VERSION ""

NS_ :

BS_:

BU_: SVB1 Tester Gateway CDS1 CDS2 ADV IRC AVP AVM PDC ADB1 ADB2 HDMAP DSM Fradar LCDA1 LCDA2

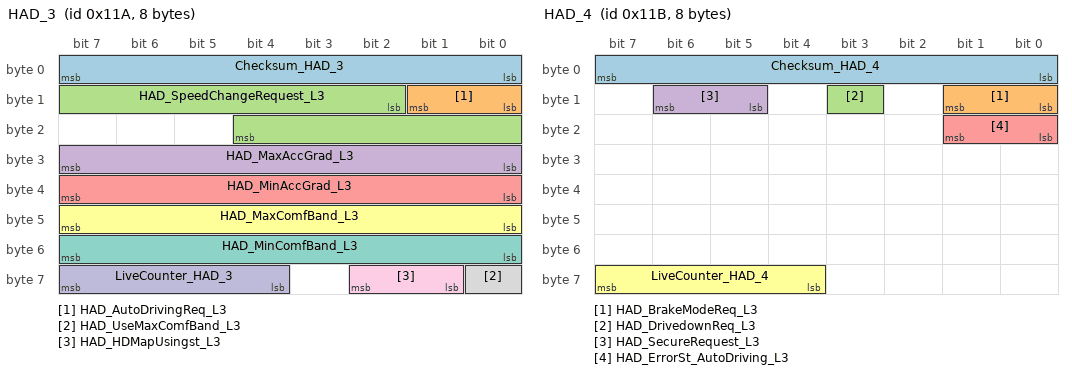
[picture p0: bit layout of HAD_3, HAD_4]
BO_ 282 HAD_3: 8 CDS1
 SG_ Checksum_HAD_3 : 0|8@1+ (1,0) [0|255] ""  Gateway,CDS2,HDMAP
 SG_ HAD_AutoDrivingReq_L3 : 8|2@1+ (1,0) [0|3] ""  Gateway,CDS2,HDMAP
 SG_ HAD_SpeedChangeRequest_L3 : 10|11@1+ (0.01,-10.21) [-10.21|10.26] "m/s2"  Gateway,CDS2,HDMAP
 SG_ HAD_MaxAccGrad_L3 : 24|8@1+ (0.1,0) [0|25.5] "m/s2"  Gateway,CDS2
 SG_ HAD_MinAccGrad_L3 : 32|8@1+ (0.1,0) [0|25.5] "m/s2"  Gateway,CDS2
 SG_ HAD_MaxComfBand_L3 : 40|8@1+ (0.05,0) [0|12.75] "/s2"  Gateway,CDS2
 SG_ HAD_MinComfBand_L3 : 48|8@1+ (0.05,0) [0|12.75] "/s2"  Gateway,CDS2
 SG_ HAD_UseMaxComfBand_L3 : 56|1@1+ (1,0) [0|1] ""  Gateway,CDS2
 SG_ HAD_HDMapUsingst_L3 : 57|2@1+ (1,0) [0|3] ""  HDMAP
 SG_ LiveCounter_HAD_3 : 60|4@1+ (1,0) [0|15] ""  Gateway,CDS2,HDMAP

BO_ 283 HAD_4: 8 CDS1
 SG_ Checksum_HAD_4 : 0|8@1+ (1,0) [0|255] ""  Gateway,CDS2,HDMAP
 SG_ HAD_BrakeModeReq_L3 : 8|2@1+ (1,0) [0|3] ""  Gateway,CDS2
 SG_ HAD_DrivedownReq_L3 : 11|1@1+ (1,0) [0|1] ""  Gateway,CDS2
 SG_ HAD_SecureRequest_L3 : 13|2@1+ (1,0) [0|3] ""  Gateway,CDS2
 SG_ HAD_ErrorSt_AutoDriving_L3 : 16|2@1+ (1,0) [0|3] ""  Gateway,CDS2
 SG_ LiveCounter_HAD_4 : 60|4@1+ (1,0) [0|15] ""  Gateway,CDS2,HDMAP

BO_ 278 HAD_6: 8 CDS1
 SG_ Checksum_HAD_6 : 0|8@1+ (1,0) [0|255] ""  Gateway,CDS2
 SG_ HAD_TorqueRequest : 8|10@1+ (0.01,0) [0|10.23] "Nm"  Gateway,CDS2
 SG_ HAD_TorqueRequestSign : 18|1@1+ (1,0) [0|1] ""  Gateway,CDS2
 SG_ HAD_TorqueReqSt : 19|1@1+ (1,0) [0|1] ""  Gateway,CDS2
 SG_ HAD_Intervention_LKA : 20|2@1+ (1,0) [0|3] ""  Gateway,CDS2
 SG_ HAD_WorkingSt_LKA : 22|2@1+ (1,0) [0|3] ""  Gateway,CDS2
 SG_ HAD_ErrorSt_LKA : 24|1@1+ (1,0) [0|1] ""  Gateway,CDS2
 SG_ HAD_TakeOverTip_LCA : 25|1@1+ (1,0) [0|1] ""  Gateway,CDS2
 SG_ HAD_HandsOffTip_LCA : 26|2@1+ (1,0) [0|3] ""  Gateway,CDS2
 SG_ HAD_WorkingSt_LCA : 28|3@1+ (1,0) [0|7] ""  Gateway,CDS2
 SG_ HAD_ErrorSt_LCA : 31|1@1+ (1,0) [0|1] ""  Gateway,CDS2
 SG_ HAD_AutoDrivingModeReq : 32|3@1+ (1,0) [0|7] ""  Gateway,CDS2
 SG_ HAD_ErrorSt_SACC : 40|2@1+ (1,0) [0|3] ""  Gateway,CDS2
 SG_ HAD_ErrorSt_HWP : 42|2@1+ (1,0) [0|3] ""  Gateway,CDS2
 SG_ HAD_ErrorSt_TJP : 44|2@1+ (1,0) [0|3] ""  Gateway,CDS2
 SG_ HAD_LDWSteeringVibrationReq : 47|1@1+ (1,0) [0|1] ""  Gateway,CDS2
 SG_ HAD_WorkingSt_DCLC : 50|3@1+ (1,0) [0|7] ""  Gateway,CDS2
 SG_ HAD_WorkingSt_HWP : 53|3@1+ (1,0) [0|7] ""  Gateway,CDS2
 SG_ HAD_WorkingSt_TJP : 56|3@1+ (1,0) [0|7] ""  Gateway,CDS2
 SG_ HAD_ErrorSt_HAD : 59|1@1+ (1,0) [0|1] ""  Gateway,CDS2
 SG_ LiveCounter_HAD_6 : 60|4@1+ (1,0) [0|15] ""  Gateway,CDS2

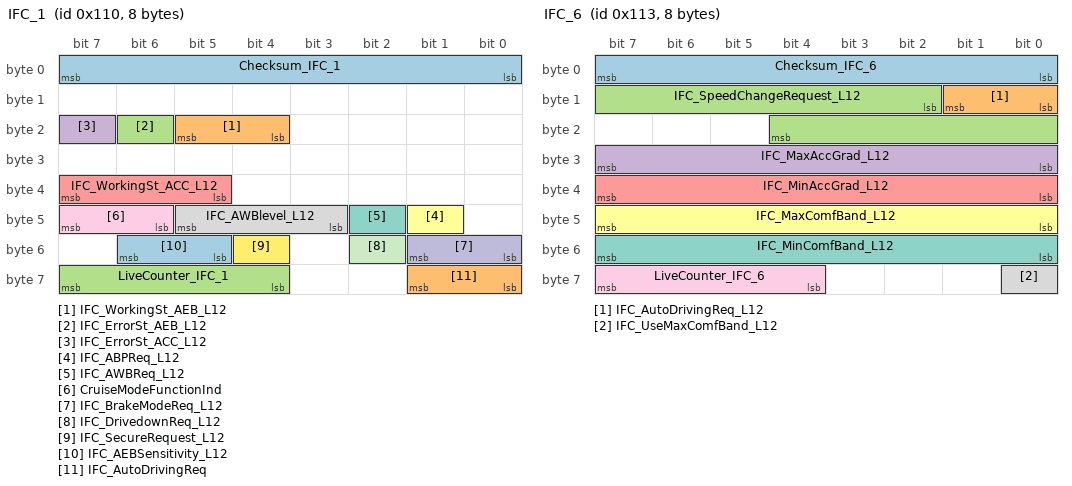
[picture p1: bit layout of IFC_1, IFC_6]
BO_ 272 IFC_1: 8 CDS2
 SG_ Checksum_IFC_1 : 0|8@1+ (1,0) [0|255] ""  Gateway,ADV
 SG_ IFC_WorkingSt_AEB_L12 : 20|2@1+ (1,0) [0|3] ""  Gateway
 SG_ IFC_ErrorSt_AEB_L12 : 22|1@1+ (1,0) [0|1] ""  Gateway,ADV
 SG_ IFC_ErrorSt_ACC_L12 : 23|1@1+ (1,0) [0|1] ""  Gateway
 SG_ IFC_WorkingSt_ACC_L12 : 37|3@1+ (1,0) [0|7] ""  Gateway,ADV
 SG_ IFC_ABPReq_L12 : 41|1@1+ (1,0) [0|1] ""  Gateway
 SG_ IFC_AWBReq_L12 : 42|1@1+ (1,0) [0|1] ""  Gateway
 SG_ IFC_AWBlevel_L12 : 43|3@1+ (1,0) [0|7] ""  Gateway
 SG_ CruiseModeFunctionInd : 46|2@1+ (1,0) [0|3] ""  Gateway
 SG_ IFC_BrakeModeReq_L12 : 48|2@1+ (1,0) [0|3] ""  Gateway
 SG_ IFC_DrivedownReq_L12 : 50|1@1+ (1,0) [0|1] ""  Gateway
 SG_ IFC_SecureRequest_L12 : 52|1@1+ (1,0) [0|1] ""  Gateway
 SG_ IFC_AEBSensitivity_L12 : 53|2@1+ (1,0) [0|3] ""  Gateway
 SG_ IFC_AutoDrivingReq : 56|2@1+ (1,0) [0|3] ""  Gateway
 SG_ LiveCounter_IFC_1 : 60|4@1+ (1,0) [0|15] ""  Gateway,ADV

BO_ 275 IFC_6: 8 CDS2
 SG_ Checksum_IFC_6 : 0|8@1+ (1,0) [0|255] ""  Gateway
 SG_ IFC_AutoDrivingReq_L12 : 8|2@1+ (1,0) [0|3] ""  Gateway
 SG_ IFC_SpeedChangeRequest_L12 : 10|11@1+ (0.01,-10.21) [-10.21|10.26] "m/s2"  Gateway
 SG_ IFC_MaxAccGrad_L12 : 24|8@1+ (0.1,0) [0|25.5] "m/s2"  Gateway
 SG_ IFC_MinAccGrad_L12 : 32|8@1+ (0.1,0) [0|25.5] "m/s2"  Gateway
 SG_ IFC_MaxComfBand_L12 : 40|8@1+ (0.05,0) [0|12.75] "/s2"  Gateway
 SG_ IFC_MinComfBand_L12 : 48|8@1+ (0.05,0) [0|12.75] "/s2"  Gateway
 SG_ IFC_UseMaxComfBand_L12 : 56|1@1+ (1,0) [0|1] ""  Gateway
 SG_ LiveCounter_IFC_6 : 60|4@1+ (1,0) [0|15] ""  Gateway

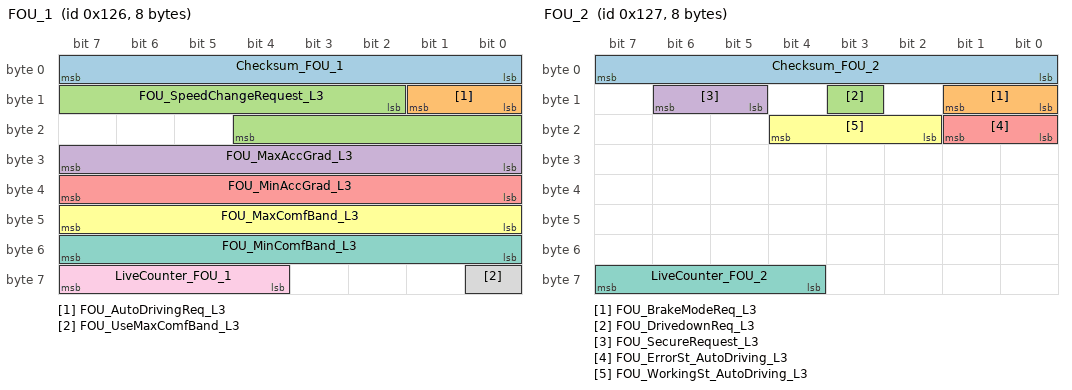
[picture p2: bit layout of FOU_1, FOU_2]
BO_ 294 FOU_1: 8 CDS2
 SG_ Checksum_FOU_1 : 0|8@1+ (1,0) [0|255] ""  Gateway,CDS1
 SG_ FOU_AutoDrivingReq_L3 : 8|2@1+ (1,0) [0|3] ""  Gateway,CDS1
 SG_ FOU_SpeedChangeRequest_L3 : 10|11@1+ (0.01,-10.21) [-10.21|10.26] "m/s2"  Gateway,CDS1
 SG_ FOU_MaxAccGrad_L3 : 24|8@1+ (0.1,0) [0|25.5] "m/s2"  Gateway,CDS1
 SG_ FOU_MinAccGrad_L3 : 32|8@1+ (0.1,0) [0|25.5] "m/s2"  Gateway,CDS1
 SG_ FOU_MaxComfBand_L3 : 40|8@1+ (0.05,0) [0|12.75] "/s2"  Gateway,CDS1
 SG_ FOU_MinComfBand_L3 : 48|8@1+ (0.05,0) [0|12.75] "/s2"  Gateway,CDS1
 SG_ FOU_UseMaxComfBand_L3 : 56|1@1+ (1,0) [0|1] ""  Gateway,CDS1
 SG_ LiveCounter_FOU_1 : 60|4@1+ (1,0) [0|15] ""  Gateway,CDS1

BO_ 295 FOU_2: 8 CDS2
 SG_ Checksum_FOU_2 : 0|8@1+ (1,0) [0|255] ""  Gateway,CDS1
 SG_ FOU_BrakeModeReq_L3 : 8|2@1+ (1,0) [0|3] ""  Gateway,CDS1
 SG_ FOU_DrivedownReq_L3 : 11|1@1+ (1,0) [0|1] ""  Gateway,CDS1
 SG_ FOU_SecureRequest_L3 : 13|2@1+ (1,0) [0|3] ""  Gateway,CDS1
 SG_ FOU_ErrorSt_AutoDriving_L3 : 16|2@1+ (1,0) [0|3] ""  Gateway,CDS1
 SG_ FOU_WorkingSt_AutoDriving_L3 : 18|3@1+ (1,0) [0|7] ""  Gateway,CDS1
 SG_ LiveCounter_FOU_2 : 60|4@1+ (1,0) [0|15] ""  Gateway,CDS1

BO_ 274 IFC_4: 8 CDS2
 SG_ Checksum_IFC_4 : 0|8@1+ (1,0) [0|255] ""  Gateway,CDS1,ADV
 SG_ IFC_TorqueRequest : 8|10@1+ (0.01,0) [0|10.23] "Nm"  Gateway,CDS1
 SG_ IFC_TorqueRequestSign : 18|1@1+ (1,0) [0|1] ""  Gateway,CDS1
 SG_ IFC_TorqueReqSt : 19|1@1+ (1,0) [0|1] ""  Gateway,CDS1
 SG_ IFC_Intervention_LKA : 20|2@1+ (1,0) [0|3] ""  Gateway,CDS1
 SG_ IFC_WorkingSt_LKA : 22|2@1+ (1,0) [0|3] ""  Gateway,CDS1,ADV
 SG_ IFC_ErrorSt_LKA : 24|1@1+ (1,0) [0|1] ""  Gateway,CDS1
 SG_ IFC_TakeOverTip_LCA : 25|1@1+ (1,0) [0|1] ""  Gateway,CDS1
 SG_ IFC_HandsOffTip_LCA : 26|2@1+ (1,0) [0|3] ""  Gateway,CDS1
 SG_ IFC_WorkingSt_LCA : 28|3@1+ (1,0) [0|7] ""  Gateway,CDS1,ADV
 SG_ IFC_ErrorSt_LCA : 31|1@1+ (1,0) [0|1] ""  Gateway,CDS1
 SG_ IFC_AutoDrivingModeReq : 32|3@1+ (1,0) [0|7] ""  Gateway,CDS1
 SG_ IFC_ErrorSt_SACC : 40|2@1+ (1,0) [0|3] ""  Gateway,CDS1
 SG_ FOU_ErrorSt_HWP : 42|2@1+ (1,0) [0|3] ""  Gateway,CDS1
 SG_ FOU_ErrorSt_TJP : 44|2@1+ (1,0) [0|3] ""  Gateway,CDS1
 SG_ LDWSteeringVibrationReq : 47|1@1+ (1,0) [0|1] ""  Gateway,CDS1
 SG_ IFC_WorkingSt_SACC : 50|3@1+ (1,0) [0|7] ""  Gateway,CDS1,ADV
 SG_ FOU_WorkingSt_HWP : 53|3@1+ (1,0) [0|7] ""  Gateway,CDS1
 SG_ FOU_WorkingSt_TJP : 56|3@1+ (1,0) [0|7] ""  Gateway,CDS1
 SG_ IFC_ErrorSt_FOU : 59|1@1+ (1,0) [0|1] ""  Gateway
 SG_ LiveCounter_IFC_4 : 60|4@1+ (1,0) [0|15] ""  Gateway,CDS1,ADV

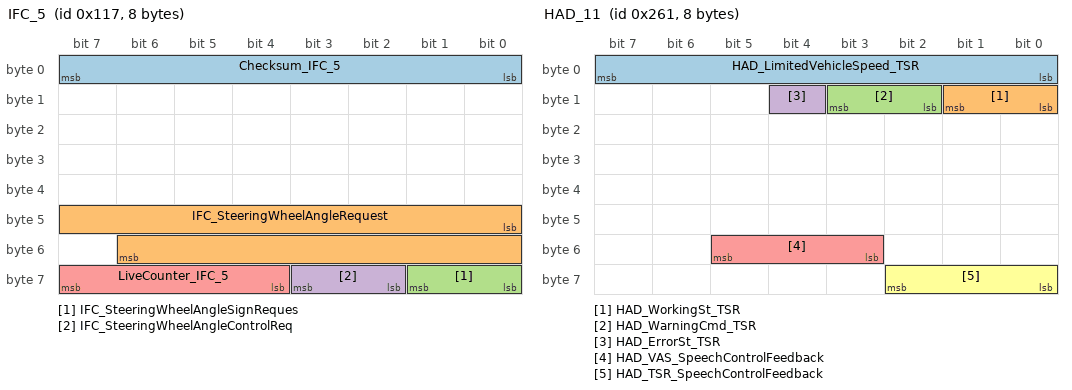
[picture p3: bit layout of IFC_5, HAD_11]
BO_ 279 IFC_5: 8 CDS2
 SG_ Checksum_IFC_5 : 0|8@1+ (1,0) [0|255] ""  Gateway,CDS1
 SG_ IFC_SteeringWheelAngleRequest : 40|15@1+ (0.04375,0) [0|1433.55625] "°„"  Gateway,CDS1
 SG_ IFC_SteeringWheelAngleSignReques : 56|2@1+ (1,0) [0|3] ""  Gateway,CDS1
 SG_ IFC_SteeringWheelAngleControlReq : 58|2@1+ (1,0) [0|3] ""  Gateway,CDS1
 SG_ LiveCounter_IFC_5 : 60|4@1+ (1,0) [0|15] "Pulse"  Gateway,CDS1

BO_ 607 HAD_10: 8 CDS1
 SG_ HAD_CruiseSpeedSetting_ACC : 0|8@1+ (1,0) [0|255] "km/h"  Gateway,CDS2
 SG_ HAD_TimeGapSetting : 8|3@1+ (1,0) [0|7] ""  Gateway,CDS2
 SG_ HAD_ObjectDetection : 11|1@1+ (1,0) [0|1] ""  Gateway,CDS2
 SG_ HAD_SysTextinfo : 12|4@1+ (1,0) [0|15] ""  Gateway,CDS2
 SG_ HAD_LDWModeInd : 16|2@1+ (1,0) [0|3] ""  Gateway,CDS2
 SG_ HAD_TakeOverReq : 19|1@1+ (1,0) [0|1] ""  Gateway,CDS2
 SG_ HAD_AutoLightModeReq : 20|1@1+ (1,0) [0|1] ""  Gateway,CDS2
 SG_ HAD_HazardWarningLampRequest : 21|1@1+ (1,0) [0|1] ""  Gateway,CDS2
 SG_ HAD_WorkingSt_LDW : 24|2@1+ (1,0) [0|3] ""  Gateway,CDS2
 SG_ HAD_WarningCmd_LDW : 26|2@1+ (1,0) [0|3] ""  Gateway,CDS2
 SG_ HAD_LDWLaneDetectSt : 28|2@1+ (1,0) [0|3] ""  Gateway,CDS2
 SG_ HAD_SensitivityInd_LDW : 30|2@1+ (1,0) [0|3] ""  Gateway,CDS2
 SG_ HAD_ErrorSt_LDW : 32|1@1+ (1,0) [0|1] ""  Gateway,CDS2,ADV
 SG_ HAD_WorkingSt_FCW : 33|2@1+ (1,0) [0|3] ""  Gateway,CDS2
 SG_ HAD_WarningCmd_FCW : 35|2@1+ (1,0) [0|3] ""  Gateway,CDS2
 SG_ HAD_ErrorSt_FCW : 37|1@1+ (1,0) [0|1] ""  Gateway,CDS2,ADV
 SG_ HAD_SensitivityInd_FCW : 38|2@1+ (1,0) [0|3] ""  Gateway,CDS2
 SG_ HAD_FCWModeInd : 40|2@1+ (1,0) [0|3] ""  Gateway,CDS2
 SG_ HAD_WiperAutoLeverReq : 42|1@1+ (1,0) [0|1] ""  Gateway,CDS2
 SG_ HAD_SACCNotSatisfiedCondition : 43|3@1+ (1,0) [0|7] ""  Gateway,CDS2
 SG_ HAD_LDW_SpeechControlFeedback : 48|3@1+ (1,0) [0|7] ""  Gateway,CDS2
 SG_ HAD_VASFunctionInd : 51|1@1+ (1,0) [0|1] ""  Gateway,CDS2
 SG_ HAD_IFCSystemError : 52|2@1+ (1,0) [0|3] ""  Gateway,CDS2
 SG_ HAD_IFCCalibrationStatus : 54|2@1+ (1,0) [0|3] ""  Gateway,CDS2
 SG_ HAD_WarningCmd_VAS : 56|1@1+ (1,0) [0|1] ""  Gateway,CDS2
 SG_ HAD_LeftTurningLampRequest : 57|2@1+ (1,0) [0|3] ""  Gateway,CDS2
 SG_ HAD_RightTurningLampRequest : 59|2@1+ (1,0) [0|3] ""  Gateway,CDS2
 SG_ HAD_ValetModeStatus : 61|1@1+ (1,0) [0|1] ""  Gateway

BO_ 608 IFC_2: 8 CDS2
 SG_ CruiseSpeedSetting_ACC : 0|8@1+ (1,0) [0|255] "km/h"  Gateway
 SG_ TimeGapSetting : 8|3@1+ (1,0) [0|7] ""  Gateway
 SG_ ObjectDetection : 11|1@1+ (1,0) [0|1] ""  Gateway
 SG_ SysTextinfo : 12|4@1+ (1,0) [0|15] ""  Gateway
 SG_ LDWModeInd : 16|2@1+ (1,0) [0|3] ""  Gateway
 SG_ TakeOverReq : 19|1@1+ (1,0) [0|1] ""  Gateway
 SG_ AutoLightModeReq : 20|1@1+ (1,0) [0|1] ""  Gateway
 SG_ HazardWarningLampRequest : 21|1@1+ (1,0) [0|1] ""  Gateway
 SG_ WorkingSt_LDW : 24|2@1+ (1,0) [0|3] ""  Gateway
 SG_ WarningCmd_LDW : 26|2@1+ (1,0) [0|3] ""  Gateway
 SG_ LDWLaneDetectSt : 28|2@1+ (1,0) [0|3] ""  Gateway
 SG_ SensitivityInd_LDW : 30|2@1+ (1,0) [0|3] ""  Gateway
 SG_ ErrorSt_LDW : 32|1@1+ (1,0) [0|1] ""  Gateway,ADV
 SG_ WorkingSt_FCW : 33|2@1+ (1,0) [0|3] ""  Gateway
 SG_ WarningCmd_FCW : 35|2@1+ (1,0) [0|3] ""  Gateway
 SG_ ErrorSt_FCW : 37|1@1+ (1,0) [0|1] ""  Gateway,ADV
 SG_ SensitivityInd_FCW : 38|2@1+ (1,0) [0|3] ""  Gateway
 SG_ FCWModeInd : 40|2@1+ (1,0) [0|3] ""  Gateway
 SG_ WiperAutoLeverReq : 42|1@1+ (1,0) [0|1] ""  Gateway
 SG_ SACCNotSatisfiedCondition : 43|3@1+ (1,0) [0|7] ""  Gateway
 SG_ LDW_SpeechControlFeedback : 48|3@1+ (1,0) [0|7] ""  Gateway
 SG_ VASFunctionInd : 51|1@1+ (1,0) [0|1] ""  Gateway
 SG_ IFCSystemError : 52|2@1+ (1,0) [0|3] ""  Gateway
 SG_ IFCCalibrationStatus : 54|2@1+ (1,0) [0|3] ""  Gateway
 SG_ WarningCmd_VAS : 56|1@1+ (1,0) [0|1] ""  Gateway
 SG_ IFC_LeftTurningLampRequest : 57|2@1+ (1,0) [0|3] ""  Gateway
 SG_ IFC_RightTurningLampRequest : 59|2@1+ (1,0) [0|3] ""  Gateway

BO_ 609 HAD_11: 8 CDS1
 SG_ HAD_LimitedVehicleSpeed_TSR : 0|8@1+ (1,0) [0|255] ""  Gateway
 SG_ HAD_WorkingSt_TSR : 8|2@1+ (1,0) [0|3] ""  Gateway
 SG_ HAD_WarningCmd_TSR : 10|2@1+ (1,0) [0|3] ""  Gateway
 SG_ HAD_ErrorSt_TSR : 12|1@1+ (1,0) [0|1] ""  Gateway
 SG_ HAD_VAS_SpeechControlFeedback : 51|3@1+ (1,0) [0|7] ""  Gateway
 SG_ HAD_TSR_SpeechControlFeedback : 56|3@1+ (1,0) [0|7] ""  Gateway

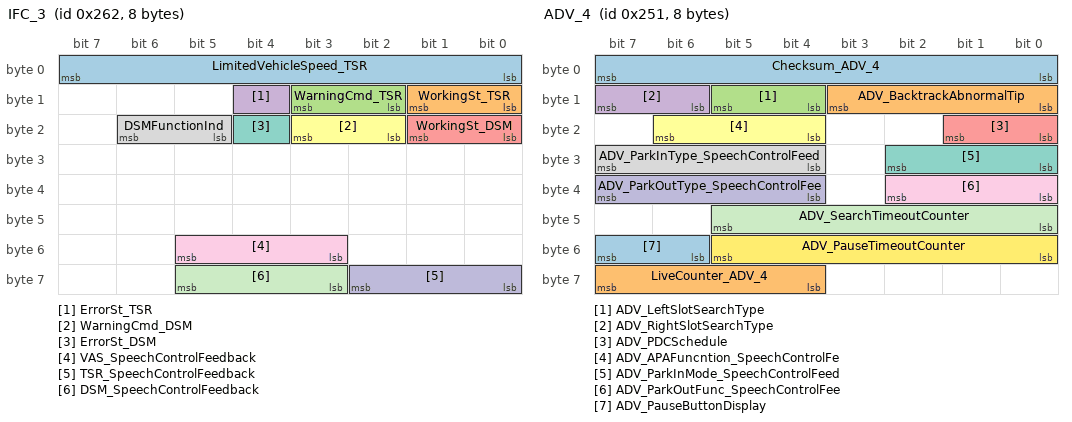
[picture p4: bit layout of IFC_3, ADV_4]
BO_ 610 IFC_3: 8 CDS2
 SG_ LimitedVehicleSpeed_TSR : 0|8@1+ (1,0) [0|255] ""  Gateway
 SG_ WorkingSt_TSR : 8|2@1+ (1,0) [0|3] ""  Gateway
 SG_ WarningCmd_TSR : 10|2@1+ (1,0) [0|3] ""  Gateway
 SG_ ErrorSt_TSR : 12|1@1+ (1,0) [0|1] ""  Gateway
 SG_ WorkingSt_DSM : 16|2@1+ (1,0) [0|3] ""  Gateway
 SG_ WarningCmd_DSM : 18|2@1+ (1,0) [0|3] ""  Gateway
 SG_ ErrorSt_DSM : 20|1@1+ (1,0) [0|1] ""  Gateway
 SG_ DSMFunctionInd : 21|2@1+ (1,0) [0|3] ""  Gateway
 SG_ VAS_SpeechControlFeedback : 51|3@1+ (1,0) [0|7] ""  Gateway
 SG_ TSR_SpeechControlFeedback : 56|3@1+ (1,0) [0|7] ""  Gateway
 SG_ DSM_SpeechControlFeedback : 59|3@1+ (1,0) [0|7] ""  Gateway

BO_ 611 IFC_11: 8 CDS2
 SG_ Checksum_IFC_11 : 0|8@1+ (1,0) [0|255] "" Vector__XXX
 SG_ HAD_AutoDrivingSt : 8|4@1+ (1,0) [0|15] "" Vector__XXX

BO_ 592 ADV_1: 8 CDS1
 SG_ Checksum_ADV_1 : 0|8@1+ (1,0) [0|255] ""  Gateway,CDS2,AVP,AVM,PDC
 SG_ ADV_ParkType : 8|3@1+ (1,0) [0|7] ""  Gateway,AVP,AVM
 SG_ ADV_ParkInSlotSearchMode : 11|1@1+ (1,0) [0|1] ""  Gateway,AVP,AVM
 SG_ ADV_ParkStatus : 12|4@1+ (1,0) [0|15] ""  Gateway,CDS2,AVP,AVM,PDC
 SG_ ADV_SystemError : 16|1@1+ (1,0) [0|1] ""  Gateway
 SG_ ADV_ParkInAvaialble : 17|1@1+ (1,0) [0|1] ""  Gateway
 SG_ ADV_ParkOutAvaialble : 18|1@1+ (1,0) [0|1] ""  Gateway
 SG_ ADV_ParkInReady : 19|1@1+ (1,0) [0|1] ""  Gateway
 SG_ ADV_ParkOutReady : 20|1@1+ (1,0) [0|1] ""  Gateway
 SG_ ADV_ParkOutDirection : 21|3@1+ (1,0) [0|7] ""  Gateway,AVP,AVM
 SG_ ADV_VehicleModeRequest : 24|2@1+ (1,0) [0|3] ""  Gateway
 SG_ ADV_BrakeLightCtrlCmd : 27|1@1+ (1,0) [0|1] ""  Gateway
 SG_ ADV_HazardWarningLampRequest : 28|2@1+ (1,0) [0|3] ""  Gateway
 SG_ ADV_DoorRequest : 30|2@1+ (1,0) [0|3] ""  Gateway
 SG_ ADV_LeftTurningLampRequest : 32|2@1+ (1,0) [0|3] ""  Gateway
 SG_ ADV_RightTurningLampRequest : 34|2@1+ (1,0) [0|3] ""  Gateway
 SG_ ADV_EngineAndEVStopRequest : 36|2@1+ (1,0) [0|3] ""  Gateway
 SG_ ADV_FunctionAbnormalTip : 40|6@1+ (1,0) [0|63] ""  Gateway,AVP,AVM
 SG_ ADV_ParkInEnabled : 46|1@1+ (1,0) [0|1] ""  Gateway
 SG_ ADV_ParkOutEnabled : 47|1@1+ (1,0) [0|1] ""  Gateway
 SG_ ADV_TimeoutCounter : 48|6@1+ (1,0) [0|63] "seconds"  Gateway
 SG_ ADV_ParkingStep : 54|2@1+ (1,0) [0|3] ""  Gateway
 SG_ ADV_RearViewMirrorFoldRequest : 56|2@1+ (1,0) [0|3] ""  Gateway
 SG_ ADV_ParkingAEBFunctionInd : 58|1@1+ (1,0) [0|1] ""  Gateway,PDC
 SG_ ADV_BacktrackFunctionInd : 59|1@1+ (1,0) [0|1] ""  Gateway,AVP
 SG_ LiveCounter_ADV_1 : 60|4@1+ (1,0) [0|15] "Pulse"  Gateway,CDS2,AVP,AVM,PDC

BO_ 593 ADV_4: 8 CDS1
 SG_ Checksum_ADV_4 : 0|8@1+ (1,0) [0|255] ""  Gateway,AVP,AVM
 SG_ ADV_BacktrackAbnormalTip : 8|4@1+ (1,0) [0|7] ""  Gateway
 SG_ ADV_LeftSlotSearchType : 12|2@1+ (1,0) [0|3] ""  PDC
 SG_ ADV_RightSlotSearchType : 14|2@1+ (1,0) [0|3] ""  PDC
 SG_ ADV_PDCSchedule : 16|2@1+ (1,0) [0|3] ""  PDC
 SG_ ADV_APAFuncntion_SpeechControlFe : 20|3@1+ (1,0) [0|7] ""  Gateway
 SG_ ADV_ParkInMode_SpeechControlFeed : 24|3@1+ (1,0) [0|7] ""  Gateway
 SG_ ADV_ParkInType_SpeechControlFeed : 28|4@1+ (1,0) [0|7] ""  Gateway
 SG_ ADV_ParkOutFunc_SpeechControlFee : 32|3@1+ (1,0) [0|7] ""  Gateway
 SG_ ADV_ParkOutType_SpeechControlFee : 36|4@1+ (1,0) [0|15] ""  Gateway
 SG_ ADV_SearchTimeoutCounter : 40|6@1+ (1,0) [0|63] "seconds"  Gateway,AVP,AVM
 SG_ ADV_PauseTimeoutCounter : 48|6@1+ (1,0) [0|63] "seconds"  Gateway
 SG_ ADV_PauseButtonDisplay : 54|2@1+ (1,0) [0|3] ""  Gateway
 SG_ LiveCounter_ADV_4 : 60|4@1+ (1,0) [0|15] "Pulse"  Gateway,AVP,AVM

BO_ 613 HAD_5: 8 CDS1
 SG_ Checksum_HAD_5 : 0|8@1+ (1,0) [0|255] ""  Gateway,AVP,DSM
 SG_ HAD_SystemError_AVP : 8|1@1+ (1,0) [0|1] ""  Gateway,DSM
 SG_ HAD_ParkingLotAvalableTip_AVP : 9|3@1+ (1,0) [0|7] ""  Gateway
 SG_ HAD_AIUnavailableTip : 12|1@1+ (1,0) [0|1] ""  Gateway
 SG_ HAD_ValetModeTip_AVP : 13|1@1+ (1,0) [0|1] ""  Gateway
 SG_ HAD_ChangeLaneManualsuccess_Tip : 14|1@1+ (1,0) [0|1] ""  Gateway
 SG_ HAD_SetdestinationFuncSt : 15|1@1+ (1,0) [0|1] ""  Gateway
 SG_ HAD_SetdestinationTip : 16|2@1+ (1,0) [0|3] ""  Gateway
 SG_ HAD_WorkingSt_HWP_Display : 18|4@1+ (1,0) [0|15] ""  Gateway,AVP,DSM
 SG_ HAD_TakeoverReq_L3 : 22|1@1+ (1,0) [0|1] ""  Gateway,DSM
 SG_ HAD_ChangeLaneManualFuncSt : 23|1@1+ (1,0) [0|1] ""  Gateway
 SG_ HAD_WorkingSt_TJP_Display : 24|4@1+ (1,0) [0|15] ""  Gateway,AVP,DSM
 SG_ HAD_LateralTakeOverReq_L3 : 28|1@1+ (1,0) [0|1] ""  Gateway,DSM
 SG_ HAD_AutoDrivingStyle : 29|2@1+ (1,0) [0|3] ""  Gateway
 SG_ HAD_ChangeLaneAutoFuncSt : 31|1@1+ (1,0) [0|1] ""  Gateway
 SG_ HAD_TOR_Tips : 32|4@1+ (1,0) [0|15] ""  Gateway
 SG_ HAD_AutoDrivingNotSatisfiedCondi : 36|4@1+ (1,0) [0|15] ""  Gateway
 SG_ HAD_DistractionWarning : 40|1@1+ (1,0) [0|1] ""  Gateway
 SG_ HAD_AttentionSt : 41|1@1+ (1,0) [0|1] ""  Gateway
 SG_ HAD_TakeOverWarning_L3 : 42|3@1+ (1,0) [0|7] ""  Gateway
 SG_ HAD_TakeOverSuccessTip_L3 : 45|3@1+ (1,0) [0|7] ""  Gateway
 SG_ HAD_ChangeLaneManual_Feedback : 48|3@1+ (1,0) [0|7] ""  Gateway
 SG_ HAD_ErrorSt_HWPTJP : 51|1@1+ (1,0) [0|1] ""  Gateway,DSM
 SG_ HAD_Countdown_Takeover : 52|3@1+ (1,0) [0|7] ""  Gateway
 SG_ HAD_Destinationtip_St : 55|1@1+ (1,0) [0|1] ""  Gateway
 SG_ HAD_Countdown_SafeStop : 56|3@1+ (1,0) [0|7] ""  Gateway
 SG_ HAD_SACCActiveForbidden : 59|1@1+ (1,0) [0|1] ""  Gateway
 SG_ LiveCounter_HAD_5 : 60|4@1+ (1,0) [0|15] "Pulse"  Gateway,AVP,DSM

BO_ 595 ADV_5: 8 CDS1
 SG_ Checksum_ADV_5 : 0|8@1+ (1,0) [0|255] ""  Gateway
 SG_ ADV_CIDLocationReq : 8|1@1+ (1,0) [0|1] ""  Gateway
 SG_ ADV_PositionLightReq : 9|2@1+ (1,0) [0|3] ""  Gateway
 SG_ ADV_FogLightReq_Front : 11|2@1+ (1,0) [0|3] ""  Gateway
 SG_ ADV_FogLightReq_Rear : 13|2@1+ (1,0) [0|3] ""  Gateway
 SG_ ADV_AVPHazardWarningFunctionInd : 16|1@1+ (1,0) [0|1] ""  Gateway
 SG_ ADV_HPAHazardWarningFunctionInd : 17|1@1+ (1,0) [0|1] ""  Gateway
 SG_ ADV_AVPTypeIndication : 18|2@1+ (1,0) [0|3] ""  Gateway
 SG_ ADV_AVPSearchingTypeInd : 20|1@1+ (1,0) [0|1] ""  Gateway
 SG_ ADV_HPATypeIndication : 21|2@1+ (1,0) [0|3] ""  Gateway
 SG_ ADV_HPASearchingTypeInd : 23|1@1+ (1,0) [0|1] ""  Gateway
 SG_ ADV_AVPParkingLotPushFunctionInd : 24|1@1+ (1,0) [0|1] ""  Gateway
 SG_ ADV_HPAParkingLotPushFunctionInd : 25|1@1+ (1,0) [0|1] ""  Gateway
 SG_ ADV_AVPNaviAvaialble : 26|1@1+ (1,0) [0|1] ""  Gateway
 SG_ ADV_AVPParkInAvaialble : 27|1@1+ (1,0) [0|1] ""  Gateway,PDC
 SG_ ADV_AVPParkOutAvaialble : 28|1@1+ (1,0) [0|1] ""  Gateway,PDC
 SG_ ADV_AVPParkInReady : 29|1@1+ (1,0) [0|1] ""  Gateway
 SG_ ADV_AVPParkOutReady : 30|1@1+ (1,0) [0|1] ""  Gateway
 SG_ ADV_HPANaviAvaialble : 31|1@1+ (1,0) [0|1] ""  Gateway
 SG_ ADV_HPAParkInAvaialble : 32|1@1+ (1,0) [0|1] ""  Gateway,PDC
 SG_ ADV_HPAParkOutAvaialble : 33|1@1+ (1,0) [0|1] ""  Gateway,PDC
 SG_ ADV_HPAParkInReady : 34|1@1+ (1,0) [0|1] ""  Gateway
 SG_ ADV_HPAParkOutReady : 35|1@1+ (1,0) [0|1] ""  Gateway
 SG_ ADV_AVPSuspendStatus : 36|1@1+ (1,0) [0|1] ""  Gateway
 SG_ ADV_HPAFucntion_SpeechControlFee : 37|3@1+ (1,0) [0|7] ""  Gateway
 SG_ ADV_SunRoofRequest : 40|2@1+ (1,0) [0|3] ""  Gateway
 SG_ ADV_AllWindowsCloseReq : 42|2@1+ (1,0) [0|3] ""  Gateway
 SG_ ADV_OvertakingLightReq : 44|2@1+ (1,0) [0|3] ""  Gateway
 SG_ ADV_LowBeamReq : 46|2@1+ (1,0) [0|3] ""  Gateway
 SG_ ADV_HighBeamReq : 48|2@1+ (1,0) [0|3] ""  Gateway
 SG_ ADV_AntitheftAlarmReq : 50|2@1+ (1,0) [0|3] ""  Gateway
 SG_ ADV_CeremonyModeReq : 52|3@1+ (1,0) [0|7] ""  Gateway
 SG_ ADV_HornReq : 55|1@1+ (1,0) [0|1] ""  Gateway
 SG_ ADV_AVPFucntion_SpeechControlFee : 56|3@1+ (1,0) [0|7] ""  Gateway
 SG_ ADV_HPASuspendStatus : 59|1@1+ (1,0) [0|1] ""  Gateway
 SG_ LiveCounter_ADV_5 : 60|4@1+ (1,0) [0|15] "Pulse"  Gateway

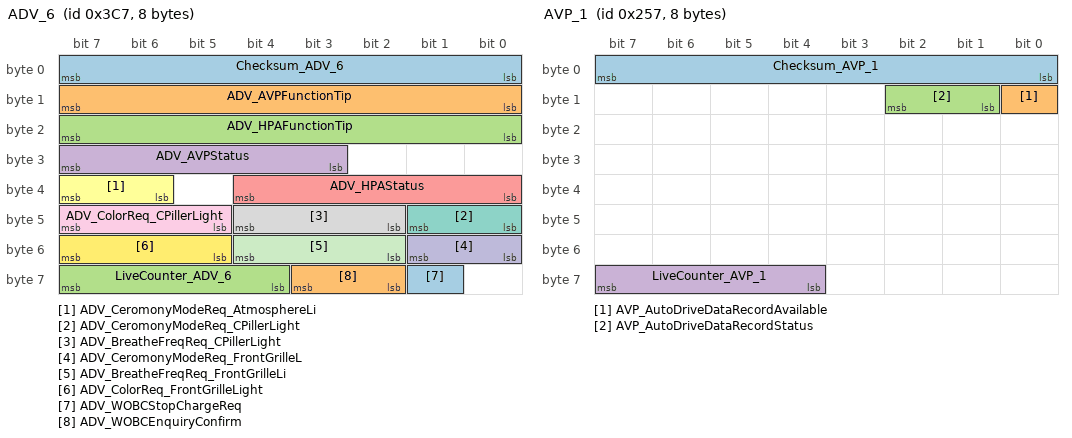
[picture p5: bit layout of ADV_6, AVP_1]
BO_ 967 ADV_6: 8 CDS1
 SG_ Checksum_ADV_6 : 0|8@1+ (1,0) [0|255] ""  Gateway
 SG_ ADV_AVPFunctionTip : 8|8@1+ (1,0) [0|255] ""  Gateway
 SG_ ADV_HPAFunctionTip : 16|8@1+ (1,0) [0|255] ""  Gateway
 SG_ ADV_AVPStatus : 27|5@1+ (1,0) [0|31] ""  Gateway,AVP,PDC
 SG_ ADV_HPAStatus : 32|5@1+ (1,0) [0|31] ""  Gateway,AVP,PDC
 SG_ ADV_CeromonyModeReq_AtmosphereLi : 38|2@1+ (1,0) [0|3] ""  Gateway
 SG_ ADV_CeromonyModeReq_CPillerLight : 40|2@1+ (1,0) [0|3] ""  Gateway
 SG_ ADV_BreatheFreqReq_CPillerLight : 42|3@1+ (1,0) [0|7] ""  Gateway
 SG_ ADV_ColorReq_CPillerLight : 45|3@1+ (1,0) [0|7] ""  Gateway
 SG_ ADV_CeromonyModeReq_FrontGrilleL : 48|2@1+ (1,0) [0|3] ""  Gateway
 SG_ ADV_BreatheFreqReq_FrontGrilleLi : 50|3@1+ (1,0) [0|7] ""  Gateway
 SG_ ADV_ColorReq_FrontGrilleLight : 53|3@1+ (1,0) [0|7] ""  Gateway
 SG_ ADV_WOBCStopChargeReq : 57|1@1+ (1,0) [0|1] ""  Gateway
 SG_ ADV_WOBCEnquiryConfirm : 58|2@1+ (1,0) [0|3] ""  Gateway
 SG_ LiveCounter_ADV_6 : 60|4@1+ (1,0) [0|15] "Pulse"  Gateway

BO_ 600 AVS_1: 8 AVP
 SG_ AVSSt : 0|1@1+ (1,0) [0|1] ""  Gateway,ADV,PDC
 SG_ AVSErrorSt : 1|1@1+ (1,0) [0|1] ""  Gateway,ADV
 SG_ AVSViewMode : 2|4@1+ (1,0) [0|15] ""  Gateway
 SG_ AVSViewtype : 6|2@1+ (1,0) [0|3] ""  Gateway
 SG_ AVSCameraErrorSt_Front : 8|1@1+ (1,0) [0|1] ""  Gateway,ADV
 SG_ AVSCameraErrorSt_Rear : 9|1@1+ (1,0) [0|1] ""  Gateway,ADV
 SG_ AVSCameraErrorSt_Left : 10|1@1+ (1,0) [0|1] ""  Gateway,ADV
 SG_ AVSCameraErrorSt_Right : 11|1@1+ (1,0) [0|1] ""  Gateway,ADV
 SG_ LanguageTypeSt_AVS : 12|4@1+ (1,0) [0|15] ""  Gateway
 SG_ DynamicPGSSt_AVS : 16|1@1+ (1,0) [0|1] ""  Gateway
 SG_ MODSt_AVS : 17|1@1+ (1,0) [0|1] ""  Gateway
 SG_ MODWarning_Front : 18|1@1+ (1,0) [0|1] ""  Gateway,ADV
 SG_ MODWarning_Rear : 19|1@1+ (1,0) [0|1] ""  Gateway,ADV
 SG_ SwitchScreenRequest_AVS : 24|2@1+ (1,0) [0|3] ""  Gateway
 SG_ BlindSpotFilledFunctionInd : 26|1@1+ (1,0) [0|1] ""  Gateway
 SG_ FoundSlotBuzzerTip : 27|1@1+ (1,0) [0|1] ""  Gateway
 SG_ AVS_SpeechControlFeedback : 32|5@1+ (1,0) [0|31] ""  Gateway
 SG_ AVSCameraBlockageSt_Front : 37|1@1+ (1,0) [0|1] ""  Gateway,ADV
 SG_ AVSCameraBlockageSt_Rear : 38|1@1+ (1,0) [0|1] ""  Gateway,ADV
 SG_ AVSCameraBlockageSt_Left : 39|1@1+ (1,0) [0|1] ""  Gateway,ADV
 SG_ AVSCameraBlockageSt_Right : 40|1@1+ (1,0) [0|1] ""  Gateway,ADV
 SG_ AVS_AbnormalTip : 41|3@1+ (1,0) [0|7] ""  Gateway
 SG_ AVS_CalibrationSt : 44|2@1+ (1,0) [0|3] ""  ADV
 SG_ AVS_PDWarning_Front : 46|1@1+ (1,0) [0|1] ""  Gateway,ADV
 SG_ AVS_PDWarning_Rear : 47|1@1+ (1,0) [0|1] ""  Gateway,ADV
 SG_ AVS_RemoteMonitorigFeedback : 48|3@1+ (1,0) [0|7] ""  Gateway
 SG_ AVS_RemoteSharpnessFeedback : 51|3@1+ (1,0) [0|7] ""  Gateway
 SG_ RemoteMonitoringSharpnessSt_AVS : 54|1@1+ (1,0) [0|1] ""  Gateway
 SG_ RemoteMonitoringSt_AVS : 55|1@1+ (1,0) [0|1] ""  Gateway
 SG_ RemoteMonitoringModeSt_AVS : 56|1@1+ (1,0) [0|1] ""  Gateway
 SG_ AVS_RemoteViewModeFeedback : 59|5@1+ (1,0) [0|31] ""  Gateway

BO_ 599 AVP_1: 8 AVP
 SG_ Checksum_AVP_1 : 0|8@1+ (1,0) [0|255] ""  Gateway
 SG_ AVP_AutoDriveDataRecordAvailable : 8|1@1+ (1,0) [0|1] ""  Gateway
 SG_ AVP_AutoDriveDataRecordStatus : 9|2@1+ (1,0) [0|3] ""  Gateway
 SG_ LiveCounter_AVP_1 : 60|4@1+ (1,0) [0|15] "Pulse"  Gateway

BO_ 604 PDC_1: 8 PDC
 SG_ SysSt_PDC : 0|1@1+ (1,0) [0|1] ""  Gateway,ADV,AVP,AVM
 SG_ ErrorSt_PDC : 1|1@1+ (1,0) [0|1] ""  Gateway,ADV,AVP,AVM
 SG_ RadarSysSt_Front : 2|1@1+ (1,0) [0|1] ""  Gateway,ADV,AVP,AVM
 SG_ RadarSysSt_Rear : 3|1@1+ (1,0) [0|1] ""  Gateway,ADV,AVP,AVM
 SG_ BuzeerCmd_PDC : 5|3@1+ (1,0) [0|7] ""  Gateway,ADV
 SG_ BuzzerAlarmPosition : 8|3@1+ (1,0) [0|7] ""  Gateway
 SG_ RadarSysSt_FrontSide : 11|1@1+ (1,0) [0|1] ""  Gateway,ADV,AVP,AVM
 SG_ RadarSysSt_RearSide : 12|1@1+ (1,0) [0|1] ""  Gateway,ADV,AVP,AVM
 SG_ BuzzerSwitchSt : 13|1@1+ (1,0) [0|1] ""  Gateway
 SG_ ObjectRange_RR : 16|3@1+ (1,0) [0|7] ""  Gateway,ADV,AVP,AVM
 SG_ SensorErrorSt_RR : 19|1@1+ (1,0) [0|1] ""  Gateway,ADV,AVP,AVM
 SG_ ObjectRange_RMR : 20|3@1+ (1,0) [0|7] ""  Gateway,ADV,AVP,AVM
 SG_ SensorErrorSt_RMR : 23|1@1+ (1,0) [0|1] ""  Gateway,ADV,AVP,AVM
 SG_ ObjectRange_RML : 24|3@1+ (1,0) [0|7] ""  Gateway,ADV,AVP,AVM
 SG_ SensorErrorSt_RML : 27|1@1+ (1,0) [0|1] ""  Gateway,ADV,AVP,AVM
 SG_ ObjectRange_RL : 28|3@1+ (1,0) [0|7] ""  Gateway,ADV,AVP,AVM
 SG_ SensorErrorSt_RL : 31|1@1+ (1,0) [0|1] ""  Gateway,ADV,AVP,AVM
 SG_ ObjectRange_FR : 32|3@1+ (1,0) [0|7] ""  Gateway,ADV,AVP,AVM
 SG_ SensorErrorSt_FR : 35|1@1+ (1,0) [0|1] ""  Gateway,ADV,AVP,AVM
 SG_ ObjectRange_FMR : 36|3@1+ (1,0) [0|7] ""  Gateway,ADV,AVP,AVM
 SG_ SensorErrorSt_FMR : 39|1@1+ (1,0) [0|1] ""  Gateway,ADV,AVP,AVM
 SG_ ObjectRange_FML : 40|3@1+ (1,0) [0|7] ""  Gateway,ADV,AVP,AVM
 SG_ SensorErrorSt_FML : 43|1@1+ (1,0) [0|1] ""  Gateway,ADV,AVP,AVM
 SG_ ObjectRange_FL : 44|3@1+ (1,0) [0|7] ""  Gateway,ADV,AVP,AVM
 SG_ SensorErrorSt_FL : 47|1@1+ (1,0) [0|1] ""  Gateway,ADV,AVP,AVM
 SG_ PDCAutoOnFunctionInd : 53|1@1+ (1,0) [0|1] ""  Gateway
 SG_ SwitchScreenRequest_PDC : 54|2@1+ (1,0) [0|3] ""  Gateway
 SG_ PDC_SpeechControlFeedback : 56|3@1+ (1,0) [0|7] ""  Gateway,ADV
 SG_ PDC_SearchingSlotPosition : 59|2@1+ (1,0) [0|3] ""  AVP,AVM
 SG_ PDC_FunctionTip : 61|3@1+ (1,0) [0|7] ""  ADV,AVP,AVM

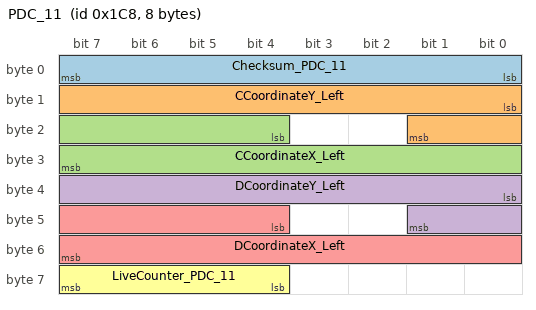
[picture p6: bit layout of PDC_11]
BO_ 456 PDC_11: 8 PDC
 SG_ Checksum_PDC_11 : 0|8@1+ (1,0) [0|255] ""  ADV,AVP,AVM
 SG_ CCoordinateY_Left : 8|10@1+ (1,0) [0|1023] "cm"  ADV,AVP,AVM
 SG_ CCoordinateX_Left : 20|12@1+ (1,0) [0|4095] "cm"  ADV,AVP,AVM
 SG_ DCoordinateY_Left : 32|10@1+ (1,0) [0|1023] "cm"  ADV,AVP,AVM
 SG_ DCoordinateX_Left : 44|12@1+ (1,0) [0|4095] "cm"  ADV,AVP,AVM
 SG_ LiveCounter_PDC_11 : 60|4@1+ (1,0) [0|15] "Pulse"  ADV,AVP,AVM

BO_TX_BU_ 592 : ADV,CDS1;
BO_TX_BU_ 593 : ADV,CDS1;
BO_TX_BU_ 595 : ADV,CDS1;
BO_TX_BU_ 967 : ADV,CDS1;
BO_TX_BU_ 600 : AVM,AVP;
CM_ SG_ 282 Checksum_HAD_3 "The checksum is used to check whether the data from the CPU buffer are shifted without transmission errors to the CAN communication controller buffer and vice versa.";
CM_ SG_ 282 HAD_AutoDrivingReq_L3 "This signal indicates the acceleration or deceleration command is from L1L2 function or L3 function.";
CM_ SG_ 282 HAD_SpeedChangeRequest_L3 "4";
CM_ SG_ 282 HAD_MaxAccGrad_L3 "The maximum acceleration gradient allowed by HAD";
CM_ SG_ 282 HAD_MinAccGrad_L3 "The minimum acceleration gradient allowed by HAD";
CM_ SG_ 282 HAD_MaxComfBand_L3 "Upper limit for acceleration comfort zone ";
CM_ SG_ 282 HAD_MinComfBand_L3 "Low limit for acceleartion comfort zone";
CM_ SG_ 282 HAD_UseMaxComfBand_L3 "HAD request to use the upper limit value of acceleration comfort zone.
";
CM_ SG_ 282 HAD_HDMapUsingst_L3 "This signal indicates whether HD map is used by HAD for  L3 function.";
CM_ SG_ 282 LiveCounter_HAD_3 "The Livecounter is used to check the signal consistency of the messages . If the signals are consecutive, the LiveCounter should also be sequential in the way 0, 1, 2 °≠15, 0, 1 °≠";
CM_ SG_ 283 Checksum_HAD_4 "The checksum is used to check whether the data from the CPU buffer are shifted without transmission errors to the CAN communication controller buffer and vice versa.";
CM_ SG_ 283 HAD_BrakeModeReq_L3 "This signal indicate HAD request to brake cosily or urgently.
This signal is only used for L3 function";
CM_ SG_ 283 HAD_DrivedownReq_L3 "HAD request to quit autodriving funciton.
This signal is only used for L3 function.";
CM_ SG_ 283 HAD_SecureRequest_L3 "HAD request to stop the car safely.
This signal is only used for L3 function";
CM_ SG_ 283 HAD_ErrorSt_AutoDriving_L3 "This signal indicates the L3 autodriving function error status.
This signal is only used for L3 function";
CM_ SG_ 283 LiveCounter_HAD_4 "The Livecounter is used to check the signal consistency of the messages . If the signals are consecutive, the LiveCounter should also be sequential in the way 0, 1, 2 °≠15, 0, 1 °≠";
CM_ SG_ 278 Checksum_HAD_6 "The checksum is used to check whether the data from the CPU buffer are shifted without transmission errors to the CAN communication controller buffer and vice versa.";
CM_ SG_ 278 HAD_TorqueRequest "This signal is the request steering wheel torque by LKA or LCA.in case of No Request: TorqueRequest_LKALCA = 0x3FE";
CM_ SG_ 278 HAD_TorqueRequestSign "This signal Indicates sign of LKA or LCA steering torque";
CM_ SG_ 278 HAD_TorqueReqSt "This signal indicates the status of the torque request from LKA or LCA 
";
CM_ SG_ 278 HAD_Intervention_LKA "This signal Indicates the LKA is Intervention or not";
CM_ SG_ 278 HAD_WorkingSt_LKA "This signal indicates the LKA working status.,Signal Initial=last value";
CM_ SG_ 278 HAD_ErrorSt_LKA "This signal indicates the LKA error status.";
CM_ SG_ 278 HAD_TakeOverTip_LCA "This Driver should take over the vehicle.";
CM_ SG_ 278 HAD_HandsOffTip_LCA "Hands off, put hands on the steering wheel to active LCA function";
CM_ SG_ 278 HAD_WorkingSt_LCA "This signal indicates the LCA working status.,Signal Initial=last value";
CM_ SG_ 278 HAD_ErrorSt_LCA "This signal indicates the LCA error status.";
CM_ SG_ 278 HAD_AutoDrivingModeReq "This signal is the Source of Torque request to EPS";
CM_ SG_ 278 HAD_ErrorSt_SACC "HAD system capbility for SACC/LCA/HWA/TJA";
CM_ SG_ 278 HAD_ErrorSt_HWP "HAD system capbility for HWP";
CM_ SG_ 278 HAD_ErrorSt_TJP "HAD system capbility forTJP";
CM_ SG_ 278 HAD_LDWSteeringVibrationReq "This signal indicates the request the steering vibration function. ";
CM_ SG_ 278 HAD_WorkingSt_DCLC "This signal indicates the DCLC working status.,Signal Initial=last value";
CM_ SG_ 278 HAD_WorkingSt_HWP "This signal indicates the HWP working status.,Signal Initial=last value";
CM_ SG_ 278 HAD_WorkingSt_TJP "This signal indicates the TJP working status.,Signal Initial=last value";
CM_ SG_ 278 HAD_ErrorSt_HAD "This signal indicates HAD is error or not.If the value of this signal is °∞Error°Æ,EPS shoud ignore this message and respond the message from HAD.";
CM_ SG_ 278 LiveCounter_HAD_6 "The Livecounter is used to check the signal consistency of the messages . If the signals are consecutive, the LiveCounter should also be sequential in the way 0, 1, 2 °≠15, 0, 1 °≠";
CM_ SG_ 272 Checksum_IFC_1 "The checksum is used to check whether the data from the CPU buffer are shifted without transmission errors to the CAN communication controller buffer and vice versa.";
CM_ SG_ 272 IFC_WorkingSt_AEB_L12 "This signal indicates the AEB working status.";
CM_ SG_ 272 IFC_ErrorSt_AEB_L12 "This signal indicates the AEB error status.";
CM_ SG_ 272 IFC_ErrorSt_ACC_L12 "This signal indicates the ACC error status.";
CM_ SG_ 272 IFC_WorkingSt_ACC_L12 "This signal indicates the ACC working status.";
CM_ SG_ 272 IFC_ABPReq_L12 "This signal indicates the request for prefill function.";
CM_ SG_ 272 IFC_AWBReq_L12 "This signal in the request of the brake jerk warning to ESC.";
CM_ SG_ 272 IFC_AWBlevel_L12 "This signal indicates the different level request of the brake jerk warning.";
CM_ SG_ 272 CruiseModeFunctionInd "This signal indicates setting result of the configuration of cruise mode function.,Signal Initial=last value";
CM_ SG_ 272 IFC_BrakeModeReq_L12 "This signal indicate IFC request to brake cosily or urgently.
This signal is only used for L12 function";
CM_ SG_ 272 IFC_DrivedownReq_L12 "IFC request to quit out the auto pilot function.
This signal is only used for L12 function";
CM_ SG_ 272 IFC_SecureRequest_L12 "IFC request to stop the car safely.
This signal is only used for L12 function";
CM_ SG_ 272 IFC_AEBSensitivity_L12 "This signal indicates the sensitivity of AEB function";
CM_ SG_ 272 IFC_AutoDrivingReq "Auto driving function active request from IFC to HCU.";
CM_ SG_ 272 LiveCounter_IFC_1 "The Livecounter is used to check the signal consistency of the messages . If the signals are consecutive, the LiveCounter should also be sequential in the way 0, 1, 2 °≠15, 0, 1 °≠";
CM_ SG_ 275 Checksum_IFC_6 "The checksum is used to check whether the data from the CPU buffer are shifted without transmission errors to the CAN communication controller buffer and vice versa.";
CM_ SG_ 275 IFC_AutoDrivingReq_L12 "This signal indicates the acceleration or deceleration command is from L1L2 function or L3 function.";
CM_ SG_ 275 IFC_SpeedChangeRequest_L12 "This signal is the value of acceleration request.";
CM_ SG_ 275 IFC_MaxAccGrad_L12 "The maximum acceleration gradient allowed by IFC";
CM_ SG_ 275 IFC_MinAccGrad_L12 "The minimum acceleration gradient allowed by IFC";
CM_ SG_ 275 IFC_MaxComfBand_L12 "Upper limit for acceleration comfort zone ";
CM_ SG_ 275 IFC_MinComfBand_L12 "Low limit for acceleartion comfort zone";
CM_ SG_ 275 IFC_UseMaxComfBand_L12 "IFC request to use the upper limit value of acceleration comfort zone.
";
CM_ SG_ 275 LiveCounter_IFC_6 "The Livecounter is used to check the signal consistency of the messages . If the signals are consecutive, the LiveCounter should also be sequential in the way 0, 1, 2 °≠15, 0, 1 °≠";
CM_ SG_ 294 Checksum_FOU_1 "The checksum is used to check whether the data from the CPU buffer are shifted without transmission errors to the CAN communication controller buffer and vice versa.";
CM_ SG_ 294 FOU_AutoDrivingReq_L3 "This signal indicates the acceleration or deceleration command is from L1L2 function or L3 function.";
CM_ SG_ 294 FOU_SpeedChangeRequest_L3 "This signal is the value of acceleration request or deceleration request(L3).";
CM_ SG_ 294 FOU_MaxAccGrad_L3 "The maximum acceleration gradient allowed by FOU";
CM_ SG_ 294 FOU_MinAccGrad_L3 "The minimum acceleration gradient allowed by FOU";
CM_ SG_ 294 FOU_MaxComfBand_L3 "Upper limit for acceleration comfort zone ";
CM_ SG_ 294 FOU_MinComfBand_L3 "Low limit for acceleartion comfort zone";
CM_ SG_ 294 FOU_UseMaxComfBand_L3 "FOU request to use the upper limit value of acceleration comfort zone.
";
CM_ SG_ 294 LiveCounter_FOU_1 "The Livecounter is used to check the signal consistency of the messages . If the signals are consecutive, the LiveCounter should also be sequential in the way 0, 1, 2 °≠15, 0, 1 °≠";
CM_ SG_ 295 Checksum_FOU_2 "The checksum is used to check whether the data from the CPU buffer are shifted without transmission errors to the CAN communication controller buffer and vice versa.";
CM_ SG_ 295 FOU_BrakeModeReq_L3 "This signal indicate FOU request to brake cosily or urgently.
This signal is only used for L3 function";
CM_ SG_ 295 FOU_DrivedownReq_L3 "FOU request to quit autodriving funciton.
This signal is only used for L3 function.";
CM_ SG_ 295 FOU_SecureRequest_L3 "FOU request to stop the car safely.
This signal is only used for L3 function";
CM_ SG_ 295 FOU_ErrorSt_AutoDriving_L3 "This signal indicates the L3 autodriving function error status.
This signal is only used for L3 function";
CM_ SG_ 295 FOU_WorkingSt_AutoDriving_L3 "This signal indicates the L3 autodriving function working status.
This signal is only used for L3 function";
CM_ SG_ 295 LiveCounter_FOU_2 "The Livecounter is used to check the signal consistency of the messages . If the signals are consecutive, the LiveCounter should also be sequential in the way 0, 1, 2 °≠15, 0, 1 °≠";
CM_ SG_ 274 Checksum_IFC_4 "The checksum is used to check whether the data from the CPU buffer are shifted without transmission errors to the CAN communication controller buffer and vice versa.";
CM_ SG_ 274 IFC_TorqueRequest "This signal is the request steering wheel torque by LKA or LCA.in case of No Request: TorqueRequest_LKALCA = 0x3FE";
CM_ SG_ 274 IFC_TorqueRequestSign "This signal Indicates sign of LKA or LCA steering torque";
CM_ SG_ 274 IFC_TorqueReqSt "This signal indicates the status of the torque request from LKA or LCA 
";
CM_ SG_ 274 IFC_Intervention_LKA "This signal Indicates the LKA is Intervention or not";
CM_ SG_ 274 IFC_WorkingSt_LKA "This signal indicates the LKA working status.,Signal Initial=last value";
CM_ SG_ 274 IFC_ErrorSt_LKA "This signal indicates the LKA error status.";
CM_ SG_ 274 IFC_TakeOverTip_LCA "This Driver should take over the vehicle.";
CM_ SG_ 274 IFC_HandsOffTip_LCA "Hands off, put hands on the steering wheel to active LCA function";
CM_ SG_ 274 IFC_WorkingSt_LCA "This signal indicates the LCA working status.,Signal Initial=last value";
CM_ SG_ 274 IFC_ErrorSt_LCA "This signal indicates the LCA error status.";
CM_ SG_ 274 IFC_AutoDrivingModeReq "This signal is the Source of Torque request to EPS";
CM_ SG_ 274 IFC_ErrorSt_SACC "IFC system capbility for SACC/LCA/HWA/TJA";
CM_ SG_ 274 FOU_ErrorSt_HWP "FOU system capbility for HWP";
CM_ SG_ 274 FOU_ErrorSt_TJP "FOU system capbility forTJP";
CM_ SG_ 274 LDWSteeringVibrationReq "This signal indicates the request the steering vibration function. ";
CM_ SG_ 274 IFC_WorkingSt_SACC "This signal indicates theSACCworking status.,Signal Initial=last value";
CM_ SG_ 274 FOU_WorkingSt_HWP "This signal indicates the HWP working status.,Signal Initial=last value";
CM_ SG_ 274 FOU_WorkingSt_TJP "This signal indicates the TJP working status.,Signal Initial=last value";
CM_ SG_ 274 IFC_ErrorSt_FOU "This signal indicates FOU is error or not.If the value of this signal is °∞Error°Æ,EPS shoud ignore this message and respond the message from FOU.";
CM_ SG_ 274 LiveCounter_IFC_4 "The Livecounter is used to check the signal consistency of the messages . If the signals are consecutive, the LiveCounter should also be sequential in the way 0, 1, 2 °≠15, 0, 1 °≠";
CM_ SG_ 279 Checksum_IFC_5 "The checksum is used to check whether the data from the CPU buffer are shifted without transmission errors to the CAN communication controller buffer and vice versa.";
CM_ SG_ 279 IFC_SteeringWheelAngleRequest "Steering Wheel Angle Request";
CM_ SG_ 279 IFC_SteeringWheelAngleSignReques "Steering Wheel Angle Sign Request";
CM_ SG_ 279 IFC_SteeringWheelAngleControlReq "The status of steering wheel angle request.";
CM_ SG_ 607 HAD_CruiseSpeedSetting_ACC "The signal indicates the target speed desired by the driver in ACC cruise mode.";
CM_ SG_ 607 HAD_TimeGapSetting "The cruise time gap  is setted according to the control requests from the driver.";
CM_ SG_ 607 HAD_ObjectDetection "This signal is an ahead target object detected by ACC, to inform the driver.";
CM_ SG_ 607 HAD_SysTextinfo "The systerm text information for driver which is displayed in dashboard.";
CM_ SG_ 607 HAD_LDWModeInd "This signal is used to indicates the configure result of LDW function.,Signal Initial=last value";
CM_ SG_ 607 HAD_TakeOverReq "This signal indicates the request for driver take over if the limits of the ACC /SACC control reaches, ";
CM_ SG_ 607 HAD_AutoLightModeReq "This signal indicates HAD/HAD request BCM to active the automatic light mode.";
CM_ SG_ 607 HAD_HazardWarningLampRequest "Hazard Warning Lamp request from LCA";
CM_ SG_ 607 HAD_WorkingSt_LDW "This signal indicates the LDW working status.";
CM_ SG_ 607 HAD_WarningCmd_LDW "This signal is warning command for the warning side of lane.";
CM_ SG_ 607 HAD_LDWLaneDetectSt "This signal indicate system lane mark detection status";
CM_ SG_ 607 HAD_SensitivityInd_LDW "This signal indicates current sensitivity of LDW.,Signal Initial=last value";
CM_ SG_ 607 HAD_ErrorSt_LDW "This signal indicates the LDW error status.";
CM_ SG_ 607 HAD_WorkingSt_FCW "This signal indicates the FCW system working status.";
CM_ SG_ 607 HAD_WarningCmd_FCW "This signal is warning command for FCW warning.";
CM_ SG_ 607 HAD_ErrorSt_FCW "This signal indicates the FCW error status.";
CM_ SG_ 607 HAD_SensitivityInd_FCW "This signal indicates current sensitivity of FCW.,Signal Initial=last value";
CM_ SG_ 607 HAD_FCWModeInd "This signal is used to indicates the configure result of FCW function.";
CM_ SG_ 607 HAD_WiperAutoLeverReq "This signal indicates that HAD/HAD request BCM1 to turn the wiper to auto lever mode.";
CM_ SG_ 607 HAD_SACCNotSatisfiedCondition "This signal indicates the conditions that cant active SACC/ACC function";
CM_ SG_ 607 HAD_LDW_SpeechControlFeedback "This signal indicates the speech control feedback of LDW function setting";
CM_ SG_ 607 HAD_VASFunctionInd "This signal indicates setting result of the configuration of VAS(Vehicle Ahead Start) function.";
CM_ SG_ 607 HAD_IFCSystemError "This signal indicates the IFC error status.";
CM_ SG_ 607 HAD_IFCCalibrationStatus "This signal indicates the IFC calibration status.";
CM_ SG_ 607 HAD_WarningCmd_VAS "This signal is warning command for the VAS(Vehicle Ahead Start) function.";
CM_ SG_ 607 HAD_LeftTurningLampRequest "Left Turning Lamp request";
CM_ SG_ 607 HAD_RightTurningLampRequest "Right Turning Lamp request";
CM_ SG_ 607 HAD_ValetModeStatus "Indicates the valet mode status,Signal Initial=last value";
CM_ SG_ 608 CruiseSpeedSetting_ACC "The signal indicates the target speed desired by the driver in ACC cruise mode.";
CM_ SG_ 608 TimeGapSetting "The cruise time gap  is setted according to the control requests from the driver.";
CM_ SG_ 608 ObjectDetection "This signal is an ahead target object detected by ACC, to inform the driver.";
CM_ SG_ 608 SysTextinfo "The systerm text information for driver which is displayed in dashboard.";
CM_ SG_ 608 LDWModeInd "This signal is used to indicates the configure result of LDW function.,Signal Initial=last value";
CM_ SG_ 608 TakeOverReq "This signal indicates the request for driver take over if the limits of the ACC /SACC control reaches, ";
CM_ SG_ 608 AutoLightModeReq "This signal indicates HAD/IFC request BCM to active the automatic light mode.";
CM_ SG_ 608 HazardWarningLampRequest "Hazard Warning Lamp request from LCA";
CM_ SG_ 608 WorkingSt_LDW "This signal indicates the LDW working status.";
CM_ SG_ 608 WarningCmd_LDW "This signal is warning command for the warning side of lane.";
CM_ SG_ 608 LDWLaneDetectSt "This signal indicate system lane mark detection status";
CM_ SG_ 608 SensitivityInd_LDW "This signal indicates current sensitivity of LDW.,Signal Initial=last value";
CM_ SG_ 608 ErrorSt_LDW "This signal indicates the LDW error status.";
CM_ SG_ 608 WorkingSt_FCW "This signal indicates the FCW system working status.";
CM_ SG_ 608 WarningCmd_FCW "This signal is warning command for FCW warning.";
CM_ SG_ 608 ErrorSt_FCW "This signal indicates the FCW error status.";
CM_ SG_ 608 SensitivityInd_FCW "This signal indicates current sensitivity of FCW.,Signal Initial=last value";
CM_ SG_ 608 FCWModeInd "This signal is used to indicates the configure result of FCW function.";
CM_ SG_ 608 WiperAutoLeverReq "This signal indicates that HAD/IFC request BCM1 to turn the wiper to auto lever mode.";
CM_ SG_ 608 SACCNotSatisfiedCondition "This signal indicates the conditions that cant active SACC/ACC function";
CM_ SG_ 608 LDW_SpeechControlFeedback "This signal indicates the speech control feedback of LDW function setting";
CM_ SG_ 608 VASFunctionInd "This signal indicates setting result of the configuration of VAS(Vehicle Ahead Start) function.";
CM_ SG_ 608 IFCSystemError "This signal indicates the IFC error status.";
CM_ SG_ 608 IFCCalibrationStatus "This signal indicates the IFC calibration status.";
CM_ SG_ 608 WarningCmd_VAS "This signal is warning command for the VAS(Vehicle Ahead Start) function.";
CM_ SG_ 608 IFC_LeftTurningLampRequest "Left Turning Lamp request";
CM_ SG_ 608 IFC_RightTurningLampRequest "Right Turning Lamp request";
CM_ SG_ 609 HAD_LimitedVehicleSpeed_TSR "This signal indicates the limited vehicle speed by TSR.If TSR_Warning is inactive,this signal should be set to 0xFE.";
CM_ SG_ 609 HAD_WorkingSt_TSR "This signal indicates the TSR  working status.,Signal Initial=last value";
CM_ SG_ 609 HAD_WarningCmd_TSR "This signal is warning command for the TSR warning.";
CM_ SG_ 609 HAD_ErrorSt_TSR "This signal indicates the TSR error status.";
CM_ SG_ 609 HAD_VAS_SpeechControlFeedback "This signal indicates the speech control feedback of VAS function setting";
CM_ SG_ 609 HAD_TSR_SpeechControlFeedback "This signal indicates the speech control feedback of TSR function setting";
CM_ SG_ 610 LimitedVehicleSpeed_TSR "This signal indicates the limited vehicle speed by TSR.If TSR_Warning is inactive,this signal should be set to 0xFE.";
CM_ SG_ 610 WorkingSt_TSR "This signal indicates the TSR  working status.,Signal Initial=last value";
CM_ SG_ 610 WarningCmd_TSR "This signal is warning command for the TSR warning.";
CM_ SG_ 610 ErrorSt_TSR "This signal indicates the TSR error status.";
CM_ SG_ 610 WorkingSt_DSM "This signal indicates the DSM working status.,Signal Initial=last value";
CM_ SG_ 610 WarningCmd_DSM "This signal is warning command for the DSM function.";
CM_ SG_ 610 ErrorSt_DSM "This signal indicates the DSM  error status.";
CM_ SG_ 610 DSMFunctionInd "This signal indicates the DSM setting results.";
CM_ SG_ 610 VAS_SpeechControlFeedback "This signal indicates the speech control feedback of VAS function setting";
CM_ SG_ 610 TSR_SpeechControlFeedback "This signal indicates the speech control feedback of TSR function setting";
CM_ SG_ 610 DSM_SpeechControlFeedback "This signal indicates the speech control feedback of DSM function setting";
CM_ SG_ 611 Checksum_IFC_11 "The checksum is used to check whether the data from the CPU buffer are shifted without transmission errors to the CAN communication controller buffer and vice versa.";
CM_ SG_ 611 HAD_AutoDrivingSt "This signal indicates the auto driving funftion status,Signal Initial=last value";
CM_ SG_ 592 ADV_ParkType "APA park type,Signal Initial=last value";
CM_ SG_ 592 ADV_ParkInSlotSearchMode "Park-in slot search mode,Signal Initial=last value";
CM_ SG_ 592 ADV_ParkStatus "ADV Park Status";
CM_ SG_ 592 ADV_SystemError "Indicates ADV system is error or not";
CM_ SG_ 592 ADV_ParkInAvaialble "Indicates Park in system is available or not";
CM_ SG_ 592 ADV_ParkOutAvaialble "Indicates Park out system is available or not";
CM_ SG_ 592 ADV_ParkInReady "Indicates the system is ready for Park in";
CM_ SG_ 592 ADV_ParkOutReady "Indicates the system is ready for Park out";
CM_ SG_ 592 ADV_ParkOutDirection "Park out direction";
CM_ SG_ 592 ADV_VehicleModeRequest "Vehicle Mode request";
CM_ SG_ 592 ADV_BrakeLightCtrlCmd "The signal indicates the brake light control command.";
CM_ SG_ 592 ADV_HazardWarningLampRequest "Hazard Warning Lamp request for flashing one time";
CM_ SG_ 592 ADV_DoorRequest "Request PEPS to lock the door";
CM_ SG_ 592 ADV_LeftTurningLampRequest "Left Turning Lamp request";
CM_ SG_ 592 ADV_RightTurningLampRequest "Right Turning Lamp request";
CM_ SG_ 592 ADV_EngineAndEVStopRequest "Request PEPS to stop Engine or EV power";
CM_ SG_ 592 ADV_FunctionAbnormalTip "ADV Function Abnormal Tip";
CM_ SG_ 592 ADV_ParkInEnabled "Indicates the system is enable for Park in,used to highlight the °∞Start Park In°± button on IVI.";
CM_ SG_ 592 ADV_ParkOutEnabled "Indicates the system is enable for Park out,used to highlight the °∞Start Park Out°± button on IVI.";
CM_ SG_ 592 ADV_TimeoutCounter "This signal Indicates to display the seconds to exit parkin/parkout system";
CM_ SG_ 592 ADV_ParkingStep "This signal indicates the parking step is parking in or parking out.";
CM_ SG_ 592 ADV_RearViewMirrorFoldRequest "Request BCM to fold or unfold the rear view mirror.";
CM_ SG_ 592 ADV_ParkingAEBFunctionInd "Indicates the parking AEB function status,Signal Initial=last value";
CM_ SG_ 592 ADV_BacktrackFunctionInd "Indicates the backtrack status,Signal Initial=last value";
CM_ SG_ 592 LiveCounter_ADV_1 "The Livecounter is used to check the signal consistency of the messages . If the signals are consecutive, the LiveCounter should also be sequential in the way 0, 1, 2 °≠15, 0, 1 °≠";
CM_ SG_ 593 ADV_BacktrackAbnormalTip "Indicates the backtrack function abnormal tip";
CM_ SG_ 593 ADV_LeftSlotSearchType "This signal set the slot search type of left radar.";
CM_ SG_ 593 ADV_RightSlotSearchType "This signal set the slot search type of right radar.";
CM_ SG_ 593 ADV_PDCSchedule "This signal indicates the ADV request radar scan schedule of PDC.";
CM_ SG_ 593 ADV_APAFuncntion_SpeechControlFe "This signal indicates the feedback to APA function speech control.";
CM_ SG_ 593 ADV_ParkInMode_SpeechControlFeed "This signal indicates the feedback to park in mode speech control.";
CM_ SG_ 593 ADV_ParkInType_SpeechControlFeed "This signal indicates the feedback to park in type speech control.";
CM_ SG_ 593 ADV_ParkOutFunc_SpeechControlFee "This signal indicates the feedback to park out function speech control.";
CM_ SG_ 593 ADV_ParkOutType_SpeechControlFee "This signal indicates the feedback to park in type speech control.";
CM_ SG_ 593 ADV_SearchTimeoutCounter "This signal Indicates to display the seconds to exit search process.";
CM_ SG_ 593 ADV_PauseTimeoutCounter "This signal Indicates to display the seconds to exit pause state.";
CM_ SG_ 593 ADV_PauseButtonDisplay "This signal indicates the text to display on the start/pause button.";
CM_ SG_ 593 LiveCounter_ADV_4 "The Livecounter is used to check the signal consistency of the messages . If the signals are consecutive, the LiveCounter should also be sequential in the way 0, 1, 2 °≠15, 0, 1 °≠";
CM_ SG_ 613 HAD_SystemError_AVP "Indicates AVP system is error or not";
CM_ SG_ 613 HAD_ParkingLotAvalableTip_AVP "Remider driver there is some useble parking lots for ";
CM_ SG_ 613 HAD_AIUnavailableTip "If the car is not in the L3 autodriving or AVP supported area,HAD should remind driver.";
CM_ SG_ 613 HAD_ValetModeTip_AVP "If the car is now in valet mode,HAD should remind driver AVP is not available.";
CM_ SG_ 613 HAD_ChangeLaneManualsuccess_Tip "Whether change lane function is successful.";
CM_ SG_ 613 HAD_SetdestinationFuncSt "The waorking status of remindering driver setting destination function.,Signal Initial=last value";
CM_ SG_ 613 HAD_SetdestinationTip "reminder driver setting destination";
CM_ SG_ 613 HAD_WorkingSt_HWP_Display "The HWP function working status";
CM_ SG_ 613 HAD_TakeoverReq_L3 "request driver to take over the car";
CM_ SG_ 613 HAD_ChangeLaneManualFuncSt "The function status of driver change the lane manually by operate the turning switch,Signal Initial=last value";
CM_ SG_ 613 HAD_WorkingSt_TJP_Display "The TJP function working status";
CM_ SG_ 613 HAD_LateralTakeOverReq_L3 "On some condition,HAD will request driver take over the steering wheel to control the lateral function.";
CM_ SG_ 613 HAD_AutoDrivingStyle " the autodriving style setted,Signal Initial=last value";
CM_ SG_ 613 HAD_ChangeLaneAutoFuncSt "The function status of HAD change the lane automatically,Signal Initial=last value";
CM_ SG_ 613 HAD_TOR_Tips "The tips of take over waring ";
CM_ SG_ 613 HAD_AutoDrivingNotSatisfiedCondi "This signal indicates the conditions that cant active HWP/TJP function";
CM_ SG_ 613 HAD_DistractionWarning "This signal indicates the distraction warning";
CM_ SG_ 613 HAD_AttentionSt "Driver attention area";
CM_ SG_ 613 HAD_TakeOverWarning_L3 "remind driver to take over the car by lamp,buzzer or vibration°≠";
CM_ SG_ 613 HAD_TakeOverSuccessTip_L3 "Indicate the way driver quited the auto driving function by.";
CM_ SG_ 613 HAD_ChangeLaneManual_Feedback "the feedback of the request of driver for changing the lane";
CM_ SG_ 613 HAD_ErrorSt_HWPTJP "The L3 auto driving system has fault or not";
CM_ SG_ 613 HAD_Countdown_Takeover "Remind driver the remining time of taking over the car";
CM_ SG_ 613 HAD_Destinationtip_St "Destination remind functional status of HWP/TJP.";
CM_ SG_ 613 HAD_Countdown_SafeStop "Remind driver the remining time of stopping the car safely";
CM_ SG_ 613 HAD_SACCActiveForbidden "The signal indicates that HAD forbidden user active ACC/SACC by SC on some condition such as auto pilot.";
CM_ SG_ 613 LiveCounter_HAD_5 "The Livecounter is used to check the signal consistency of the messages . If the signals are consecutive, the LiveCounter should also be sequential in the way 0, 1, 2 °≠15, 0, 1 °≠";
CM_ SG_ 595 ADV_CIDLocationReq "The signal indicates that ADV request to get the CID location.,Signal Initial=last value";
CM_ SG_ 595 ADV_PositionLightReq "This signal indicates the ADV request of position light.";
CM_ SG_ 595 ADV_FogLightReq_Front "This signal indicates the ADV request of front fog light.";
CM_ SG_ 595 ADV_FogLightReq_Rear "This signal indicates the ADV request of rear fog light.";
CM_ SG_ 595 ADV_AVPHazardWarningFunctionInd "The signal indicates the AVP hazard warning function status.,Signal Initial=last value";
CM_ SG_ 595 ADV_HPAHazardWarningFunctionInd "The signal indicates the HPA hazard warning function status.,Signal Initial=last value";
CM_ SG_ 595 ADV_AVPTypeIndication "The AVP type indication.,Signal Initial=last value";
CM_ SG_ 595 ADV_AVPSearchingTypeInd "The AVP searching type indication.,Signal Initial=last value";
CM_ SG_ 595 ADV_HPATypeIndication "The HPA type indication.,Signal Initial=last value";
CM_ SG_ 595 ADV_HPASearchingTypeInd "The HPA searching type indication.,Signal Initial=last value";
CM_ SG_ 595 ADV_AVPParkingLotPushFunctionInd "This signal indicates the AVP parking lot push funtion status.,Signal Initial=last value";
CM_ SG_ 595 ADV_HPAParkingLotPushFunctionInd "This signal indicates the HPA parking lot push funtion status.,Signal Initial=last value";
CM_ SG_ 595 ADV_AVPNaviAvaialble "Indicates AVP system is available or not fot navigation.";
CM_ SG_ 595 ADV_AVPParkInAvaialble "Indicates AVP Park in system is available or not";
CM_ SG_ 595 ADV_AVPParkOutAvaialble "Indicates AVP Park out system is available or not";
CM_ SG_ 595 ADV_AVPParkInReady "Indicates the system is ready for AVP Park in";
CM_ SG_ 595 ADV_AVPParkOutReady "Indicates the system is ready for AVP Park out";
CM_ SG_ 595 ADV_HPANaviAvaialble "Indicates HPA system is available or not fot navigation.";
CM_ SG_ 595 ADV_HPAParkInAvaialble "Indicates HPA Park in system is available or not";
CM_ SG_ 595 ADV_HPAParkOutAvaialble "Indicates HPA Park out system is available or not";
CM_ SG_ 595 ADV_HPAParkInReady "Indicates the system is ready for HPA Park in";
CM_ SG_ 595 ADV_HPAParkOutReady "Indicates the system is ready for HPA Park out";
CM_ SG_ 595 ADV_AVPSuspendStatus "Indicates the susend status of AVP";
CM_ SG_ 595 ADV_HPAFucntion_SpeechControlFee "This signal indicates the feedback to HPA function speech control.";
CM_ SG_ 595 ADV_SunRoofRequest "This signal indicates the ADV request of open or close the sun roof.";
CM_ SG_ 595 ADV_AllWindowsCloseReq "This signal indicates the ADV request of close all the windows.";
CM_ SG_ 595 ADV_OvertakingLightReq "This signal indicates the ADV request of overtaking light.";
CM_ SG_ 595 ADV_LowBeamReq "This signal indicates the ADV request of low beam.";
CM_ SG_ 595 ADV_HighBeamReq "This signal indicates the ADV request of high beam.";
CM_ SG_ 595 ADV_AntitheftAlarmReq "This signal indicates the ADV request of antitheft alarm.";
CM_ SG_ 595 ADV_CeremonyModeReq "This signal indicates the ADV request of ceremony mode.";
CM_ SG_ 595 ADV_HornReq "This signal indicates the ADV request of horn.";
CM_ SG_ 595 ADV_AVPFucntion_SpeechControlFee "This signal indicates the feedback to AVP function speech control.";
CM_ SG_ 595 ADV_HPASuspendStatus "Indicates the susend status of HPA";
CM_ SG_ 595 LiveCounter_ADV_5 "The Livecounter is used to check the signal consistency of the messages . If the signals are consecutive, the LiveCounter should also be sequential in the way 0, 1, 2 °≠15, 0, 1 °≠";
CM_ SG_ 967 ADV_AVPFunctionTip "This signal indicates the funtction tip of AVP.";
CM_ SG_ 967 ADV_HPAFunctionTip "This signal indicates the funtction tip of HPA.";
CM_ SG_ 967 ADV_AVPStatus "AVP working Status";
CM_ SG_ 967 ADV_HPAStatus "HPA working Status";
CM_ SG_ 967 ADV_CeromonyModeReq_AtmosphereLi "This signal indicate the atmosphere light ceromony mode request from auto parking ECU.";
CM_ SG_ 967 ADV_CeromonyModeReq_CPillerLight "This signal indicate the C piller light ceromony mode request from auto parking ECU.";
CM_ SG_ 967 ADV_BreatheFreqReq_CPillerLight "This signal indicate the C piller light breathe frequency request from auto parking ECU.";
CM_ SG_ 967 ADV_ColorReq_CPillerLight "This signal indicate the C piller light breathe frequency request from auto parking ECU.";
CM_ SG_ 967 ADV_CeromonyModeReq_FrontGrilleL "This signal indicate the Front Grille Light  ceromony mode request from auto parking ECU.";
CM_ SG_ 967 ADV_BreatheFreqReq_FrontGrilleLi "This signal indicate the Front Grille Light  breathe frequency request from auto parking ECU.";
CM_ SG_ 967 ADV_ColorReq_FrontGrilleLight "This signal indicate the Front Grille Light breathe frequency request from auto parking ECU.";
CM_ SG_ 967 ADV_WOBCStopChargeReq "This signal indicate the reuqest of stoping wobc charging.";
CM_ SG_ 967 ADV_WOBCEnquiryConfirm "This signal indicate the confirm information of WOBC enquiry.";
CM_ SG_ 967 LiveCounter_ADV_6 "The Livecounter is used to check the signal consistency of the messages . If the signals are consecutive, the LiveCounter should also be sequential in the way 0, 1, 2 °≠15, 0, 1 °≠";
CM_ SG_ 600 AVSSt "This signal indicates the AVS system status.";
CM_ SG_ 600 AVSErrorSt "This signal indicates the AVS system error status.";
CM_ SG_ 600 AVSViewMode "This signal indicates the AVS view mode";
CM_ SG_ 600 AVSViewtype "This signal indicates the AVS view type.";
CM_ SG_ 600 AVSCameraErrorSt_Front "This signal indicates AVS front camera error status";
CM_ SG_ 600 AVSCameraErrorSt_Rear "This signal indicates AVS rear camera error status";
CM_ SG_ 600 AVSCameraErrorSt_Left "This signal indicates AVS left camera error status";
CM_ SG_ 600 AVSCameraErrorSt_Right "This signal indicates AVS right camera error status";
CM_ SG_ 600 LanguageTypeSt_AVS "The signal indicates the AVS language type status .,Signal Initial=last value";
CM_ SG_ 600 DynamicPGSSt_AVS "This signal indicates the AVS dynamic PGS status,Signal Initial=last value";
CM_ SG_ 600 MODSt_AVS "This signal indicates the AVS MOD status,Signal Initial=last value";
CM_ SG_ 600 MODWarning_Front "This signal indicates AVS MOD front warning";
CM_ SG_ 600 MODWarning_Rear "This signal indicates AVS MOD rear warning";
CM_ SG_ 600 SwitchScreenRequest_AVS "AVS request IVI to switch the screen in case of lever R, lever P or voice control command or etc";
CM_ SG_ 600 BlindSpotFilledFunctionInd "Indicates the blind spot filled function status,Signal Initial=last value";
CM_ SG_ 600 FoundSlotBuzzerTip "Indicates the buzzer tip of found slot";
CM_ SG_ 600 AVS_SpeechControlFeedback "This signal indicates AVS speech control feedback";
CM_ SG_ 600 AVSCameraBlockageSt_Front "This signal indicates AVS front camera Blockage status";
CM_ SG_ 600 AVSCameraBlockageSt_Rear "This signal indicates AVS rear camera Blockage status";
CM_ SG_ 600 AVSCameraBlockageSt_Left "This signal indicates AVS left camera Blockage status";
CM_ SG_ 600 AVSCameraBlockageSt_Right "This signal indicates AVS right camera Blockage status";
CM_ SG_ 600 AVS_AbnormalTip "AVS abnormal tips.";
CM_ SG_ 600 AVS_CalibrationSt "AVS calibration status.,Signal Initial=last value";
CM_ SG_ 600 AVS_PDWarning_Front "PD warning status";
CM_ SG_ 600 AVS_PDWarning_Rear "PD warning status";
CM_ SG_ 600 AVS_RemoteMonitorigFeedback "This signal indicates AVS remote monitoring feedback";
CM_ SG_ 600 AVS_RemoteSharpnessFeedback "This signal indicates AVS remote sharpness feedback";
CM_ SG_ 600 RemoteMonitoringSharpnessSt_AVS "This signal indicates the remote monitoring sharpness setting status.,Signal Initial=last value";
CM_ SG_ 600 RemoteMonitoringSt_AVS "This signal indicates the remote monitoring status.";
CM_ SG_ 600 RemoteMonitoringModeSt_AVS "This signal indicates the remote monitoring mode status.";
CM_ SG_ 600 AVS_RemoteViewModeFeedback "This signal indicates AVS remote view mode feedback";
CM_ SG_ 599 Checksum_AVP_1 "The checksum is used to check whether the data from the CPU buffer are shifted without transmission errors to the CAN communication controller buffer and vice versa.";
CM_ SG_ 599 AVP_AutoDriveDataRecordAvailable "This signal indicates AVP automotive data record available or not";
CM_ SG_ 599 AVP_AutoDriveDataRecordStatus "AVP automotive drive data recode status";
CM_ SG_ 599 LiveCounter_AVP_1 "The Livecounter is used to check the signal consistency of the messages . If the signals are consecutive, the LiveCounter should also be sequential in the way 0, 1, 2 °≠15, 0, 1 °≠";
CM_ SG_ 604 SysSt_PDC "This signal indicate the PDC system status";
CM_ SG_ 604 ErrorSt_PDC "This signal indicates the error status of the PDC system.";
CM_ SG_ 604 RadarSysSt_Front "This signal indicates the working status of front radar system";
CM_ SG_ 604 RadarSysSt_Rear "This signal indicates the working status of rear radar system";
CM_ SG_ 604 BuzeerCmd_PDC "This signal is used for buzzer warning to remind the PDC status for driver.";
CM_ SG_ 604 BuzzerAlarmPosition "This signal indicates the alarm position of buzzer.";
CM_ SG_ 604 RadarSysSt_FrontSide "This signal indicates the working status of the front side radar system.";
CM_ SG_ 604 RadarSysSt_RearSide "This signal indicates the working status of the rear side radar system.";
CM_ SG_ 604 BuzzerSwitchSt "This signal indicates the buzzer switch status.";
CM_ SG_ 604 ObjectRange_RR "This signal indicates the rear right object's range.";
CM_ SG_ 604 SensorErrorSt_RR "This signal indicates if the rear right radar sensor error or not,";
CM_ SG_ 604 ObjectRange_RMR "This signal indicates the rear middle object's range. ";
CM_ SG_ 604 SensorErrorSt_RMR "This signal indicates if the rear middle right radar sensor error or not,";
CM_ SG_ 604 ObjectRange_RML "This signal indicates the rear middle left object's range";
CM_ SG_ 604 SensorErrorSt_RML "This signal indicates if the rear middle left radar sensor error or not,";
CM_ SG_ 604 ObjectRange_RL "This signal indicates the rear left object's range";
CM_ SG_ 604 SensorErrorSt_RL "This signal indicates if the rear left radar sensor error or not,";
CM_ SG_ 604 ObjectRange_FR "This signal indicates the front right object's range";
CM_ SG_ 604 SensorErrorSt_FR "This signal indicates if the front right radar sensor error or not,";
CM_ SG_ 604 ObjectRange_FMR "This signal indicates the front middle object's range";
CM_ SG_ 604 SensorErrorSt_FMR "This signal indicates if the front middle right radar sensor error or not,";
CM_ SG_ 604 ObjectRange_FML "This signal indicates the front middle left object's range";
CM_ SG_ 604 SensorErrorSt_FML "This signal indicates if the front middle left radar sensor  error or not.";
CM_ SG_ 604 ObjectRange_FL "This signal indicates the front left object's range";
CM_ SG_ 604 SensorErrorSt_FL "This signal indicates if the front left radar sensor  error or not.";
CM_ SG_ 604 PDCAutoOnFunctionInd "This signal indicates if the PDC auto on function on or not.";
CM_ SG_ 604 SwitchScreenRequest_PDC "PDC request IVI to switch the screen in case of object detected.";
CM_ SG_ 604 PDC_SpeechControlFeedback "PDC Speech Control Feedback";
CM_ SG_ 604 PDC_SearchingSlotPosition "PDC Searching Slot Position";
CM_ SG_ 604 PDC_FunctionTip "This signal indicates if the searching function is OK for PDC";
CM_ SG_ 456 Checksum_PDC_11 "The checksum is used to check whether the data from the CPU buffer are shifted without transmission errors to the CAN communication controller buffer and vice versa.";
CM_ SG_ 456 CCoordinateY_Left "This signal indicates the Y coordinate of parking cell point C.0x3FE means no object was detected.";
CM_ SG_ 456 CCoordinateX_Left "This signal indicates the X coordinate of parking cell point C.0xFFE means no object was detected.";
CM_ SG_ 456 DCoordinateY_Left "This signal indicates the Y coordinate of parking cell point D.0x3FE means no object was detected.";
CM_ SG_ 456 DCoordinateX_Left "This signal indicates the X coordinate of parking cell point D.0xFFE means no object was detected.";
CM_ SG_ 456 LiveCounter_PDC_11 "The Livecounter is used to check the signal consistency of the messages . If the signals are consecutive, the LiveCounter should also be sequential in the way 0, 1, 2 °≠15, 0, 1 °≠";
BA_DEF_ SG_  "GenSigStartValue" INT 0 1000000000;
BA_DEF_ BO_  "GenMsgILSupport" ENUM  "No","Yes";
BA_DEF_ BO_  "CanTpSTmin" INT 0 0;
BA_DEF_ BO_  "CanTpFcFrameId" HEX 0 2147483647;
BA_DEF_ SG_  "GenSigSendType" ENUM  "Cyclic","OnWrite","OnWriteWithRepetition","OnChange","OnChangeWithRepetition","IfActive","IfActiveWithRepetition","NoSigSendType";
BA_DEF_ BO_  "GenMsgCycleTime" INT 0 50000;
BA_DEF_ BO_  "GenMsgSendType" ENUM  "Cyclic","not_used","not_used","not_used","not_used","Cyclic","not_used","IfActive","NoMsgSendType","Spontaneous","CyclicAndSpontaneous","NoMsgSendType";
BA_DEF_ SG_  "GenSigInvalidValue" INT 0 0;
BA_DEF_ SG_  "GenSigStartRemark" STRING ;
BA_DEF_ SG_  "GenSigInvalidRemark" STRING ;
BA_DEF_ SG_  "GenSigEvent" STRING ;
BA_DEF_ SG_  "SystemSignalLongSymbol" STRING ;
BA_DEF_REL_ BU_SG_REL_  "GenSigTimeoutTime" INT 0 5000;
BA_DEF_DEF_  "GenSigStartValue" 0;
BA_DEF_DEF_  "GenMsgILSupport" "Yes";
BA_DEF_DEF_  "CanTpSTmin" 1;
BA_DEF_DEF_  "CanTpFcFrameId" 2147483647;
BA_DEF_DEF_  "GenSigSendType" "NoSigSendType";
BA_DEF_DEF_  "GenMsgCycleTime" 0;
BA_DEF_DEF_  "GenMsgSendType" "NoMsgSendType";
BA_DEF_DEF_  "GenSigInvalidValue" 0;
BA_DEF_DEF_  "GenSigStartRemark" "";
BA_DEF_DEF_  "GenSigInvalidRemark" "";
BA_DEF_DEF_  "GenSigEvent" "";
BA_DEF_DEF_REL_ "GenSigTimeoutTime" 0;
BA_DEF_DEF_  "SystemSignalLongSymbol" "";
BA_ "GenMsgSendType" BO_ 282 0;
BA_ "GenMsgCycleTime" BO_ 282 20;
BA_ "GenMsgSendType" BO_ 283 0;
BA_ "GenMsgCycleTime" BO_ 283 20;
BA_ "GenMsgSendType" BO_ 278 0;
BA_ "GenMsgCycleTime" BO_ 278 20;
BA_ "GenMsgSendType" BO_ 272 0;
BA_ "GenMsgCycleTime" BO_ 272 20;
BA_ "GenMsgSendType" BO_ 275 0;
BA_ "GenMsgCycleTime" BO_ 275 20;
BA_ "GenMsgSendType" BO_ 294 0;
BA_ "GenMsgCycleTime" BO_ 294 20;
BA_ "GenMsgSendType" BO_ 295 0;
BA_ "GenMsgCycleTime" BO_ 295 20;
BA_ "GenMsgSendType" BO_ 274 0;
BA_ "GenMsgCycleTime" BO_ 274 20;
BA_ "GenMsgSendType" BO_ 279 0;
BA_ "GenMsgCycleTime" BO_ 279 20;
BA_ "GenMsgCycleTime" BO_ 607 100;
BA_ "GenMsgSendType" BO_ 607 0;
BA_ "GenMsgCycleTime" BO_ 608 100;
BA_ "GenMsgSendType" BO_ 608 0;
BA_ "GenMsgCycleTime" BO_ 609 100;
BA_ "GenMsgSendType" BO_ 609 0;
BA_ "GenMsgCycleTime" BO_ 610 100;
BA_ "GenMsgSendType" BO_ 610 0;
BA_ "GenMsgCycleTime" BO_ 611 100;
BA_ "GenMsgSendType" BO_ 611 0;
BA_ "GenMsgSendType" BO_ 592 0;
BA_ "GenMsgCycleTime" BO_ 592 100;
BA_ "GenMsgSendType" BO_ 593 0;
BA_ "GenMsgCycleTime" BO_ 593 100;
BA_ "GenMsgSendType" BO_ 613 0;
BA_ "GenMsgCycleTime" BO_ 613 100;
BA_ "GenMsgSendType" BO_ 595 0;
BA_ "GenMsgCycleTime" BO_ 595 100;
BA_ "GenMsgCycleTime" BO_ 967 100;
BA_ "GenMsgSendType" BO_ 967 0;
BA_ "GenMsgCycleTime" BO_ 600 100;
BA_ "GenMsgSendType" BO_ 600 0;
BA_ "GenMsgCycleTime" BO_ 599 100;
BA_ "GenMsgSendType" BO_ 599 0;
BA_ "GenMsgCycleTime" BO_ 604 100;
BA_ "GenMsgSendType" BO_ 604 0;
BA_ "GenMsgSendType" BO_ 456 0;
BA_ "GenMsgCycleTime" BO_ 456 50;
BA_ "GenSigStartRemark" SG_ 282 Checksum_HAD_3 "V";
BA_ "GenSigInvalidRemark" SG_ 282 HAD_SpeedChangeRequest_L3 "2042";
BA_ "GenSigStartRemark" SG_ 282 HAD_SpeedChangeRequest_L3 "2042";
BA_ "GenSigInvalidValue" SG_ 282 HAD_SpeedChangeRequest_L3 2047;
BA_ "GenSigStartValue" SG_ 282 HAD_SpeedChangeRequest_L3 2046;
BA_ "GenSigInvalidRemark" SG_ 282 HAD_MaxAccGrad_L3 "127";
BA_ "GenSigStartRemark" SG_ 282 HAD_MaxAccGrad_L3 "127";
BA_ "GenSigInvalidValue" SG_ 282 HAD_MaxAccGrad_L3 255;
BA_ "GenSigStartValue" SG_ 282 HAD_MaxAccGrad_L3 254;
BA_ "GenSigInvalidRemark" SG_ 282 HAD_MinAccGrad_L3 "127";
BA_ "GenSigStartRemark" SG_ 282 HAD_MinAccGrad_L3 "127";
BA_ "GenSigInvalidValue" SG_ 282 HAD_MinAccGrad_L3 255;
BA_ "GenSigStartValue" SG_ 282 HAD_MinAccGrad_L3 254;
BA_ "GenSigInvalidRemark" SG_ 282 HAD_MaxComfBand_L3 "90";
BA_ "GenSigStartRemark" SG_ 282 HAD_MaxComfBand_L3 "90";
BA_ "GenSigInvalidValue" SG_ 282 HAD_MaxComfBand_L3 255;
BA_ "GenSigStartValue" SG_ 282 HAD_MaxComfBand_L3 254;
BA_ "GenSigInvalidRemark" SG_ 282 HAD_MinComfBand_L3 "90";
BA_ "GenSigStartRemark" SG_ 282 HAD_MinComfBand_L3 "90";
BA_ "GenSigInvalidValue" SG_ 282 HAD_MinComfBand_L3 255;
BA_ "GenSigStartValue" SG_ 282 HAD_MinComfBand_L3 254;
BA_ "GenSigStartRemark" SG_ 283 Checksum_HAD_4 "V";
BA_ "GenSigStartRemark" SG_ 278 Checksum_HAD_6 "V";
BA_ "GenSigInvalidRemark" SG_ 278 HAD_TorqueRequest "O";
BA_ "GenSigStartRemark" SG_ 278 HAD_TorqueRequest "O";
BA_ "GenSigInvalidValue" SG_ 278 HAD_TorqueRequest 1023;
BA_ "GenSigStartValue" SG_ 278 HAD_TorqueRequest 1022;
BA_ "GenSigStartRemark" SG_ 278 HAD_WorkingSt_LKA "L";
BA_ "GenSigStartRemark" SG_ 278 HAD_WorkingSt_LCA "L";
BA_ "GenSigStartRemark" SG_ 278 HAD_WorkingSt_DCLC "L";
BA_ "GenSigStartRemark" SG_ 278 HAD_WorkingSt_HWP "L";
BA_ "GenSigStartRemark" SG_ 278 HAD_WorkingSt_TJP "L";
BA_ "GenSigStartRemark" SG_ 272 Checksum_IFC_1 "V";
BA_ "GenSigStartValue" SG_ 272 IFC_WorkingSt_AEB_L12 1;
BA_ "GenSigStartRemark" SG_ 272 CruiseModeFunctionInd "L";
BA_ "GenSigStartRemark" SG_ 275 Checksum_IFC_6 "V";
BA_ "GenSigInvalidRemark" SG_ 275 IFC_SpeedChangeRequest_L12 "2042";
BA_ "GenSigStartRemark" SG_ 275 IFC_SpeedChangeRequest_L12 "2042";
BA_ "GenSigInvalidValue" SG_ 275 IFC_SpeedChangeRequest_L12 2047;
BA_ "GenSigStartValue" SG_ 275 IFC_SpeedChangeRequest_L12 2046;
BA_ "GenSigInvalidRemark" SG_ 275 IFC_MaxAccGrad_L12 "127";
BA_ "GenSigStartRemark" SG_ 275 IFC_MaxAccGrad_L12 "127";
BA_ "GenSigInvalidValue" SG_ 275 IFC_MaxAccGrad_L12 255;
BA_ "GenSigStartValue" SG_ 275 IFC_MaxAccGrad_L12 254;
BA_ "GenSigInvalidRemark" SG_ 275 IFC_MinAccGrad_L12 "127";
BA_ "GenSigStartRemark" SG_ 275 IFC_MinAccGrad_L12 "127";
BA_ "GenSigInvalidValue" SG_ 275 IFC_MinAccGrad_L12 255;
BA_ "GenSigStartValue" SG_ 275 IFC_MinAccGrad_L12 254;
BA_ "GenSigInvalidRemark" SG_ 275 IFC_MaxComfBand_L12 "90";
BA_ "GenSigStartRemark" SG_ 275 IFC_MaxComfBand_L12 "90";
BA_ "GenSigInvalidValue" SG_ 275 IFC_MaxComfBand_L12 255;
BA_ "GenSigStartValue" SG_ 275 IFC_MaxComfBand_L12 254;
BA_ "GenSigInvalidRemark" SG_ 275 IFC_MinComfBand_L12 "90";
BA_ "GenSigStartRemark" SG_ 275 IFC_MinComfBand_L12 "90";
BA_ "GenSigInvalidValue" SG_ 275 IFC_MinComfBand_L12 255;
BA_ "GenSigStartValue" SG_ 275 IFC_MinComfBand_L12 254;
BA_ "GenSigStartRemark" SG_ 294 Checksum_FOU_1 "V";
BA_ "GenSigInvalidRemark" SG_ 294 FOU_SpeedChangeRequest_L3 "2042";
BA_ "GenSigStartRemark" SG_ 294 FOU_SpeedChangeRequest_L3 "2042";
BA_ "GenSigInvalidValue" SG_ 294 FOU_SpeedChangeRequest_L3 2047;
BA_ "GenSigStartValue" SG_ 294 FOU_SpeedChangeRequest_L3 2046;
BA_ "GenSigInvalidRemark" SG_ 294 FOU_MaxAccGrad_L3 "127";
BA_ "GenSigStartRemark" SG_ 294 FOU_MaxAccGrad_L3 "127";
BA_ "GenSigInvalidValue" SG_ 294 FOU_MaxAccGrad_L3 255;
BA_ "GenSigStartValue" SG_ 294 FOU_MaxAccGrad_L3 254;
BA_ "GenSigInvalidRemark" SG_ 294 FOU_MinAccGrad_L3 "127";
BA_ "GenSigStartRemark" SG_ 294 FOU_MinAccGrad_L3 "127";
BA_ "GenSigInvalidValue" SG_ 294 FOU_MinAccGrad_L3 255;
BA_ "GenSigStartValue" SG_ 294 FOU_MinAccGrad_L3 254;
BA_ "GenSigInvalidRemark" SG_ 294 FOU_MaxComfBand_L3 "90";
BA_ "GenSigStartRemark" SG_ 294 FOU_MaxComfBand_L3 "90";
BA_ "GenSigInvalidValue" SG_ 294 FOU_MaxComfBand_L3 255;
BA_ "GenSigStartValue" SG_ 294 FOU_MaxComfBand_L3 254;
BA_ "GenSigInvalidRemark" SG_ 294 FOU_MinComfBand_L3 "90";
BA_ "GenSigStartRemark" SG_ 294 FOU_MinComfBand_L3 "90";
BA_ "GenSigInvalidValue" SG_ 294 FOU_MinComfBand_L3 255;
BA_ "GenSigStartValue" SG_ 294 FOU_MinComfBand_L3 254;
BA_ "GenSigStartRemark" SG_ 295 Checksum_FOU_2 "V";
BA_ "GenSigStartRemark" SG_ 274 Checksum_IFC_4 "V";
BA_ "GenSigInvalidRemark" SG_ 274 IFC_TorqueRequest "O";
BA_ "GenSigStartRemark" SG_ 274 IFC_TorqueRequest "O";
BA_ "GenSigInvalidValue" SG_ 274 IFC_TorqueRequest 1023;
BA_ "GenSigStartValue" SG_ 274 IFC_TorqueRequest 1022;
BA_ "GenSigStartRemark" SG_ 274 IFC_WorkingSt_LKA "L";
BA_ "GenSigStartRemark" SG_ 274 IFC_WorkingSt_LCA "L";
BA_ "GenSigStartRemark" SG_ 274 IFC_WorkingSt_SACC "L";
BA_ "GenSigStartRemark" SG_ 274 FOU_WorkingSt_HWP "L";
BA_ "GenSigStartRemark" SG_ 274 FOU_WorkingSt_TJP "L";
BA_ "GenSigStartRemark" SG_ 279 Checksum_IFC_5 "V";
BA_ "GenSigInvalidRemark" SG_ 279 IFC_SteeringWheelAngleRequest "O";
BA_ "GenSigInvalidValue" SG_ 279 IFC_SteeringWheelAngleRequest 32767;
BA_ "SystemSignalLongSymbol" SG_ 279 IFC_SteeringWheelAngleSignReques "IFC_SteeringWheelAngleSignRequest";
BA_ "SystemSignalLongSymbol" SG_ 279 IFC_SteeringWheelAngleControlReq "IFC_SteeringWheelAngleControlRequest";
BA_ "GenSigInvalidRemark" SG_ 607 HAD_CruiseSpeedSetting_ACC "O";
BA_ "GenSigStartRemark" SG_ 607 HAD_CruiseSpeedSetting_ACC "O";
BA_ "GenSigInvalidValue" SG_ 607 HAD_CruiseSpeedSetting_ACC 255;
BA_ "GenSigStartValue" SG_ 607 HAD_CruiseSpeedSetting_ACC 254;
BA_ "GenSigEvent" SG_ 607 HAD_TimeGapSetting "Y";
BA_ "GenSigSendType" SG_ 607 HAD_TimeGapSetting 1;
BA_ "GenSigStartValue" SG_ 607 HAD_TimeGapSetting 3;
BA_ "GenSigStartRemark" SG_ 607 HAD_LDWModeInd "L";
BA_ "GenSigEvent" SG_ 607 HAD_TakeOverReq "Y";
BA_ "GenSigSendType" SG_ 607 HAD_TakeOverReq 1;
BA_ "GenSigEvent" SG_ 607 HAD_AutoLightModeReq "Y";
BA_ "GenSigSendType" SG_ 607 HAD_AutoLightModeReq 1;
BA_ "GenSigEvent" SG_ 607 HAD_HazardWarningLampRequest "Y";
BA_ "GenSigSendType" SG_ 607 HAD_HazardWarningLampRequest 1;
BA_ "GenSigStartValue" SG_ 607 HAD_WorkingSt_LDW 1;
BA_ "GenSigEvent" SG_ 607 HAD_WarningCmd_LDW "Y";
BA_ "GenSigSendType" SG_ 607 HAD_WarningCmd_LDW 1;
BA_ "GenSigStartRemark" SG_ 607 HAD_SensitivityInd_LDW "L";
BA_ "GenSigStartValue" SG_ 607 HAD_WorkingSt_FCW 1;
BA_ "GenSigEvent" SG_ 607 HAD_WarningCmd_FCW "Y";
BA_ "GenSigSendType" SG_ 607 HAD_WarningCmd_FCW 1;
BA_ "GenSigStartRemark" SG_ 607 HAD_SensitivityInd_FCW "L";
BA_ "GenSigStartValue" SG_ 607 HAD_FCWModeInd 1;
BA_ "GenSigEvent" SG_ 607 HAD_LDW_SpeechControlFeedback "Y";
BA_ "GenSigSendType" SG_ 607 HAD_LDW_SpeechControlFeedback 1;
BA_ "GenSigStartRemark" SG_ 607 HAD_ValetModeStatus "L";
BA_ "GenSigInvalidRemark" SG_ 608 CruiseSpeedSetting_ACC "O";
BA_ "GenSigStartRemark" SG_ 608 CruiseSpeedSetting_ACC "O";
BA_ "GenSigInvalidValue" SG_ 608 CruiseSpeedSetting_ACC 255;
BA_ "GenSigStartValue" SG_ 608 CruiseSpeedSetting_ACC 254;
BA_ "GenSigEvent" SG_ 608 TimeGapSetting "Y";
BA_ "GenSigSendType" SG_ 608 TimeGapSetting 1;
BA_ "GenSigStartValue" SG_ 608 TimeGapSetting 3;
BA_ "GenSigStartRemark" SG_ 608 LDWModeInd "L";
BA_ "GenSigEvent" SG_ 608 TakeOverReq "Y";
BA_ "GenSigSendType" SG_ 608 TakeOverReq 1;
BA_ "GenSigEvent" SG_ 608 AutoLightModeReq "Y";
BA_ "GenSigSendType" SG_ 608 AutoLightModeReq 1;
BA_ "GenSigEvent" SG_ 608 HazardWarningLampRequest "Y";
BA_ "GenSigSendType" SG_ 608 HazardWarningLampRequest 1;
BA_ "GenSigStartValue" SG_ 608 WorkingSt_LDW 1;
BA_ "GenSigEvent" SG_ 608 WarningCmd_LDW "Y";
BA_ "GenSigSendType" SG_ 608 WarningCmd_LDW 1;
BA_ "GenSigStartRemark" SG_ 608 SensitivityInd_LDW "L";
BA_ "GenSigStartValue" SG_ 608 WorkingSt_FCW 1;
BA_ "GenSigEvent" SG_ 608 WarningCmd_FCW "Y";
BA_ "GenSigSendType" SG_ 608 WarningCmd_FCW 1;
BA_ "GenSigStartRemark" SG_ 608 SensitivityInd_FCW "L";
BA_ "GenSigStartValue" SG_ 608 FCWModeInd 1;
BA_ "GenSigEvent" SG_ 608 LDW_SpeechControlFeedback "Y";
BA_ "GenSigSendType" SG_ 608 LDW_SpeechControlFeedback 1;
BA_ "GenSigInvalidRemark" SG_ 609 HAD_LimitedVehicleSpeed_TSR "O";
BA_ "GenSigStartRemark" SG_ 609 HAD_LimitedVehicleSpeed_TSR "O";
BA_ "GenSigInvalidValue" SG_ 609 HAD_LimitedVehicleSpeed_TSR 255;
BA_ "GenSigStartValue" SG_ 609 HAD_LimitedVehicleSpeed_TSR 254;
BA_ "GenSigStartRemark" SG_ 609 HAD_WorkingSt_TSR "L";
BA_ "GenSigEvent" SG_ 609 HAD_VAS_SpeechControlFeedback "Y";
BA_ "GenSigSendType" SG_ 609 HAD_VAS_SpeechControlFeedback 1;
BA_ "GenSigEvent" SG_ 609 HAD_TSR_SpeechControlFeedback "Y";
BA_ "GenSigSendType" SG_ 609 HAD_TSR_SpeechControlFeedback 1;
BA_ "GenSigInvalidRemark" SG_ 610 LimitedVehicleSpeed_TSR "O";
BA_ "GenSigStartRemark" SG_ 610 LimitedVehicleSpeed_TSR "O";
BA_ "GenSigInvalidValue" SG_ 610 LimitedVehicleSpeed_TSR 255;
BA_ "GenSigStartValue" SG_ 610 LimitedVehicleSpeed_TSR 254;
BA_ "GenSigStartRemark" SG_ 610 WorkingSt_TSR "L";
BA_ "GenSigStartRemark" SG_ 610 WorkingSt_DSM "L";
BA_ "GenSigEvent" SG_ 610 VAS_SpeechControlFeedback "Y";
BA_ "GenSigSendType" SG_ 610 VAS_SpeechControlFeedback 1;
BA_ "GenSigEvent" SG_ 610 TSR_SpeechControlFeedback "Y";
BA_ "GenSigSendType" SG_ 610 TSR_SpeechControlFeedback 1;
BA_ "GenSigEvent" SG_ 610 DSM_SpeechControlFeedback "Y";
BA_ "GenSigSendType" SG_ 610 DSM_SpeechControlFeedback 1;
BA_ "GenSigStartRemark" SG_ 611 Checksum_IFC_11 "V";
BA_ "GenSigStartRemark" SG_ 611 HAD_AutoDrivingSt "L";
BA_ "GenSigStartRemark" SG_ 592 Checksum_ADV_1 "V";
BA_ "GenSigStartRemark" SG_ 592 ADV_ParkType "L";
BA_ "GenSigStartRemark" SG_ 592 ADV_ParkInSlotSearchMode "L";
BA_ "GenSigStartValue" SG_ 592 ADV_ParkOutDirection 1;
BA_ "GenSigStartRemark" SG_ 592 ADV_ParkingAEBFunctionInd "L";
BA_ "GenSigStartRemark" SG_ 592 ADV_BacktrackFunctionInd "L";
BA_ "GenSigStartRemark" SG_ 593 Checksum_ADV_4 "V";
BA_ "SystemSignalLongSymbol" SG_ 593 ADV_APAFuncntion_SpeechControlFe "ADV_APAFuncntion_SpeechControlFeedback";
BA_ "SystemSignalLongSymbol" SG_ 593 ADV_ParkInMode_SpeechControlFeed "ADV_ParkInMode_SpeechControlFeedback";
BA_ "SystemSignalLongSymbol" SG_ 593 ADV_ParkInType_SpeechControlFeed "ADV_ParkInType_SpeechControlFeedback";
BA_ "SystemSignalLongSymbol" SG_ 593 ADV_ParkOutFunc_SpeechControlFee "ADV_ParkOutFunc_SpeechControlFeedback";
BA_ "SystemSignalLongSymbol" SG_ 593 ADV_ParkOutType_SpeechControlFee "ADV_ParkOutType_SpeechControlFeedback";
BA_ "GenSigStartRemark" SG_ 613 Checksum_HAD_5 "V";
BA_ "GenSigStartRemark" SG_ 613 HAD_SetdestinationFuncSt "L";
BA_ "GenSigStartRemark" SG_ 613 HAD_ChangeLaneManualFuncSt "L";
BA_ "GenSigStartRemark" SG_ 613 HAD_AutoDrivingStyle "L";
BA_ "GenSigStartRemark" SG_ 613 HAD_ChangeLaneAutoFuncSt "L";
BA_ "SystemSignalLongSymbol" SG_ 613 HAD_AutoDrivingNotSatisfiedCondi "HAD_AutoDrivingNotSatisfiedCondition_L3";
BA_ "GenSigStartRemark" SG_ 595 Checksum_ADV_5 "V";
BA_ "GenSigStartRemark" SG_ 595 ADV_CIDLocationReq "L";
BA_ "GenSigStartRemark" SG_ 595 ADV_AVPHazardWarningFunctionInd "L";
BA_ "GenSigStartRemark" SG_ 595 ADV_HPAHazardWarningFunctionInd "L";
BA_ "GenSigStartRemark" SG_ 595 ADV_AVPTypeIndication "L";
BA_ "GenSigStartRemark" SG_ 595 ADV_AVPSearchingTypeInd "L";
BA_ "GenSigStartRemark" SG_ 595 ADV_HPATypeIndication "L";
BA_ "GenSigStartRemark" SG_ 595 ADV_HPASearchingTypeInd "L";
BA_ "GenSigStartRemark" SG_ 595 ADV_AVPParkingLotPushFunctionInd "L";
BA_ "GenSigStartRemark" SG_ 595 ADV_HPAParkingLotPushFunctionInd "L";
BA_ "SystemSignalLongSymbol" SG_ 595 ADV_HPAFucntion_SpeechControlFee "ADV_HPAFucntion_SpeechControlFeedback";
BA_ "SystemSignalLongSymbol" SG_ 595 ADV_AVPFucntion_SpeechControlFee "ADV_AVPFucntion_SpeechControlFeedback";
BA_ "GenSigStartRemark" SG_ 967 Checksum_ADV_6 "V";
BA_ "SystemSignalLongSymbol" SG_ 967 ADV_CeromonyModeReq_AtmosphereLi "ADV_CeromonyModeReq_AtmosphereLight";
BA_ "SystemSignalLongSymbol" SG_ 967 ADV_CeromonyModeReq_FrontGrilleL "ADV_CeromonyModeReq_FrontGrilleLight";
BA_ "SystemSignalLongSymbol" SG_ 967 ADV_BreatheFreqReq_FrontGrilleLi "ADV_BreatheFreqReq_FrontGrilleLight";
BA_ "GenSigInvalidValue" SG_ 600 AVSViewMode 15;
BA_ "GenSigStartRemark" SG_ 600 LanguageTypeSt_AVS "L";
BA_ "GenSigStartRemark" SG_ 600 DynamicPGSSt_AVS "L";
BA_ "GenSigStartRemark" SG_ 600 MODSt_AVS "L";
BA_ "GenSigEvent" SG_ 600 SwitchScreenRequest_AVS "Y";
BA_ "GenSigSendType" SG_ 600 SwitchScreenRequest_AVS 1;
BA_ "GenSigStartRemark" SG_ 600 BlindSpotFilledFunctionInd "L";
BA_ "GenSigEvent" SG_ 600 AVS_AbnormalTip "Y";
BA_ "GenSigSendType" SG_ 600 AVS_AbnormalTip 1;
BA_ "GenSigEvent" SG_ 600 AVS_CalibrationSt "Y";
BA_ "GenSigSendType" SG_ 600 AVS_CalibrationSt 1;
BA_ "GenSigStartRemark" SG_ 600 AVS_CalibrationSt "L";
BA_ "GenSigEvent" SG_ 600 AVS_PDWarning_Front "Y";
BA_ "GenSigSendType" SG_ 600 AVS_PDWarning_Front 1;
BA_ "GenSigEvent" SG_ 600 AVS_PDWarning_Rear "Y";
BA_ "GenSigSendType" SG_ 600 AVS_PDWarning_Rear 1;
BA_ "GenSigEvent" SG_ 600 AVS_RemoteMonitorigFeedback "Y";
BA_ "GenSigSendType" SG_ 600 AVS_RemoteMonitorigFeedback 1;
BA_ "GenSigEvent" SG_ 600 RemoteMonitoringSharpnessSt_AVS "Y";
BA_ "GenSigSendType" SG_ 600 RemoteMonitoringSharpnessSt_AVS 1;
BA_ "GenSigStartRemark" SG_ 600 RemoteMonitoringSharpnessSt_AVS "L";
BA_ "GenSigEvent" SG_ 600 RemoteMonitoringSt_AVS "Y";
BA_ "GenSigSendType" SG_ 600 RemoteMonitoringSt_AVS 1;
BA_ "GenSigEvent" SG_ 600 RemoteMonitoringModeSt_AVS "Y";
BA_ "GenSigSendType" SG_ 600 RemoteMonitoringModeSt_AVS 1;
BA_ "GenSigStartRemark" SG_ 599 Checksum_AVP_1 "V";
BA_ "GenSigEvent" SG_ 599 AVP_AutoDriveDataRecordAvailable "Y";
BA_ "GenSigSendType" SG_ 599 AVP_AutoDriveDataRecordAvailable 1;
BA_ "GenSigEvent" SG_ 599 AVP_AutoDriveDataRecordStatus "Y";
BA_ "GenSigSendType" SG_ 599 AVP_AutoDriveDataRecordStatus 1;
BA_ "GenSigEvent" SG_ 604 ObjectRange_RR "Y";
BA_ "GenSigSendType" SG_ 604 ObjectRange_RR 1;
BA_ "GenSigInvalidValue" SG_ 604 ObjectRange_RR 7;
BA_ "GenSigEvent" SG_ 604 ObjectRange_RMR "Y";
BA_ "GenSigSendType" SG_ 604 ObjectRange_RMR 1;
BA_ "GenSigInvalidValue" SG_ 604 ObjectRange_RMR 7;
BA_ "GenSigEvent" SG_ 604 ObjectRange_RML "Y";
BA_ "GenSigSendType" SG_ 604 ObjectRange_RML 1;
BA_ "GenSigInvalidValue" SG_ 604 ObjectRange_RML 7;
BA_ "GenSigEvent" SG_ 604 ObjectRange_RL "Y";
BA_ "GenSigSendType" SG_ 604 ObjectRange_RL 1;
BA_ "GenSigInvalidValue" SG_ 604 ObjectRange_RL 7;
BA_ "GenSigEvent" SG_ 604 ObjectRange_FR "Y";
BA_ "GenSigSendType" SG_ 604 ObjectRange_FR 1;
BA_ "GenSigInvalidValue" SG_ 604 ObjectRange_FR 7;
BA_ "GenSigEvent" SG_ 604 ObjectRange_FMR "Y";
BA_ "GenSigSendType" SG_ 604 ObjectRange_FMR 1;
BA_ "GenSigInvalidValue" SG_ 604 ObjectRange_FMR 7;
BA_ "GenSigEvent" SG_ 604 ObjectRange_FML "Y";
BA_ "GenSigSendType" SG_ 604 ObjectRange_FML 1;
BA_ "GenSigInvalidValue" SG_ 604 ObjectRange_FML 7;
BA_ "GenSigEvent" SG_ 604 ObjectRange_FL "Y";
BA_ "GenSigSendType" SG_ 604 ObjectRange_FL 1;
BA_ "GenSigInvalidValue" SG_ 604 ObjectRange_FL 7;
BA_ "GenSigEvent" SG_ 604 SwitchScreenRequest_PDC "Y";
BA_ "GenSigSendType" SG_ 604 SwitchScreenRequest_PDC 1;
BA_ "GenSigEvent" SG_ 604 PDC_SpeechControlFeedback "Y";
BA_ "GenSigSendType" SG_ 604 PDC_SpeechControlFeedback 1;
BA_ "GenSigEvent" SG_ 604 PDC_SearchingSlotPosition "Y";
BA_ "GenSigSendType" SG_ 604 PDC_SearchingSlotPosition 1;
BA_ "GenSigEvent" SG_ 604 PDC_FunctionTip "Y";
BA_ "GenSigSendType" SG_ 604 PDC_FunctionTip 1;
BA_ "GenSigStartRemark" SG_ 456 Checksum_PDC_11 "V";
BA_ "GenSigInvalidRemark" SG_ 456 CCoordinateY_Left "500";
BA_ "GenSigStartRemark" SG_ 456 CCoordinateY_Left "500";
BA_ "GenSigInvalidValue" SG_ 456 CCoordinateY_Left 1023;
BA_ "GenSigStartValue" SG_ 456 CCoordinateY_Left 1022;
BA_ "GenSigInvalidRemark" SG_ 456 CCoordinateX_Left "3600";
BA_ "GenSigStartRemark" SG_ 456 CCoordinateX_Left "3600";
BA_ "GenSigInvalidValue" SG_ 456 CCoordinateX_Left 4095;
BA_ "GenSigStartValue" SG_ 456 CCoordinateX_Left 4094;
BA_ "GenSigInvalidRemark" SG_ 456 DCoordinateY_Left "500";
BA_ "GenSigStartRemark" SG_ 456 DCoordinateY_Left "500";
BA_ "GenSigInvalidValue" SG_ 456 DCoordinateY_Left 1023;
BA_ "GenSigStartValue" SG_ 456 DCoordinateY_Left 1022;
BA_ "GenSigInvalidRemark" SG_ 456 DCoordinateX_Left "3600";
BA_ "GenSigStartRemark" SG_ 456 DCoordinateX_Left "3600";
BA_ "GenSigInvalidValue" SG_ 456 DCoordinateX_Left 4095;
BA_ "GenSigStartValue" SG_ 456 DCoordinateX_Left 4094;
BA_REL_ "GenSigTimeoutTime" BU_SG_REL_ Gateway SG_ 282 Checksum_HAD_3 200;
BA_REL_ "GenSigTimeoutTime" BU_SG_REL_ CDS2 SG_ 282 Checksum_HAD_3 200;
BA_REL_ "GenSigTimeoutTime" BU_SG_REL_ HDMAP SG_ 282 Checksum_HAD_3 200;
BA_REL_ "GenSigTimeoutTime" BU_SG_REL_ Gateway SG_ 282 HAD_AutoDrivingReq_L3 200;
BA_REL_ "GenSigTimeoutTime" BU_SG_REL_ CDS2 SG_ 282 HAD_AutoDrivingReq_L3 200;
BA_REL_ "GenSigTimeoutTime" BU_SG_REL_ HDMAP SG_ 282 HAD_AutoDrivingReq_L3 200;
BA_REL_ "GenSigTimeoutTime" BU_SG_REL_ Gateway SG_ 282 HAD_SpeedChangeRequest_L3 200;
BA_REL_ "GenSigTimeoutTime" BU_SG_REL_ CDS2 SG_ 282 HAD_SpeedChangeRequest_L3 200;
BA_REL_ "GenSigTimeoutTime" BU_SG_REL_ HDMAP SG_ 282 HAD_SpeedChangeRequest_L3 200;
BA_REL_ "GenSigTimeoutTime" BU_SG_REL_ Gateway SG_ 282 HAD_MaxAccGrad_L3 200;
BA_REL_ "GenSigTimeoutTime" BU_SG_REL_ CDS2 SG_ 282 HAD_MaxAccGrad_L3 200;
BA_REL_ "GenSigTimeoutTime" BU_SG_REL_ Gateway SG_ 282 HAD_MinAccGrad_L3 200;
BA_REL_ "GenSigTimeoutTime" BU_SG_REL_ CDS2 SG_ 282 HAD_MinAccGrad_L3 200;
BA_REL_ "GenSigTimeoutTime" BU_SG_REL_ Gateway SG_ 282 HAD_MaxComfBand_L3 200;
BA_REL_ "GenSigTimeoutTime" BU_SG_REL_ CDS2 SG_ 282 HAD_MaxComfBand_L3 200;
BA_REL_ "GenSigTimeoutTime" BU_SG_REL_ Gateway SG_ 282 HAD_MinComfBand_L3 200;
BA_REL_ "GenSigTimeoutTime" BU_SG_REL_ CDS2 SG_ 282 HAD_MinComfBand_L3 200;
BA_REL_ "GenSigTimeoutTime" BU_SG_REL_ Gateway SG_ 282 HAD_UseMaxComfBand_L3 200;
BA_REL_ "GenSigTimeoutTime" BU_SG_REL_ CDS2 SG_ 282 HAD_UseMaxComfBand_L3 200;
BA_REL_ "GenSigTimeoutTime" BU_SG_REL_ HDMAP SG_ 282 HAD_HDMapUsingst_L3 200;
BA_REL_ "GenSigTimeoutTime" BU_SG_REL_ Gateway SG_ 282 LiveCounter_HAD_3 200;
BA_REL_ "GenSigTimeoutTime" BU_SG_REL_ CDS2 SG_ 282 LiveCounter_HAD_3 200;
BA_REL_ "GenSigTimeoutTime" BU_SG_REL_ HDMAP SG_ 282 LiveCounter_HAD_3 200;
BA_REL_ "GenSigTimeoutTime" BU_SG_REL_ Gateway SG_ 283 Checksum_HAD_4 200;
BA_REL_ "GenSigTimeoutTime" BU_SG_REL_ CDS2 SG_ 283 Checksum_HAD_4 200;
BA_REL_ "GenSigTimeoutTime" BU_SG_REL_ HDMAP SG_ 283 Checksum_HAD_4 200;
BA_REL_ "GenSigTimeoutTime" BU_SG_REL_ Gateway SG_ 283 HAD_BrakeModeReq_L3 200;
BA_REL_ "GenSigTimeoutTime" BU_SG_REL_ CDS2 SG_ 283 HAD_BrakeModeReq_L3 200;
BA_REL_ "GenSigTimeoutTime" BU_SG_REL_ Gateway SG_ 283 HAD_DrivedownReq_L3 200;
BA_REL_ "GenSigTimeoutTime" BU_SG_REL_ CDS2 SG_ 283 HAD_DrivedownReq_L3 200;
BA_REL_ "GenSigTimeoutTime" BU_SG_REL_ Gateway SG_ 283 HAD_SecureRequest_L3 200;
BA_REL_ "GenSigTimeoutTime" BU_SG_REL_ CDS2 SG_ 283 HAD_SecureRequest_L3 200;
BA_REL_ "GenSigTimeoutTime" BU_SG_REL_ Gateway SG_ 283 HAD_ErrorSt_AutoDriving_L3 200;
BA_REL_ "GenSigTimeoutTime" BU_SG_REL_ CDS2 SG_ 283 HAD_ErrorSt_AutoDriving_L3 200;
BA_REL_ "GenSigTimeoutTime" BU_SG_REL_ Gateway SG_ 283 LiveCounter_HAD_4 200;
BA_REL_ "GenSigTimeoutTime" BU_SG_REL_ CDS2 SG_ 283 LiveCounter_HAD_4 200;
BA_REL_ "GenSigTimeoutTime" BU_SG_REL_ HDMAP SG_ 283 LiveCounter_HAD_4 200;
BA_REL_ "GenSigTimeoutTime" BU_SG_REL_ Gateway SG_ 278 Checksum_HAD_6 200;
BA_REL_ "GenSigTimeoutTime" BU_SG_REL_ CDS2 SG_ 278 Checksum_HAD_6 200;
BA_REL_ "GenSigTimeoutTime" BU_SG_REL_ Gateway SG_ 278 HAD_TorqueRequest 200;
BA_REL_ "GenSigTimeoutTime" BU_SG_REL_ CDS2 SG_ 278 HAD_TorqueRequest 200;
BA_REL_ "GenSigTimeoutTime" BU_SG_REL_ Gateway SG_ 278 HAD_TorqueRequestSign 200;
BA_REL_ "GenSigTimeoutTime" BU_SG_REL_ CDS2 SG_ 278 HAD_TorqueRequestSign 200;
BA_REL_ "GenSigTimeoutTime" BU_SG_REL_ Gateway SG_ 278 HAD_TorqueReqSt 200;
BA_REL_ "GenSigTimeoutTime" BU_SG_REL_ CDS2 SG_ 278 HAD_TorqueReqSt 200;
BA_REL_ "GenSigTimeoutTime" BU_SG_REL_ Gateway SG_ 278 HAD_Intervention_LKA 200;
BA_REL_ "GenSigTimeoutTime" BU_SG_REL_ CDS2 SG_ 278 HAD_Intervention_LKA 200;
BA_REL_ "GenSigTimeoutTime" BU_SG_REL_ Gateway SG_ 278 HAD_WorkingSt_LKA 200;
BA_REL_ "GenSigTimeoutTime" BU_SG_REL_ CDS2 SG_ 278 HAD_WorkingSt_LKA 200;
BA_REL_ "GenSigTimeoutTime" BU_SG_REL_ Gateway SG_ 278 HAD_ErrorSt_LKA 200;
BA_REL_ "GenSigTimeoutTime" BU_SG_REL_ CDS2 SG_ 278 HAD_ErrorSt_LKA 200;
BA_REL_ "GenSigTimeoutTime" BU_SG_REL_ Gateway SG_ 278 HAD_TakeOverTip_LCA 200;
BA_REL_ "GenSigTimeoutTime" BU_SG_REL_ CDS2 SG_ 278 HAD_TakeOverTip_LCA 200;
BA_REL_ "GenSigTimeoutTime" BU_SG_REL_ Gateway SG_ 278 HAD_HandsOffTip_LCA 200;
BA_REL_ "GenSigTimeoutTime" BU_SG_REL_ CDS2 SG_ 278 HAD_HandsOffTip_LCA 200;
BA_REL_ "GenSigTimeoutTime" BU_SG_REL_ Gateway SG_ 278 HAD_WorkingSt_LCA 200;
BA_REL_ "GenSigTimeoutTime" BU_SG_REL_ CDS2 SG_ 278 HAD_WorkingSt_LCA 200;
BA_REL_ "GenSigTimeoutTime" BU_SG_REL_ Gateway SG_ 278 HAD_ErrorSt_LCA 200;
BA_REL_ "GenSigTimeoutTime" BU_SG_REL_ CDS2 SG_ 278 HAD_ErrorSt_LCA 200;
BA_REL_ "GenSigTimeoutTime" BU_SG_REL_ Gateway SG_ 278 HAD_AutoDrivingModeReq 200;
BA_REL_ "GenSigTimeoutTime" BU_SG_REL_ CDS2 SG_ 278 HAD_AutoDrivingModeReq 200;
BA_REL_ "GenSigTimeoutTime" BU_SG_REL_ Gateway SG_ 278 HAD_ErrorSt_SACC 200;
BA_REL_ "GenSigTimeoutTime" BU_SG_REL_ CDS2 SG_ 278 HAD_ErrorSt_SACC 200;
BA_REL_ "GenSigTimeoutTime" BU_SG_REL_ Gateway SG_ 278 HAD_ErrorSt_HWP 200;
BA_REL_ "GenSigTimeoutTime" BU_SG_REL_ CDS2 SG_ 278 HAD_ErrorSt_HWP 200;
BA_REL_ "GenSigTimeoutTime" BU_SG_REL_ Gateway SG_ 278 HAD_ErrorSt_TJP 200;
BA_REL_ "GenSigTimeoutTime" BU_SG_REL_ CDS2 SG_ 278 HAD_ErrorSt_TJP 200;
BA_REL_ "GenSigTimeoutTime" BU_SG_REL_ Gateway SG_ 278 HAD_LDWSteeringVibrationReq 200;
BA_REL_ "GenSigTimeoutTime" BU_SG_REL_ CDS2 SG_ 278 HAD_LDWSteeringVibrationReq 200;
BA_REL_ "GenSigTimeoutTime" BU_SG_REL_ Gateway SG_ 278 HAD_WorkingSt_DCLC 200;
BA_REL_ "GenSigTimeoutTime" BU_SG_REL_ CDS2 SG_ 278 HAD_WorkingSt_DCLC 200;
BA_REL_ "GenSigTimeoutTime" BU_SG_REL_ Gateway SG_ 278 HAD_WorkingSt_HWP 200;
BA_REL_ "GenSigTimeoutTime" BU_SG_REL_ CDS2 SG_ 278 HAD_WorkingSt_HWP 200;
BA_REL_ "GenSigTimeoutTime" BU_SG_REL_ Gateway SG_ 278 HAD_WorkingSt_TJP 200;
BA_REL_ "GenSigTimeoutTime" BU_SG_REL_ CDS2 SG_ 278 HAD_WorkingSt_TJP 200;
BA_REL_ "GenSigTimeoutTime" BU_SG_REL_ Gateway SG_ 278 HAD_ErrorSt_HAD 200;
BA_REL_ "GenSigTimeoutTime" BU_SG_REL_ CDS2 SG_ 278 HAD_ErrorSt_HAD 200;
BA_REL_ "GenSigTimeoutTime" BU_SG_REL_ Gateway SG_ 278 LiveCounter_HAD_6 200;
BA_REL_ "GenSigTimeoutTime" BU_SG_REL_ CDS2 SG_ 278 LiveCounter_HAD_6 200;
BA_REL_ "GenSigTimeoutTime" BU_SG_REL_ Gateway SG_ 272 Checksum_IFC_1 200;
BA_REL_ "GenSigTimeoutTime" BU_SG_REL_ ADV SG_ 272 Checksum_IFC_1 200;
BA_REL_ "GenSigTimeoutTime" BU_SG_REL_ Gateway SG_ 272 IFC_WorkingSt_AEB_L12 200;
BA_REL_ "GenSigTimeoutTime" BU_SG_REL_ Gateway SG_ 272 IFC_ErrorSt_AEB_L12 200;
BA_REL_ "GenSigTimeoutTime" BU_SG_REL_ ADV SG_ 272 IFC_ErrorSt_AEB_L12 200;
BA_REL_ "GenSigTimeoutTime" BU_SG_REL_ Gateway SG_ 272 IFC_ErrorSt_ACC_L12 200;
BA_REL_ "GenSigTimeoutTime" BU_SG_REL_ Gateway SG_ 272 IFC_WorkingSt_ACC_L12 200;
BA_REL_ "GenSigTimeoutTime" BU_SG_REL_ ADV SG_ 272 IFC_WorkingSt_ACC_L12 200;
BA_REL_ "GenSigTimeoutTime" BU_SG_REL_ Gateway SG_ 272 IFC_ABPReq_L12 200;
BA_REL_ "GenSigTimeoutTime" BU_SG_REL_ Gateway SG_ 272 IFC_AWBReq_L12 200;
BA_REL_ "GenSigTimeoutTime" BU_SG_REL_ Gateway SG_ 272 IFC_AWBlevel_L12 200;
BA_REL_ "GenSigTimeoutTime" BU_SG_REL_ Gateway SG_ 272 CruiseModeFunctionInd 200;
BA_REL_ "GenSigTimeoutTime" BU_SG_REL_ Gateway SG_ 272 IFC_BrakeModeReq_L12 200;
BA_REL_ "GenSigTimeoutTime" BU_SG_REL_ Gateway SG_ 272 IFC_DrivedownReq_L12 200;
BA_REL_ "GenSigTimeoutTime" BU_SG_REL_ Gateway SG_ 272 IFC_SecureRequest_L12 200;
BA_REL_ "GenSigTimeoutTime" BU_SG_REL_ Gateway SG_ 272 IFC_AEBSensitivity_L12 200;
BA_REL_ "GenSigTimeoutTime" BU_SG_REL_ Gateway SG_ 272 IFC_AutoDrivingReq 200;
BA_REL_ "GenSigTimeoutTime" BU_SG_REL_ Gateway SG_ 272 LiveCounter_IFC_1 200;
BA_REL_ "GenSigTimeoutTime" BU_SG_REL_ ADV SG_ 272 LiveCounter_IFC_1 200;
BA_REL_ "GenSigTimeoutTime" BU_SG_REL_ Gateway SG_ 275 Checksum_IFC_6 200;
BA_REL_ "GenSigTimeoutTime" BU_SG_REL_ Gateway SG_ 275 IFC_AutoDrivingReq_L12 200;
BA_REL_ "GenSigTimeoutTime" BU_SG_REL_ Gateway SG_ 275 IFC_SpeedChangeRequest_L12 200;
BA_REL_ "GenSigTimeoutTime" BU_SG_REL_ Gateway SG_ 275 IFC_MaxAccGrad_L12 200;
BA_REL_ "GenSigTimeoutTime" BU_SG_REL_ Gateway SG_ 275 IFC_MinAccGrad_L12 200;
BA_REL_ "GenSigTimeoutTime" BU_SG_REL_ Gateway SG_ 275 IFC_MaxComfBand_L12 200;
BA_REL_ "GenSigTimeoutTime" BU_SG_REL_ Gateway SG_ 275 IFC_MinComfBand_L12 200;
BA_REL_ "GenSigTimeoutTime" BU_SG_REL_ Gateway SG_ 275 IFC_UseMaxComfBand_L12 200;
BA_REL_ "GenSigTimeoutTime" BU_SG_REL_ Gateway SG_ 275 LiveCounter_IFC_6 200;
BA_REL_ "GenSigTimeoutTime" BU_SG_REL_ Gateway SG_ 294 Checksum_FOU_1 200;
BA_REL_ "GenSigTimeoutTime" BU_SG_REL_ CDS1 SG_ 294 Checksum_FOU_1 200;
BA_REL_ "GenSigTimeoutTime" BU_SG_REL_ Gateway SG_ 294 FOU_AutoDrivingReq_L3 200;
BA_REL_ "GenSigTimeoutTime" BU_SG_REL_ CDS1 SG_ 294 FOU_AutoDrivingReq_L3 200;
BA_REL_ "GenSigTimeoutTime" BU_SG_REL_ Gateway SG_ 294 FOU_SpeedChangeRequest_L3 200;
BA_REL_ "GenSigTimeoutTime" BU_SG_REL_ CDS1 SG_ 294 FOU_SpeedChangeRequest_L3 200;
BA_REL_ "GenSigTimeoutTime" BU_SG_REL_ Gateway SG_ 294 FOU_MaxAccGrad_L3 200;
BA_REL_ "GenSigTimeoutTime" BU_SG_REL_ CDS1 SG_ 294 FOU_MaxAccGrad_L3 200;
BA_REL_ "GenSigTimeoutTime" BU_SG_REL_ Gateway SG_ 294 FOU_MinAccGrad_L3 200;
BA_REL_ "GenSigTimeoutTime" BU_SG_REL_ CDS1 SG_ 294 FOU_MinAccGrad_L3 200;
BA_REL_ "GenSigTimeoutTime" BU_SG_REL_ Gateway SG_ 294 FOU_MaxComfBand_L3 200;
BA_REL_ "GenSigTimeoutTime" BU_SG_REL_ CDS1 SG_ 294 FOU_MaxComfBand_L3 200;
BA_REL_ "GenSigTimeoutTime" BU_SG_REL_ Gateway SG_ 294 FOU_MinComfBand_L3 200;
BA_REL_ "GenSigTimeoutTime" BU_SG_REL_ CDS1 SG_ 294 FOU_MinComfBand_L3 200;
BA_REL_ "GenSigTimeoutTime" BU_SG_REL_ Gateway SG_ 294 FOU_UseMaxComfBand_L3 200;
BA_REL_ "GenSigTimeoutTime" BU_SG_REL_ CDS1 SG_ 294 FOU_UseMaxComfBand_L3 200;
BA_REL_ "GenSigTimeoutTime" BU_SG_REL_ Gateway SG_ 294 LiveCounter_FOU_1 200;
BA_REL_ "GenSigTimeoutTime" BU_SG_REL_ CDS1 SG_ 294 LiveCounter_FOU_1 200;
BA_REL_ "GenSigTimeoutTime" BU_SG_REL_ Gateway SG_ 295 Checksum_FOU_2 200;
BA_REL_ "GenSigTimeoutTime" BU_SG_REL_ CDS1 SG_ 295 Checksum_FOU_2 200;
BA_REL_ "GenSigTimeoutTime" BU_SG_REL_ Gateway SG_ 295 FOU_BrakeModeReq_L3 200;
BA_REL_ "GenSigTimeoutTime" BU_SG_REL_ CDS1 SG_ 295 FOU_BrakeModeReq_L3 200;
BA_REL_ "GenSigTimeoutTime" BU_SG_REL_ Gateway SG_ 295 FOU_DrivedownReq_L3 200;
BA_REL_ "GenSigTimeoutTime" BU_SG_REL_ CDS1 SG_ 295 FOU_DrivedownReq_L3 200;
BA_REL_ "GenSigTimeoutTime" BU_SG_REL_ Gateway SG_ 295 FOU_SecureRequest_L3 200;
BA_REL_ "GenSigTimeoutTime" BU_SG_REL_ CDS1 SG_ 295 FOU_SecureRequest_L3 200;
BA_REL_ "GenSigTimeoutTime" BU_SG_REL_ Gateway SG_ 295 FOU_ErrorSt_AutoDriving_L3 200;
BA_REL_ "GenSigTimeoutTime" BU_SG_REL_ CDS1 SG_ 295 FOU_ErrorSt_AutoDriving_L3 200;
BA_REL_ "GenSigTimeoutTime" BU_SG_REL_ Gateway SG_ 295 FOU_WorkingSt_AutoDriving_L3 200;
BA_REL_ "GenSigTimeoutTime" BU_SG_REL_ CDS1 SG_ 295 FOU_WorkingSt_AutoDriving_L3 200;
BA_REL_ "GenSigTimeoutTime" BU_SG_REL_ Gateway SG_ 295 LiveCounter_FOU_2 200;
BA_REL_ "GenSigTimeoutTime" BU_SG_REL_ CDS1 SG_ 295 LiveCounter_FOU_2 200;
BA_REL_ "GenSigTimeoutTime" BU_SG_REL_ Gateway SG_ 274 Checksum_IFC_4 200;
BA_REL_ "GenSigTimeoutTime" BU_SG_REL_ CDS1 SG_ 274 Checksum_IFC_4 200;
BA_REL_ "GenSigTimeoutTime" BU_SG_REL_ ADV SG_ 274 Checksum_IFC_4 200;
BA_REL_ "GenSigTimeoutTime" BU_SG_REL_ Gateway SG_ 274 IFC_TorqueRequest 200;
BA_REL_ "GenSigTimeoutTime" BU_SG_REL_ CDS1 SG_ 274 IFC_TorqueRequest 200;
BA_REL_ "GenSigTimeoutTime" BU_SG_REL_ Gateway SG_ 274 IFC_TorqueRequestSign 200;
BA_REL_ "GenSigTimeoutTime" BU_SG_REL_ CDS1 SG_ 274 IFC_TorqueRequestSign 200;
BA_REL_ "GenSigTimeoutTime" BU_SG_REL_ Gateway SG_ 274 IFC_TorqueReqSt 200;
BA_REL_ "GenSigTimeoutTime" BU_SG_REL_ CDS1 SG_ 274 IFC_TorqueReqSt 200;
BA_REL_ "GenSigTimeoutTime" BU_SG_REL_ Gateway SG_ 274 IFC_Intervention_LKA 200;
BA_REL_ "GenSigTimeoutTime" BU_SG_REL_ CDS1 SG_ 274 IFC_Intervention_LKA 200;
BA_REL_ "GenSigTimeoutTime" BU_SG_REL_ Gateway SG_ 274 IFC_WorkingSt_LKA 200;
BA_REL_ "GenSigTimeoutTime" BU_SG_REL_ CDS1 SG_ 274 IFC_WorkingSt_LKA 200;
BA_REL_ "GenSigTimeoutTime" BU_SG_REL_ ADV SG_ 274 IFC_WorkingSt_LKA 200;
BA_REL_ "GenSigTimeoutTime" BU_SG_REL_ Gateway SG_ 274 IFC_ErrorSt_LKA 200;
BA_REL_ "GenSigTimeoutTime" BU_SG_REL_ CDS1 SG_ 274 IFC_ErrorSt_LKA 200;
BA_REL_ "GenSigTimeoutTime" BU_SG_REL_ Gateway SG_ 274 IFC_TakeOverTip_LCA 200;
BA_REL_ "GenSigTimeoutTime" BU_SG_REL_ CDS1 SG_ 274 IFC_TakeOverTip_LCA 200;
BA_REL_ "GenSigTimeoutTime" BU_SG_REL_ Gateway SG_ 274 IFC_HandsOffTip_LCA 200;
BA_REL_ "GenSigTimeoutTime" BU_SG_REL_ CDS1 SG_ 274 IFC_HandsOffTip_LCA 200;
BA_REL_ "GenSigTimeoutTime" BU_SG_REL_ Gateway SG_ 274 IFC_WorkingSt_LCA 200;
BA_REL_ "GenSigTimeoutTime" BU_SG_REL_ CDS1 SG_ 274 IFC_WorkingSt_LCA 200;
BA_REL_ "GenSigTimeoutTime" BU_SG_REL_ ADV SG_ 274 IFC_WorkingSt_LCA 200;
BA_REL_ "GenSigTimeoutTime" BU_SG_REL_ Gateway SG_ 274 IFC_ErrorSt_LCA 200;
BA_REL_ "GenSigTimeoutTime" BU_SG_REL_ CDS1 SG_ 274 IFC_ErrorSt_LCA 200;
BA_REL_ "GenSigTimeoutTime" BU_SG_REL_ Gateway SG_ 274 IFC_AutoDrivingModeReq 200;
BA_REL_ "GenSigTimeoutTime" BU_SG_REL_ CDS1 SG_ 274 IFC_AutoDrivingModeReq 200;
BA_REL_ "GenSigTimeoutTime" BU_SG_REL_ Gateway SG_ 274 IFC_ErrorSt_SACC 200;
BA_REL_ "GenSigTimeoutTime" BU_SG_REL_ CDS1 SG_ 274 IFC_ErrorSt_SACC 200;
BA_REL_ "GenSigTimeoutTime" BU_SG_REL_ Gateway SG_ 274 FOU_ErrorSt_HWP 200;
BA_REL_ "GenSigTimeoutTime" BU_SG_REL_ CDS1 SG_ 274 FOU_ErrorSt_HWP 200;
BA_REL_ "GenSigTimeoutTime" BU_SG_REL_ Gateway SG_ 274 FOU_ErrorSt_TJP 200;
BA_REL_ "GenSigTimeoutTime" BU_SG_REL_ CDS1 SG_ 274 FOU_ErrorSt_TJP 200;
BA_REL_ "GenSigTimeoutTime" BU_SG_REL_ Gateway SG_ 274 LDWSteeringVibrationReq 200;
BA_REL_ "GenSigTimeoutTime" BU_SG_REL_ CDS1 SG_ 274 LDWSteeringVibrationReq 200;
BA_REL_ "GenSigTimeoutTime" BU_SG_REL_ Gateway SG_ 274 IFC_WorkingSt_SACC 200;
BA_REL_ "GenSigTimeoutTime" BU_SG_REL_ CDS1 SG_ 274 IFC_WorkingSt_SACC 200;
BA_REL_ "GenSigTimeoutTime" BU_SG_REL_ ADV SG_ 274 IFC_WorkingSt_SACC 200;
BA_REL_ "GenSigTimeoutTime" BU_SG_REL_ Gateway SG_ 274 FOU_WorkingSt_HWP 200;
BA_REL_ "GenSigTimeoutTime" BU_SG_REL_ CDS1 SG_ 274 FOU_WorkingSt_HWP 200;
BA_REL_ "GenSigTimeoutTime" BU_SG_REL_ Gateway SG_ 274 FOU_WorkingSt_TJP 200;
BA_REL_ "GenSigTimeoutTime" BU_SG_REL_ CDS1 SG_ 274 FOU_WorkingSt_TJP 200;
BA_REL_ "GenSigTimeoutTime" BU_SG_REL_ Gateway SG_ 274 IFC_ErrorSt_FOU 200;
BA_REL_ "GenSigTimeoutTime" BU_SG_REL_ Gateway SG_ 274 LiveCounter_IFC_4 200;
BA_REL_ "GenSigTimeoutTime" BU_SG_REL_ CDS1 SG_ 274 LiveCounter_IFC_4 200;
BA_REL_ "GenSigTimeoutTime" BU_SG_REL_ ADV SG_ 274 LiveCounter_IFC_4 200;
BA_REL_ "GenSigTimeoutTime" BU_SG_REL_ Gateway SG_ 279 Checksum_IFC_5 200;
BA_REL_ "GenSigTimeoutTime" BU_SG_REL_ CDS1 SG_ 279 Checksum_IFC_5 200;
BA_REL_ "GenSigTimeoutTime" BU_SG_REL_ Gateway SG_ 279 IFC_SteeringWheelAngleRequest 200;
BA_REL_ "GenSigTimeoutTime" BU_SG_REL_ CDS1 SG_ 279 IFC_SteeringWheelAngleRequest 200;
BA_REL_ "GenSigTimeoutTime" BU_SG_REL_ Gateway SG_ 279 IFC_SteeringWheelAngleSignReques 200;
BA_REL_ "GenSigTimeoutTime" BU_SG_REL_ CDS1 SG_ 279 IFC_SteeringWheelAngleSignReques 200;
BA_REL_ "GenSigTimeoutTime" BU_SG_REL_ Gateway SG_ 279 IFC_SteeringWheelAngleControlReq 200;
BA_REL_ "GenSigTimeoutTime" BU_SG_REL_ CDS1 SG_ 279 IFC_SteeringWheelAngleControlReq 200;
BA_REL_ "GenSigTimeoutTime" BU_SG_REL_ Gateway SG_ 279 LiveCounter_IFC_5 200;
BA_REL_ "GenSigTimeoutTime" BU_SG_REL_ CDS1 SG_ 279 LiveCounter_IFC_5 200;
BA_REL_ "GenSigTimeoutTime" BU_SG_REL_ Gateway SG_ 607 HAD_CruiseSpeedSetting_ACC 1000;
BA_REL_ "GenSigTimeoutTime" BU_SG_REL_ CDS2 SG_ 607 HAD_CruiseSpeedSetting_ACC 1000;
BA_REL_ "GenSigTimeoutTime" BU_SG_REL_ Gateway SG_ 607 HAD_TimeGapSetting 1000;
BA_REL_ "GenSigTimeoutTime" BU_SG_REL_ CDS2 SG_ 607 HAD_TimeGapSetting 1000;
BA_REL_ "GenSigTimeoutTime" BU_SG_REL_ Gateway SG_ 607 HAD_ObjectDetection 1000;
BA_REL_ "GenSigTimeoutTime" BU_SG_REL_ CDS2 SG_ 607 HAD_ObjectDetection 1000;
BA_REL_ "GenSigTimeoutTime" BU_SG_REL_ Gateway SG_ 607 HAD_SysTextinfo 1000;
BA_REL_ "GenSigTimeoutTime" BU_SG_REL_ CDS2 SG_ 607 HAD_SysTextinfo 1000;
BA_REL_ "GenSigTimeoutTime" BU_SG_REL_ Gateway SG_ 607 HAD_LDWModeInd 1000;
BA_REL_ "GenSigTimeoutTime" BU_SG_REL_ CDS2 SG_ 607 HAD_LDWModeInd 1000;
BA_REL_ "GenSigTimeoutTime" BU_SG_REL_ Gateway SG_ 607 HAD_TakeOverReq 1000;
BA_REL_ "GenSigTimeoutTime" BU_SG_REL_ CDS2 SG_ 607 HAD_TakeOverReq 1000;
BA_REL_ "GenSigTimeoutTime" BU_SG_REL_ Gateway SG_ 607 HAD_AutoLightModeReq 1000;
BA_REL_ "GenSigTimeoutTime" BU_SG_REL_ CDS2 SG_ 607 HAD_AutoLightModeReq 1000;
BA_REL_ "GenSigTimeoutTime" BU_SG_REL_ Gateway SG_ 607 HAD_HazardWarningLampRequest 1000;
BA_REL_ "GenSigTimeoutTime" BU_SG_REL_ CDS2 SG_ 607 HAD_HazardWarningLampRequest 1000;
BA_REL_ "GenSigTimeoutTime" BU_SG_REL_ Gateway SG_ 607 HAD_WorkingSt_LDW 1000;
BA_REL_ "GenSigTimeoutTime" BU_SG_REL_ CDS2 SG_ 607 HAD_WorkingSt_LDW 1000;
BA_REL_ "GenSigTimeoutTime" BU_SG_REL_ Gateway SG_ 607 HAD_WarningCmd_LDW 1000;
BA_REL_ "GenSigTimeoutTime" BU_SG_REL_ CDS2 SG_ 607 HAD_WarningCmd_LDW 1000;
BA_REL_ "GenSigTimeoutTime" BU_SG_REL_ Gateway SG_ 607 HAD_LDWLaneDetectSt 1000;
BA_REL_ "GenSigTimeoutTime" BU_SG_REL_ CDS2 SG_ 607 HAD_LDWLaneDetectSt 1000;
BA_REL_ "GenSigTimeoutTime" BU_SG_REL_ Gateway SG_ 607 HAD_SensitivityInd_LDW 1000;
BA_REL_ "GenSigTimeoutTime" BU_SG_REL_ CDS2 SG_ 607 HAD_SensitivityInd_LDW 1000;
BA_REL_ "GenSigTimeoutTime" BU_SG_REL_ Gateway SG_ 607 HAD_ErrorSt_LDW 1000;
BA_REL_ "GenSigTimeoutTime" BU_SG_REL_ CDS2 SG_ 607 HAD_ErrorSt_LDW 1000;
BA_REL_ "GenSigTimeoutTime" BU_SG_REL_ ADV SG_ 607 HAD_ErrorSt_LDW 1000;
BA_REL_ "GenSigTimeoutTime" BU_SG_REL_ Gateway SG_ 607 HAD_WorkingSt_FCW 1000;
BA_REL_ "GenSigTimeoutTime" BU_SG_REL_ CDS2 SG_ 607 HAD_WorkingSt_FCW 1000;
BA_REL_ "GenSigTimeoutTime" BU_SG_REL_ Gateway SG_ 607 HAD_WarningCmd_FCW 1000;
BA_REL_ "GenSigTimeoutTime" BU_SG_REL_ CDS2 SG_ 607 HAD_WarningCmd_FCW 1000;
BA_REL_ "GenSigTimeoutTime" BU_SG_REL_ Gateway SG_ 607 HAD_ErrorSt_FCW 1000;
BA_REL_ "GenSigTimeoutTime" BU_SG_REL_ CDS2 SG_ 607 HAD_ErrorSt_FCW 1000;
BA_REL_ "GenSigTimeoutTime" BU_SG_REL_ ADV SG_ 607 HAD_ErrorSt_FCW 1000;
BA_REL_ "GenSigTimeoutTime" BU_SG_REL_ Gateway SG_ 607 HAD_SensitivityInd_FCW 1000;
BA_REL_ "GenSigTimeoutTime" BU_SG_REL_ CDS2 SG_ 607 HAD_SensitivityInd_FCW 1000;
BA_REL_ "GenSigTimeoutTime" BU_SG_REL_ Gateway SG_ 607 HAD_FCWModeInd 1000;
BA_REL_ "GenSigTimeoutTime" BU_SG_REL_ CDS2 SG_ 607 HAD_FCWModeInd 1000;
BA_REL_ "GenSigTimeoutTime" BU_SG_REL_ Gateway SG_ 607 HAD_WiperAutoLeverReq 1000;
BA_REL_ "GenSigTimeoutTime" BU_SG_REL_ CDS2 SG_ 607 HAD_WiperAutoLeverReq 1000;
BA_REL_ "GenSigTimeoutTime" BU_SG_REL_ Gateway SG_ 607 HAD_SACCNotSatisfiedCondition 1000;
BA_REL_ "GenSigTimeoutTime" BU_SG_REL_ CDS2 SG_ 607 HAD_SACCNotSatisfiedCondition 1000;
BA_REL_ "GenSigTimeoutTime" BU_SG_REL_ Gateway SG_ 607 HAD_LDW_SpeechControlFeedback 1000;
BA_REL_ "GenSigTimeoutTime" BU_SG_REL_ CDS2 SG_ 607 HAD_LDW_SpeechControlFeedback 1000;
BA_REL_ "GenSigTimeoutTime" BU_SG_REL_ Gateway SG_ 607 HAD_VASFunctionInd 1000;
BA_REL_ "GenSigTimeoutTime" BU_SG_REL_ CDS2 SG_ 607 HAD_VASFunctionInd 1000;
BA_REL_ "GenSigTimeoutTime" BU_SG_REL_ Gateway SG_ 607 HAD_IFCSystemError 1000;
BA_REL_ "GenSigTimeoutTime" BU_SG_REL_ CDS2 SG_ 607 HAD_IFCSystemError 1000;
BA_REL_ "GenSigTimeoutTime" BU_SG_REL_ Gateway SG_ 607 HAD_IFCCalibrationStatus 1000;
BA_REL_ "GenSigTimeoutTime" BU_SG_REL_ CDS2 SG_ 607 HAD_IFCCalibrationStatus 1000;
BA_REL_ "GenSigTimeoutTime" BU_SG_REL_ Gateway SG_ 607 HAD_WarningCmd_VAS 1000;
BA_REL_ "GenSigTimeoutTime" BU_SG_REL_ CDS2 SG_ 607 HAD_WarningCmd_VAS 1000;
BA_REL_ "GenSigTimeoutTime" BU_SG_REL_ Gateway SG_ 607 HAD_LeftTurningLampRequest 1000;
BA_REL_ "GenSigTimeoutTime" BU_SG_REL_ CDS2 SG_ 607 HAD_LeftTurningLampRequest 1000;
BA_REL_ "GenSigTimeoutTime" BU_SG_REL_ Gateway SG_ 607 HAD_RightTurningLampRequest 1000;
BA_REL_ "GenSigTimeoutTime" BU_SG_REL_ CDS2 SG_ 607 HAD_RightTurningLampRequest 1000;
BA_REL_ "GenSigTimeoutTime" BU_SG_REL_ Gateway SG_ 607 HAD_ValetModeStatus 1000;
BA_REL_ "GenSigTimeoutTime" BU_SG_REL_ Gateway SG_ 608 CruiseSpeedSetting_ACC 1000;
BA_REL_ "GenSigTimeoutTime" BU_SG_REL_ Gateway SG_ 608 TimeGapSetting 1000;
BA_REL_ "GenSigTimeoutTime" BU_SG_REL_ Gateway SG_ 608 ObjectDetection 1000;
BA_REL_ "GenSigTimeoutTime" BU_SG_REL_ Gateway SG_ 608 SysTextinfo 1000;
BA_REL_ "GenSigTimeoutTime" BU_SG_REL_ Gateway SG_ 608 LDWModeInd 1000;
BA_REL_ "GenSigTimeoutTime" BU_SG_REL_ Gateway SG_ 608 TakeOverReq 1000;
BA_REL_ "GenSigTimeoutTime" BU_SG_REL_ Gateway SG_ 608 AutoLightModeReq 1000;
BA_REL_ "GenSigTimeoutTime" BU_SG_REL_ Gateway SG_ 608 HazardWarningLampRequest 1000;
BA_REL_ "GenSigTimeoutTime" BU_SG_REL_ Gateway SG_ 608 WorkingSt_LDW 1000;
BA_REL_ "GenSigTimeoutTime" BU_SG_REL_ Gateway SG_ 608 WarningCmd_LDW 1000;
BA_REL_ "GenSigTimeoutTime" BU_SG_REL_ Gateway SG_ 608 LDWLaneDetectSt 1000;
BA_REL_ "GenSigTimeoutTime" BU_SG_REL_ Gateway SG_ 608 SensitivityInd_LDW 1000;
BA_REL_ "GenSigTimeoutTime" BU_SG_REL_ Gateway SG_ 608 ErrorSt_LDW 1000;
BA_REL_ "GenSigTimeoutTime" BU_SG_REL_ ADV SG_ 608 ErrorSt_LDW 1000;
BA_REL_ "GenSigTimeoutTime" BU_SG_REL_ Gateway SG_ 608 WorkingSt_FCW 1000;
BA_REL_ "GenSigTimeoutTime" BU_SG_REL_ Gateway SG_ 608 WarningCmd_FCW 1000;
BA_REL_ "GenSigTimeoutTime" BU_SG_REL_ Gateway SG_ 608 ErrorSt_FCW 1000;
BA_REL_ "GenSigTimeoutTime" BU_SG_REL_ ADV SG_ 608 ErrorSt_FCW 1000;
BA_REL_ "GenSigTimeoutTime" BU_SG_REL_ Gateway SG_ 608 SensitivityInd_FCW 1000;
BA_REL_ "GenSigTimeoutTime" BU_SG_REL_ Gateway SG_ 608 FCWModeInd 1000;
BA_REL_ "GenSigTimeoutTime" BU_SG_REL_ Gateway SG_ 608 WiperAutoLeverReq 1000;
BA_REL_ "GenSigTimeoutTime" BU_SG_REL_ Gateway SG_ 608 SACCNotSatisfiedCondition 1000;
BA_REL_ "GenSigTimeoutTime" BU_SG_REL_ Gateway SG_ 608 LDW_SpeechControlFeedback 1000;
BA_REL_ "GenSigTimeoutTime" BU_SG_REL_ Gateway SG_ 608 VASFunctionInd 1000;
BA_REL_ "GenSigTimeoutTime" BU_SG_REL_ Gateway SG_ 608 IFCSystemError 1000;
BA_REL_ "GenSigTimeoutTime" BU_SG_REL_ Gateway SG_ 608 IFCCalibrationStatus 1000;
BA_REL_ "GenSigTimeoutTime" BU_SG_REL_ Gateway SG_ 608 WarningCmd_VAS 1000;
BA_REL_ "GenSigTimeoutTime" BU_SG_REL_ Gateway SG_ 608 IFC_LeftTurningLampRequest 1000;
BA_REL_ "GenSigTimeoutTime" BU_SG_REL_ Gateway SG_ 608 IFC_RightTurningLampRequest 1000;
BA_REL_ "GenSigTimeoutTime" BU_SG_REL_ Gateway SG_ 609 HAD_LimitedVehicleSpeed_TSR 1000;
BA_REL_ "GenSigTimeoutTime" BU_SG_REL_ Gateway SG_ 609 HAD_WorkingSt_TSR 1000;
BA_REL_ "GenSigTimeoutTime" BU_SG_REL_ Gateway SG_ 609 HAD_WarningCmd_TSR 1000;
BA_REL_ "GenSigTimeoutTime" BU_SG_REL_ Gateway SG_ 609 HAD_ErrorSt_TSR 1000;
BA_REL_ "GenSigTimeoutTime" BU_SG_REL_ Gateway SG_ 609 HAD_VAS_SpeechControlFeedback 1000;
BA_REL_ "GenSigTimeoutTime" BU_SG_REL_ Gateway SG_ 609 HAD_TSR_SpeechControlFeedback 1000;
BA_REL_ "GenSigTimeoutTime" BU_SG_REL_ Gateway SG_ 610 LimitedVehicleSpeed_TSR 1000;
BA_REL_ "GenSigTimeoutTime" BU_SG_REL_ Gateway SG_ 610 WorkingSt_TSR 1000;
BA_REL_ "GenSigTimeoutTime" BU_SG_REL_ Gateway SG_ 610 WarningCmd_TSR 1000;
BA_REL_ "GenSigTimeoutTime" BU_SG_REL_ Gateway SG_ 610 ErrorSt_TSR 1000;
BA_REL_ "GenSigTimeoutTime" BU_SG_REL_ Gateway SG_ 610 WorkingSt_DSM 1000;
BA_REL_ "GenSigTimeoutTime" BU_SG_REL_ Gateway SG_ 610 WarningCmd_DSM 1000;
BA_REL_ "GenSigTimeoutTime" BU_SG_REL_ Gateway SG_ 610 ErrorSt_DSM 1000;
BA_REL_ "GenSigTimeoutTime" BU_SG_REL_ Gateway SG_ 610 DSMFunctionInd 1000;
BA_REL_ "GenSigTimeoutTime" BU_SG_REL_ Gateway SG_ 610 VAS_SpeechControlFeedback 1000;
BA_REL_ "GenSigTimeoutTime" BU_SG_REL_ Gateway SG_ 610 TSR_SpeechControlFeedback 1000;
BA_REL_ "GenSigTimeoutTime" BU_SG_REL_ Gateway SG_ 610 DSM_SpeechControlFeedback 1000;
BA_REL_ "GenSigTimeoutTime" BU_SG_REL_ Gateway SG_ 592 Checksum_ADV_1 1000;
BA_REL_ "GenSigTimeoutTime" BU_SG_REL_ CDS2 SG_ 592 Checksum_ADV_1 1000;
BA_REL_ "GenSigTimeoutTime" BU_SG_REL_ AVP SG_ 592 Checksum_ADV_1 1000;
BA_REL_ "GenSigTimeoutTime" BU_SG_REL_ AVM SG_ 592 Checksum_ADV_1 1000;
BA_REL_ "GenSigTimeoutTime" BU_SG_REL_ PDC SG_ 592 Checksum_ADV_1 1000;
BA_REL_ "GenSigTimeoutTime" BU_SG_REL_ Gateway SG_ 592 ADV_ParkType 1000;
BA_REL_ "GenSigTimeoutTime" BU_SG_REL_ AVP SG_ 592 ADV_ParkType 1000;
BA_REL_ "GenSigTimeoutTime" BU_SG_REL_ AVM SG_ 592 ADV_ParkType 1000;
BA_REL_ "GenSigTimeoutTime" BU_SG_REL_ Gateway SG_ 592 ADV_ParkInSlotSearchMode 1000;
BA_REL_ "GenSigTimeoutTime" BU_SG_REL_ AVP SG_ 592 ADV_ParkInSlotSearchMode 1000;
BA_REL_ "GenSigTimeoutTime" BU_SG_REL_ AVM SG_ 592 ADV_ParkInSlotSearchMode 1000;
BA_REL_ "GenSigTimeoutTime" BU_SG_REL_ Gateway SG_ 592 ADV_ParkStatus 1000;
BA_REL_ "GenSigTimeoutTime" BU_SG_REL_ CDS2 SG_ 592 ADV_ParkStatus 1000;
BA_REL_ "GenSigTimeoutTime" BU_SG_REL_ AVP SG_ 592 ADV_ParkStatus 1000;
BA_REL_ "GenSigTimeoutTime" BU_SG_REL_ AVM SG_ 592 ADV_ParkStatus 1000;
BA_REL_ "GenSigTimeoutTime" BU_SG_REL_ PDC SG_ 592 ADV_ParkStatus 1000;
BA_REL_ "GenSigTimeoutTime" BU_SG_REL_ Gateway SG_ 592 ADV_SystemError 1000;
BA_REL_ "GenSigTimeoutTime" BU_SG_REL_ Gateway SG_ 592 ADV_ParkInAvaialble 1000;
BA_REL_ "GenSigTimeoutTime" BU_SG_REL_ Gateway SG_ 592 ADV_ParkOutAvaialble 1000;
BA_REL_ "GenSigTimeoutTime" BU_SG_REL_ Gateway SG_ 592 ADV_ParkInReady 1000;
BA_REL_ "GenSigTimeoutTime" BU_SG_REL_ Gateway SG_ 592 ADV_ParkOutReady 1000;
BA_REL_ "GenSigTimeoutTime" BU_SG_REL_ Gateway SG_ 592 ADV_ParkOutDirection 1000;
BA_REL_ "GenSigTimeoutTime" BU_SG_REL_ AVP SG_ 592 ADV_ParkOutDirection 1000;
BA_REL_ "GenSigTimeoutTime" BU_SG_REL_ AVM SG_ 592 ADV_ParkOutDirection 1000;
BA_REL_ "GenSigTimeoutTime" BU_SG_REL_ Gateway SG_ 592 ADV_VehicleModeRequest 1000;
BA_REL_ "GenSigTimeoutTime" BU_SG_REL_ Gateway SG_ 592 ADV_BrakeLightCtrlCmd 1000;
BA_REL_ "GenSigTimeoutTime" BU_SG_REL_ Gateway SG_ 592 ADV_HazardWarningLampRequest 1000;
BA_REL_ "GenSigTimeoutTime" BU_SG_REL_ Gateway SG_ 592 ADV_DoorRequest 1000;
BA_REL_ "GenSigTimeoutTime" BU_SG_REL_ Gateway SG_ 592 ADV_LeftTurningLampRequest 1000;
BA_REL_ "GenSigTimeoutTime" BU_SG_REL_ Gateway SG_ 592 ADV_RightTurningLampRequest 1000;
BA_REL_ "GenSigTimeoutTime" BU_SG_REL_ Gateway SG_ 592 ADV_EngineAndEVStopRequest 1000;
BA_REL_ "GenSigTimeoutTime" BU_SG_REL_ Gateway SG_ 592 ADV_FunctionAbnormalTip 1000;
BA_REL_ "GenSigTimeoutTime" BU_SG_REL_ AVP SG_ 592 ADV_FunctionAbnormalTip 1000;
BA_REL_ "GenSigTimeoutTime" BU_SG_REL_ AVM SG_ 592 ADV_FunctionAbnormalTip 1000;
BA_REL_ "GenSigTimeoutTime" BU_SG_REL_ Gateway SG_ 592 ADV_ParkInEnabled 1000;
BA_REL_ "GenSigTimeoutTime" BU_SG_REL_ Gateway SG_ 592 ADV_ParkOutEnabled 1000;
BA_REL_ "GenSigTimeoutTime" BU_SG_REL_ Gateway SG_ 592 ADV_TimeoutCounter 1000;
BA_REL_ "GenSigTimeoutTime" BU_SG_REL_ Gateway SG_ 592 ADV_ParkingStep 1000;
BA_REL_ "GenSigTimeoutTime" BU_SG_REL_ Gateway SG_ 592 ADV_RearViewMirrorFoldRequest 1000;
BA_REL_ "GenSigTimeoutTime" BU_SG_REL_ Gateway SG_ 592 ADV_ParkingAEBFunctionInd 1000;
BA_REL_ "GenSigTimeoutTime" BU_SG_REL_ PDC SG_ 592 ADV_ParkingAEBFunctionInd 1000;
BA_REL_ "GenSigTimeoutTime" BU_SG_REL_ Gateway SG_ 592 ADV_BacktrackFunctionInd 1000;
BA_REL_ "GenSigTimeoutTime" BU_SG_REL_ AVP SG_ 592 ADV_BacktrackFunctionInd 1000;
BA_REL_ "GenSigTimeoutTime" BU_SG_REL_ Gateway SG_ 592 LiveCounter_ADV_1 1000;
BA_REL_ "GenSigTimeoutTime" BU_SG_REL_ CDS2 SG_ 592 LiveCounter_ADV_1 1000;
BA_REL_ "GenSigTimeoutTime" BU_SG_REL_ AVP SG_ 592 LiveCounter_ADV_1 1000;
BA_REL_ "GenSigTimeoutTime" BU_SG_REL_ AVM SG_ 592 LiveCounter_ADV_1 1000;
BA_REL_ "GenSigTimeoutTime" BU_SG_REL_ PDC SG_ 592 LiveCounter_ADV_1 1000;
BA_REL_ "GenSigTimeoutTime" BU_SG_REL_ Gateway SG_ 593 Checksum_ADV_4 1000;
BA_REL_ "GenSigTimeoutTime" BU_SG_REL_ AVP SG_ 593 Checksum_ADV_4 1000;
BA_REL_ "GenSigTimeoutTime" BU_SG_REL_ AVM SG_ 593 Checksum_ADV_4 1000;
BA_REL_ "GenSigTimeoutTime" BU_SG_REL_ Gateway SG_ 593 ADV_BacktrackAbnormalTip 1000;
BA_REL_ "GenSigTimeoutTime" BU_SG_REL_ PDC SG_ 593 ADV_LeftSlotSearchType 1000;
BA_REL_ "GenSigTimeoutTime" BU_SG_REL_ PDC SG_ 593 ADV_RightSlotSearchType 1000;
BA_REL_ "GenSigTimeoutTime" BU_SG_REL_ PDC SG_ 593 ADV_PDCSchedule 1000;
BA_REL_ "GenSigTimeoutTime" BU_SG_REL_ Gateway SG_ 593 ADV_APAFuncntion_SpeechControlFe 1000;
BA_REL_ "GenSigTimeoutTime" BU_SG_REL_ Gateway SG_ 593 ADV_ParkInMode_SpeechControlFeed 1000;
BA_REL_ "GenSigTimeoutTime" BU_SG_REL_ Gateway SG_ 593 ADV_ParkInType_SpeechControlFeed 1000;
BA_REL_ "GenSigTimeoutTime" BU_SG_REL_ Gateway SG_ 593 ADV_ParkOutFunc_SpeechControlFee 1000;
BA_REL_ "GenSigTimeoutTime" BU_SG_REL_ Gateway SG_ 593 ADV_ParkOutType_SpeechControlFee 1000;
BA_REL_ "GenSigTimeoutTime" BU_SG_REL_ Gateway SG_ 593 ADV_SearchTimeoutCounter 1000;
BA_REL_ "GenSigTimeoutTime" BU_SG_REL_ AVP SG_ 593 ADV_SearchTimeoutCounter 1000;
BA_REL_ "GenSigTimeoutTime" BU_SG_REL_ AVM SG_ 593 ADV_SearchTimeoutCounter 1000;
BA_REL_ "GenSigTimeoutTime" BU_SG_REL_ Gateway SG_ 593 ADV_PauseTimeoutCounter 1000;
BA_REL_ "GenSigTimeoutTime" BU_SG_REL_ Gateway SG_ 593 ADV_PauseButtonDisplay 1000;
BA_REL_ "GenSigTimeoutTime" BU_SG_REL_ Gateway SG_ 593 LiveCounter_ADV_4 1000;
BA_REL_ "GenSigTimeoutTime" BU_SG_REL_ AVP SG_ 593 LiveCounter_ADV_4 1000;
BA_REL_ "GenSigTimeoutTime" BU_SG_REL_ AVM SG_ 593 LiveCounter_ADV_4 1000;
BA_REL_ "GenSigTimeoutTime" BU_SG_REL_ Gateway SG_ 613 Checksum_HAD_5 1000;
BA_REL_ "GenSigTimeoutTime" BU_SG_REL_ AVP SG_ 613 Checksum_HAD_5 1000;
BA_REL_ "GenSigTimeoutTime" BU_SG_REL_ DSM SG_ 613 Checksum_HAD_5 1000;
BA_REL_ "GenSigTimeoutTime" BU_SG_REL_ Gateway SG_ 613 HAD_SystemError_AVP 1000;
BA_REL_ "GenSigTimeoutTime" BU_SG_REL_ DSM SG_ 613 HAD_SystemError_AVP 1000;
BA_REL_ "GenSigTimeoutTime" BU_SG_REL_ Gateway SG_ 613 HAD_ParkingLotAvalableTip_AVP 1000;
BA_REL_ "GenSigTimeoutTime" BU_SG_REL_ Gateway SG_ 613 HAD_AIUnavailableTip 1000;
BA_REL_ "GenSigTimeoutTime" BU_SG_REL_ Gateway SG_ 613 HAD_ValetModeTip_AVP 1000;
BA_REL_ "GenSigTimeoutTime" BU_SG_REL_ Gateway SG_ 613 HAD_ChangeLaneManualsuccess_Tip 1000;
BA_REL_ "GenSigTimeoutTime" BU_SG_REL_ Gateway SG_ 613 HAD_SetdestinationFuncSt 1000;
BA_REL_ "GenSigTimeoutTime" BU_SG_REL_ Gateway SG_ 613 HAD_SetdestinationTip 1000;
BA_REL_ "GenSigTimeoutTime" BU_SG_REL_ Gateway SG_ 613 HAD_WorkingSt_HWP_Display 1000;
BA_REL_ "GenSigTimeoutTime" BU_SG_REL_ AVP SG_ 613 HAD_WorkingSt_HWP_Display 1000;
BA_REL_ "GenSigTimeoutTime" BU_SG_REL_ DSM SG_ 613 HAD_WorkingSt_HWP_Display 1000;
BA_REL_ "GenSigTimeoutTime" BU_SG_REL_ Gateway SG_ 613 HAD_TakeoverReq_L3 1000;
BA_REL_ "GenSigTimeoutTime" BU_SG_REL_ DSM SG_ 613 HAD_TakeoverReq_L3 1000;
BA_REL_ "GenSigTimeoutTime" BU_SG_REL_ Gateway SG_ 613 HAD_ChangeLaneManualFuncSt 1000;
BA_REL_ "GenSigTimeoutTime" BU_SG_REL_ Gateway SG_ 613 HAD_WorkingSt_TJP_Display 1000;
BA_REL_ "GenSigTimeoutTime" BU_SG_REL_ AVP SG_ 613 HAD_WorkingSt_TJP_Display 1000;
BA_REL_ "GenSigTimeoutTime" BU_SG_REL_ DSM SG_ 613 HAD_WorkingSt_TJP_Display 1000;
BA_REL_ "GenSigTimeoutTime" BU_SG_REL_ Gateway SG_ 613 HAD_LateralTakeOverReq_L3 1000;
BA_REL_ "GenSigTimeoutTime" BU_SG_REL_ DSM SG_ 613 HAD_LateralTakeOverReq_L3 1000;
BA_REL_ "GenSigTimeoutTime" BU_SG_REL_ Gateway SG_ 613 HAD_AutoDrivingStyle 1000;
BA_REL_ "GenSigTimeoutTime" BU_SG_REL_ Gateway SG_ 613 HAD_ChangeLaneAutoFuncSt 1000;
BA_REL_ "GenSigTimeoutTime" BU_SG_REL_ Gateway SG_ 613 HAD_TOR_Tips 1000;
BA_REL_ "GenSigTimeoutTime" BU_SG_REL_ Gateway SG_ 613 HAD_AutoDrivingNotSatisfiedCondi 1000;
BA_REL_ "GenSigTimeoutTime" BU_SG_REL_ Gateway SG_ 613 HAD_DistractionWarning 1000;
BA_REL_ "GenSigTimeoutTime" BU_SG_REL_ Gateway SG_ 613 HAD_AttentionSt 1000;
BA_REL_ "GenSigTimeoutTime" BU_SG_REL_ Gateway SG_ 613 HAD_TakeOverWarning_L3 1000;
BA_REL_ "GenSigTimeoutTime" BU_SG_REL_ Gateway SG_ 613 HAD_TakeOverSuccessTip_L3 1000;
BA_REL_ "GenSigTimeoutTime" BU_SG_REL_ Gateway SG_ 613 HAD_ChangeLaneManual_Feedback 1000;
BA_REL_ "GenSigTimeoutTime" BU_SG_REL_ Gateway SG_ 613 HAD_ErrorSt_HWPTJP 1000;
BA_REL_ "GenSigTimeoutTime" BU_SG_REL_ DSM SG_ 613 HAD_ErrorSt_HWPTJP 1000;
BA_REL_ "GenSigTimeoutTime" BU_SG_REL_ Gateway SG_ 613 HAD_Countdown_Takeover 1000;
BA_REL_ "GenSigTimeoutTime" BU_SG_REL_ Gateway SG_ 613 HAD_Destinationtip_St 1000;
BA_REL_ "GenSigTimeoutTime" BU_SG_REL_ Gateway SG_ 613 HAD_Countdown_SafeStop 1000;
BA_REL_ "GenSigTimeoutTime" BU_SG_REL_ Gateway SG_ 613 HAD_SACCActiveForbidden 1000;
BA_REL_ "GenSigTimeoutTime" BU_SG_REL_ Gateway SG_ 613 LiveCounter_HAD_5 1000;
BA_REL_ "GenSigTimeoutTime" BU_SG_REL_ AVP SG_ 613 LiveCounter_HAD_5 1000;
BA_REL_ "GenSigTimeoutTime" BU_SG_REL_ DSM SG_ 613 LiveCounter_HAD_5 1000;
BA_REL_ "GenSigTimeoutTime" BU_SG_REL_ Gateway SG_ 595 Checksum_ADV_5 1000;
BA_REL_ "GenSigTimeoutTime" BU_SG_REL_ Gateway SG_ 595 ADV_CIDLocationReq 1000;
BA_REL_ "GenSigTimeoutTime" BU_SG_REL_ Gateway SG_ 595 ADV_PositionLightReq 1000;
BA_REL_ "GenSigTimeoutTime" BU_SG_REL_ Gateway SG_ 595 ADV_FogLightReq_Front 1000;
BA_REL_ "GenSigTimeoutTime" BU_SG_REL_ Gateway SG_ 595 ADV_FogLightReq_Rear 1000;
BA_REL_ "GenSigTimeoutTime" BU_SG_REL_ Gateway SG_ 595 ADV_AVPHazardWarningFunctionInd 1000;
BA_REL_ "GenSigTimeoutTime" BU_SG_REL_ Gateway SG_ 595 ADV_HPAHazardWarningFunctionInd 1000;
BA_REL_ "GenSigTimeoutTime" BU_SG_REL_ Gateway SG_ 595 ADV_AVPTypeIndication 1000;
BA_REL_ "GenSigTimeoutTime" BU_SG_REL_ Gateway SG_ 595 ADV_AVPSearchingTypeInd 1000;
BA_REL_ "GenSigTimeoutTime" BU_SG_REL_ Gateway SG_ 595 ADV_HPATypeIndication 1000;
BA_REL_ "GenSigTimeoutTime" BU_SG_REL_ Gateway SG_ 595 ADV_HPASearchingTypeInd 1000;
BA_REL_ "GenSigTimeoutTime" BU_SG_REL_ Gateway SG_ 595 ADV_AVPParkingLotPushFunctionInd 1000;
BA_REL_ "GenSigTimeoutTime" BU_SG_REL_ Gateway SG_ 595 ADV_HPAParkingLotPushFunctionInd 1000;
BA_REL_ "GenSigTimeoutTime" BU_SG_REL_ Gateway SG_ 595 ADV_AVPNaviAvaialble 1000;
BA_REL_ "GenSigTimeoutTime" BU_SG_REL_ Gateway SG_ 595 ADV_AVPParkInAvaialble 1000;
BA_REL_ "GenSigTimeoutTime" BU_SG_REL_ PDC SG_ 595 ADV_AVPParkInAvaialble 1000;
BA_REL_ "GenSigTimeoutTime" BU_SG_REL_ Gateway SG_ 595 ADV_AVPParkOutAvaialble 1000;
BA_REL_ "GenSigTimeoutTime" BU_SG_REL_ PDC SG_ 595 ADV_AVPParkOutAvaialble 1000;
BA_REL_ "GenSigTimeoutTime" BU_SG_REL_ Gateway SG_ 595 ADV_AVPParkInReady 1000;
BA_REL_ "GenSigTimeoutTime" BU_SG_REL_ Gateway SG_ 595 ADV_AVPParkOutReady 1000;
BA_REL_ "GenSigTimeoutTime" BU_SG_REL_ Gateway SG_ 595 ADV_HPANaviAvaialble 1000;
BA_REL_ "GenSigTimeoutTime" BU_SG_REL_ Gateway SG_ 595 ADV_HPAParkInAvaialble 1000;
BA_REL_ "GenSigTimeoutTime" BU_SG_REL_ PDC SG_ 595 ADV_HPAParkInAvaialble 1000;
BA_REL_ "GenSigTimeoutTime" BU_SG_REL_ Gateway SG_ 595 ADV_HPAParkOutAvaialble 1000;
BA_REL_ "GenSigTimeoutTime" BU_SG_REL_ PDC SG_ 595 ADV_HPAParkOutAvaialble 1000;
BA_REL_ "GenSigTimeoutTime" BU_SG_REL_ Gateway SG_ 595 ADV_HPAParkInReady 1000;
BA_REL_ "GenSigTimeoutTime" BU_SG_REL_ Gateway SG_ 595 ADV_HPAParkOutReady 1000;
BA_REL_ "GenSigTimeoutTime" BU_SG_REL_ Gateway SG_ 595 ADV_AVPSuspendStatus 1000;
BA_REL_ "GenSigTimeoutTime" BU_SG_REL_ Gateway SG_ 595 ADV_HPAFucntion_SpeechControlFee 1000;
BA_REL_ "GenSigTimeoutTime" BU_SG_REL_ Gateway SG_ 595 ADV_SunRoofRequest 1000;
BA_REL_ "GenSigTimeoutTime" BU_SG_REL_ Gateway SG_ 595 ADV_AllWindowsCloseReq 1000;
BA_REL_ "GenSigTimeoutTime" BU_SG_REL_ Gateway SG_ 595 ADV_OvertakingLightReq 1000;
BA_REL_ "GenSigTimeoutTime" BU_SG_REL_ Gateway SG_ 595 ADV_LowBeamReq 1000;
BA_REL_ "GenSigTimeoutTime" BU_SG_REL_ Gateway SG_ 595 ADV_HighBeamReq 1000;
BA_REL_ "GenSigTimeoutTime" BU_SG_REL_ Gateway SG_ 595 ADV_AntitheftAlarmReq 1000;
BA_REL_ "GenSigTimeoutTime" BU_SG_REL_ Gateway SG_ 595 ADV_CeremonyModeReq 1000;
BA_REL_ "GenSigTimeoutTime" BU_SG_REL_ Gateway SG_ 595 ADV_HornReq 1000;
BA_REL_ "GenSigTimeoutTime" BU_SG_REL_ Gateway SG_ 595 ADV_AVPFucntion_SpeechControlFee 1000;
BA_REL_ "GenSigTimeoutTime" BU_SG_REL_ Gateway SG_ 595 ADV_HPASuspendStatus 1000;
BA_REL_ "GenSigTimeoutTime" BU_SG_REL_ Gateway SG_ 595 LiveCounter_ADV_5 1000;
BA_REL_ "GenSigTimeoutTime" BU_SG_REL_ Gateway SG_ 967 Checksum_ADV_6 1000;
BA_REL_ "GenSigTimeoutTime" BU_SG_REL_ Gateway SG_ 967 ADV_AVPFunctionTip 1000;
BA_REL_ "GenSigTimeoutTime" BU_SG_REL_ Gateway SG_ 967 ADV_HPAFunctionTip 1000;
BA_REL_ "GenSigTimeoutTime" BU_SG_REL_ Gateway SG_ 967 ADV_AVPStatus 1000;
BA_REL_ "GenSigTimeoutTime" BU_SG_REL_ AVP SG_ 967 ADV_AVPStatus 1000;
BA_REL_ "GenSigTimeoutTime" BU_SG_REL_ PDC SG_ 967 ADV_AVPStatus 1000;
BA_REL_ "GenSigTimeoutTime" BU_SG_REL_ Gateway SG_ 967 ADV_HPAStatus 1000;
BA_REL_ "GenSigTimeoutTime" BU_SG_REL_ AVP SG_ 967 ADV_HPAStatus 1000;
BA_REL_ "GenSigTimeoutTime" BU_SG_REL_ PDC SG_ 967 ADV_HPAStatus 1000;
BA_REL_ "GenSigTimeoutTime" BU_SG_REL_ Gateway SG_ 967 ADV_CeromonyModeReq_AtmosphereLi 1000;
BA_REL_ "GenSigTimeoutTime" BU_SG_REL_ Gateway SG_ 967 ADV_CeromonyModeReq_CPillerLight 1000;
BA_REL_ "GenSigTimeoutTime" BU_SG_REL_ Gateway SG_ 967 ADV_BreatheFreqReq_CPillerLight 1000;
BA_REL_ "GenSigTimeoutTime" BU_SG_REL_ Gateway SG_ 967 ADV_ColorReq_CPillerLight 1000;
BA_REL_ "GenSigTimeoutTime" BU_SG_REL_ Gateway SG_ 967 ADV_CeromonyModeReq_FrontGrilleL 1000;
BA_REL_ "GenSigTimeoutTime" BU_SG_REL_ Gateway SG_ 967 ADV_BreatheFreqReq_FrontGrilleLi 1000;
BA_REL_ "GenSigTimeoutTime" BU_SG_REL_ Gateway SG_ 967 ADV_ColorReq_FrontGrilleLight 1000;
BA_REL_ "GenSigTimeoutTime" BU_SG_REL_ Gateway SG_ 967 ADV_WOBCStopChargeReq 1000;
BA_REL_ "GenSigTimeoutTime" BU_SG_REL_ Gateway SG_ 967 ADV_WOBCEnquiryConfirm 1000;
BA_REL_ "GenSigTimeoutTime" BU_SG_REL_ Gateway SG_ 967 LiveCounter_ADV_6 1000;
BA_REL_ "GenSigTimeoutTime" BU_SG_REL_ Gateway SG_ 600 AVSSt 1000;
BA_REL_ "GenSigTimeoutTime" BU_SG_REL_ ADV SG_ 600 AVSSt 1000;
BA_REL_ "GenSigTimeoutTime" BU_SG_REL_ PDC SG_ 600 AVSSt 1000;
BA_REL_ "GenSigTimeoutTime" BU_SG_REL_ Gateway SG_ 600 AVSErrorSt 1000;
BA_REL_ "GenSigTimeoutTime" BU_SG_REL_ ADV SG_ 600 AVSErrorSt 1000;
BA_REL_ "GenSigTimeoutTime" BU_SG_REL_ Gateway SG_ 600 AVSViewMode 1000;
BA_REL_ "GenSigTimeoutTime" BU_SG_REL_ Gateway SG_ 600 AVSViewtype 1000;
BA_REL_ "GenSigTimeoutTime" BU_SG_REL_ Gateway SG_ 600 AVSCameraErrorSt_Front 1000;
BA_REL_ "GenSigTimeoutTime" BU_SG_REL_ ADV SG_ 600 AVSCameraErrorSt_Front 1000;
BA_REL_ "GenSigTimeoutTime" BU_SG_REL_ Gateway SG_ 600 AVSCameraErrorSt_Rear 1000;
BA_REL_ "GenSigTimeoutTime" BU_SG_REL_ ADV SG_ 600 AVSCameraErrorSt_Rear 1000;
BA_REL_ "GenSigTimeoutTime" BU_SG_REL_ Gateway SG_ 600 AVSCameraErrorSt_Left 1000;
BA_REL_ "GenSigTimeoutTime" BU_SG_REL_ ADV SG_ 600 AVSCameraErrorSt_Left 1000;
BA_REL_ "GenSigTimeoutTime" BU_SG_REL_ Gateway SG_ 600 AVSCameraErrorSt_Right 1000;
BA_REL_ "GenSigTimeoutTime" BU_SG_REL_ ADV SG_ 600 AVSCameraErrorSt_Right 1000;
BA_REL_ "GenSigTimeoutTime" BU_SG_REL_ Gateway SG_ 600 LanguageTypeSt_AVS 1000;
BA_REL_ "GenSigTimeoutTime" BU_SG_REL_ Gateway SG_ 600 DynamicPGSSt_AVS 1000;
BA_REL_ "GenSigTimeoutTime" BU_SG_REL_ Gateway SG_ 600 MODSt_AVS 1000;
BA_REL_ "GenSigTimeoutTime" BU_SG_REL_ Gateway SG_ 600 MODWarning_Front 1000;
BA_REL_ "GenSigTimeoutTime" BU_SG_REL_ ADV SG_ 600 MODWarning_Front 1000;
BA_REL_ "GenSigTimeoutTime" BU_SG_REL_ Gateway SG_ 600 MODWarning_Rear 1000;
BA_REL_ "GenSigTimeoutTime" BU_SG_REL_ ADV SG_ 600 MODWarning_Rear 1000;
BA_REL_ "GenSigTimeoutTime" BU_SG_REL_ Gateway SG_ 600 SwitchScreenRequest_AVS 1000;
BA_REL_ "GenSigTimeoutTime" BU_SG_REL_ Gateway SG_ 600 BlindSpotFilledFunctionInd 1000;
BA_REL_ "GenSigTimeoutTime" BU_SG_REL_ Gateway SG_ 600 FoundSlotBuzzerTip 1000;
BA_REL_ "GenSigTimeoutTime" BU_SG_REL_ Gateway SG_ 600 AVS_SpeechControlFeedback 1000;
BA_REL_ "GenSigTimeoutTime" BU_SG_REL_ Gateway SG_ 600 AVSCameraBlockageSt_Front 1000;
BA_REL_ "GenSigTimeoutTime" BU_SG_REL_ ADV SG_ 600 AVSCameraBlockageSt_Front 1000;
BA_REL_ "GenSigTimeoutTime" BU_SG_REL_ Gateway SG_ 600 AVSCameraBlockageSt_Rear 1000;
BA_REL_ "GenSigTimeoutTime" BU_SG_REL_ ADV SG_ 600 AVSCameraBlockageSt_Rear 1000;
BA_REL_ "GenSigTimeoutTime" BU_SG_REL_ Gateway SG_ 600 AVSCameraBlockageSt_Left 1000;
BA_REL_ "GenSigTimeoutTime" BU_SG_REL_ ADV SG_ 600 AVSCameraBlockageSt_Left 1000;
BA_REL_ "GenSigTimeoutTime" BU_SG_REL_ Gateway SG_ 600 AVSCameraBlockageSt_Right 1000;
BA_REL_ "GenSigTimeoutTime" BU_SG_REL_ ADV SG_ 600 AVSCameraBlockageSt_Right 1000;
BA_REL_ "GenSigTimeoutTime" BU_SG_REL_ Gateway SG_ 600 AVS_AbnormalTip 1000;
BA_REL_ "GenSigTimeoutTime" BU_SG_REL_ ADV SG_ 600 AVS_CalibrationSt 1000;
BA_REL_ "GenSigTimeoutTime" BU_SG_REL_ Gateway SG_ 600 AVS_PDWarning_Front 1000;
BA_REL_ "GenSigTimeoutTime" BU_SG_REL_ ADV SG_ 600 AVS_PDWarning_Front 1000;
BA_REL_ "GenSigTimeoutTime" BU_SG_REL_ Gateway SG_ 600 AVS_PDWarning_Rear 1000;
BA_REL_ "GenSigTimeoutTime" BU_SG_REL_ ADV SG_ 600 AVS_PDWarning_Rear 1000;
BA_REL_ "GenSigTimeoutTime" BU_SG_REL_ Gateway SG_ 600 AVS_RemoteMonitorigFeedback 1000;
BA_REL_ "GenSigTimeoutTime" BU_SG_REL_ Gateway SG_ 600 AVS_RemoteSharpnessFeedback 1000;
BA_REL_ "GenSigTimeoutTime" BU_SG_REL_ Gateway SG_ 600 RemoteMonitoringSharpnessSt_AVS 1000;
BA_REL_ "GenSigTimeoutTime" BU_SG_REL_ Gateway SG_ 600 RemoteMonitoringSt_AVS 1000;
BA_REL_ "GenSigTimeoutTime" BU_SG_REL_ Gateway SG_ 600 RemoteMonitoringModeSt_AVS 1000;
BA_REL_ "GenSigTimeoutTime" BU_SG_REL_ Gateway SG_ 600 AVS_RemoteViewModeFeedback 1000;
BA_REL_ "GenSigTimeoutTime" BU_SG_REL_ Gateway SG_ 599 Checksum_AVP_1 1000;
BA_REL_ "GenSigTimeoutTime" BU_SG_REL_ Gateway SG_ 599 AVP_AutoDriveDataRecordAvailable 1000;
BA_REL_ "GenSigTimeoutTime" BU_SG_REL_ Gateway SG_ 599 AVP_AutoDriveDataRecordStatus 1000;
BA_REL_ "GenSigTimeoutTime" BU_SG_REL_ Gateway SG_ 599 LiveCounter_AVP_1 1000;
BA_REL_ "GenSigTimeoutTime" BU_SG_REL_ Gateway SG_ 604 SysSt_PDC 1000;
BA_REL_ "GenSigTimeoutTime" BU_SG_REL_ ADV SG_ 604 SysSt_PDC 1000;
BA_REL_ "GenSigTimeoutTime" BU_SG_REL_ AVP SG_ 604 SysSt_PDC 1000;
BA_REL_ "GenSigTimeoutTime" BU_SG_REL_ AVM SG_ 604 SysSt_PDC 1000;
BA_REL_ "GenSigTimeoutTime" BU_SG_REL_ Gateway SG_ 604 ErrorSt_PDC 1000;
BA_REL_ "GenSigTimeoutTime" BU_SG_REL_ ADV SG_ 604 ErrorSt_PDC 1000;
BA_REL_ "GenSigTimeoutTime" BU_SG_REL_ AVP SG_ 604 ErrorSt_PDC 1000;
BA_REL_ "GenSigTimeoutTime" BU_SG_REL_ AVM SG_ 604 ErrorSt_PDC 1000;
BA_REL_ "GenSigTimeoutTime" BU_SG_REL_ Gateway SG_ 604 RadarSysSt_Front 1000;
BA_REL_ "GenSigTimeoutTime" BU_SG_REL_ ADV SG_ 604 RadarSysSt_Front 1000;
BA_REL_ "GenSigTimeoutTime" BU_SG_REL_ AVP SG_ 604 RadarSysSt_Front 1000;
BA_REL_ "GenSigTimeoutTime" BU_SG_REL_ AVM SG_ 604 RadarSysSt_Front 1000;
BA_REL_ "GenSigTimeoutTime" BU_SG_REL_ Gateway SG_ 604 RadarSysSt_Rear 1000;
BA_REL_ "GenSigTimeoutTime" BU_SG_REL_ ADV SG_ 604 RadarSysSt_Rear 1000;
BA_REL_ "GenSigTimeoutTime" BU_SG_REL_ AVP SG_ 604 RadarSysSt_Rear 1000;
BA_REL_ "GenSigTimeoutTime" BU_SG_REL_ AVM SG_ 604 RadarSysSt_Rear 1000;
BA_REL_ "GenSigTimeoutTime" BU_SG_REL_ Gateway SG_ 604 BuzeerCmd_PDC 1000;
BA_REL_ "GenSigTimeoutTime" BU_SG_REL_ ADV SG_ 604 BuzeerCmd_PDC 1000;
BA_REL_ "GenSigTimeoutTime" BU_SG_REL_ Gateway SG_ 604 BuzzerAlarmPosition 1000;
BA_REL_ "GenSigTimeoutTime" BU_SG_REL_ Gateway SG_ 604 RadarSysSt_FrontSide 1000;
BA_REL_ "GenSigTimeoutTime" BU_SG_REL_ ADV SG_ 604 RadarSysSt_FrontSide 1000;
BA_REL_ "GenSigTimeoutTime" BU_SG_REL_ AVP SG_ 604 RadarSysSt_FrontSide 1000;
BA_REL_ "GenSigTimeoutTime" BU_SG_REL_ AVM SG_ 604 RadarSysSt_FrontSide 1000;
BA_REL_ "GenSigTimeoutTime" BU_SG_REL_ Gateway SG_ 604 RadarSysSt_RearSide 1000;
BA_REL_ "GenSigTimeoutTime" BU_SG_REL_ ADV SG_ 604 RadarSysSt_RearSide 1000;
BA_REL_ "GenSigTimeoutTime" BU_SG_REL_ AVP SG_ 604 RadarSysSt_RearSide 1000;
BA_REL_ "GenSigTimeoutTime" BU_SG_REL_ AVM SG_ 604 RadarSysSt_RearSide 1000;
BA_REL_ "GenSigTimeoutTime" BU_SG_REL_ Gateway SG_ 604 BuzzerSwitchSt 1000;
BA_REL_ "GenSigTimeoutTime" BU_SG_REL_ Gateway SG_ 604 ObjectRange_RR 1000;
BA_REL_ "GenSigTimeoutTime" BU_SG_REL_ ADV SG_ 604 ObjectRange_RR 1000;
BA_REL_ "GenSigTimeoutTime" BU_SG_REL_ AVP SG_ 604 ObjectRange_RR 1000;
BA_REL_ "GenSigTimeoutTime" BU_SG_REL_ AVM SG_ 604 ObjectRange_RR 1000;
BA_REL_ "GenSigTimeoutTime" BU_SG_REL_ Gateway SG_ 604 SensorErrorSt_RR 1000;
BA_REL_ "GenSigTimeoutTime" BU_SG_REL_ ADV SG_ 604 SensorErrorSt_RR 1000;
BA_REL_ "GenSigTimeoutTime" BU_SG_REL_ AVP SG_ 604 SensorErrorSt_RR 1000;
BA_REL_ "GenSigTimeoutTime" BU_SG_REL_ AVM SG_ 604 SensorErrorSt_RR 1000;
BA_REL_ "GenSigTimeoutTime" BU_SG_REL_ Gateway SG_ 604 ObjectRange_RMR 1000;
BA_REL_ "GenSigTimeoutTime" BU_SG_REL_ ADV SG_ 604 ObjectRange_RMR 1000;
BA_REL_ "GenSigTimeoutTime" BU_SG_REL_ AVP SG_ 604 ObjectRange_RMR 1000;
BA_REL_ "GenSigTimeoutTime" BU_SG_REL_ AVM SG_ 604 ObjectRange_RMR 1000;
BA_REL_ "GenSigTimeoutTime" BU_SG_REL_ Gateway SG_ 604 SensorErrorSt_RMR 1000;
BA_REL_ "GenSigTimeoutTime" BU_SG_REL_ ADV SG_ 604 SensorErrorSt_RMR 1000;
BA_REL_ "GenSigTimeoutTime" BU_SG_REL_ AVP SG_ 604 SensorErrorSt_RMR 1000;
BA_REL_ "GenSigTimeoutTime" BU_SG_REL_ AVM SG_ 604 SensorErrorSt_RMR 1000;
BA_REL_ "GenSigTimeoutTime" BU_SG_REL_ Gateway SG_ 604 ObjectRange_RML 1000;
BA_REL_ "GenSigTimeoutTime" BU_SG_REL_ ADV SG_ 604 ObjectRange_RML 1000;
BA_REL_ "GenSigTimeoutTime" BU_SG_REL_ AVP SG_ 604 ObjectRange_RML 1000;
BA_REL_ "GenSigTimeoutTime" BU_SG_REL_ AVM SG_ 604 ObjectRange_RML 1000;
BA_REL_ "GenSigTimeoutTime" BU_SG_REL_ Gateway SG_ 604 SensorErrorSt_RML 1000;
BA_REL_ "GenSigTimeoutTime" BU_SG_REL_ ADV SG_ 604 SensorErrorSt_RML 1000;
BA_REL_ "GenSigTimeoutTime" BU_SG_REL_ AVP SG_ 604 SensorErrorSt_RML 1000;
BA_REL_ "GenSigTimeoutTime" BU_SG_REL_ AVM SG_ 604 SensorErrorSt_RML 1000;
BA_REL_ "GenSigTimeoutTime" BU_SG_REL_ Gateway SG_ 604 ObjectRange_RL 1000;
BA_REL_ "GenSigTimeoutTime" BU_SG_REL_ ADV SG_ 604 ObjectRange_RL 1000;
BA_REL_ "GenSigTimeoutTime" BU_SG_REL_ AVP SG_ 604 ObjectRange_RL 1000;
BA_REL_ "GenSigTimeoutTime" BU_SG_REL_ AVM SG_ 604 ObjectRange_RL 1000;
BA_REL_ "GenSigTimeoutTime" BU_SG_REL_ Gateway SG_ 604 SensorErrorSt_RL 1000;
BA_REL_ "GenSigTimeoutTime" BU_SG_REL_ ADV SG_ 604 SensorErrorSt_RL 1000;
BA_REL_ "GenSigTimeoutTime" BU_SG_REL_ AVP SG_ 604 SensorErrorSt_RL 1000;
BA_REL_ "GenSigTimeoutTime" BU_SG_REL_ AVM SG_ 604 SensorErrorSt_RL 1000;
BA_REL_ "GenSigTimeoutTime" BU_SG_REL_ Gateway SG_ 604 ObjectRange_FR 1000;
BA_REL_ "GenSigTimeoutTime" BU_SG_REL_ ADV SG_ 604 ObjectRange_FR 1000;
BA_REL_ "GenSigTimeoutTime" BU_SG_REL_ AVP SG_ 604 ObjectRange_FR 1000;
BA_REL_ "GenSigTimeoutTime" BU_SG_REL_ AVM SG_ 604 ObjectRange_FR 1000;
BA_REL_ "GenSigTimeoutTime" BU_SG_REL_ Gateway SG_ 604 SensorErrorSt_FR 1000;
BA_REL_ "GenSigTimeoutTime" BU_SG_REL_ ADV SG_ 604 SensorErrorSt_FR 1000;
BA_REL_ "GenSigTimeoutTime" BU_SG_REL_ AVP SG_ 604 SensorErrorSt_FR 1000;
BA_REL_ "GenSigTimeoutTime" BU_SG_REL_ AVM SG_ 604 SensorErrorSt_FR 1000;
BA_REL_ "GenSigTimeoutTime" BU_SG_REL_ Gateway SG_ 604 ObjectRange_FMR 1000;
BA_REL_ "GenSigTimeoutTime" BU_SG_REL_ ADV SG_ 604 ObjectRange_FMR 1000;
BA_REL_ "GenSigTimeoutTime" BU_SG_REL_ AVP SG_ 604 ObjectRange_FMR 1000;
BA_REL_ "GenSigTimeoutTime" BU_SG_REL_ AVM SG_ 604 ObjectRange_FMR 1000;
BA_REL_ "GenSigTimeoutTime" BU_SG_REL_ Gateway SG_ 604 SensorErrorSt_FMR 1000;
BA_REL_ "GenSigTimeoutTime" BU_SG_REL_ ADV SG_ 604 SensorErrorSt_FMR 1000;
BA_REL_ "GenSigTimeoutTime" BU_SG_REL_ AVP SG_ 604 SensorErrorSt_FMR 1000;
BA_REL_ "GenSigTimeoutTime" BU_SG_REL_ AVM SG_ 604 SensorErrorSt_FMR 1000;
BA_REL_ "GenSigTimeoutTime" BU_SG_REL_ Gateway SG_ 604 ObjectRange_FML 1000;
BA_REL_ "GenSigTimeoutTime" BU_SG_REL_ ADV SG_ 604 ObjectRange_FML 1000;
BA_REL_ "GenSigTimeoutTime" BU_SG_REL_ AVP SG_ 604 ObjectRange_FML 1000;
BA_REL_ "GenSigTimeoutTime" BU_SG_REL_ AVM SG_ 604 ObjectRange_FML 1000;
BA_REL_ "GenSigTimeoutTime" BU_SG_REL_ Gateway SG_ 604 SensorErrorSt_FML 1000;
BA_REL_ "GenSigTimeoutTime" BU_SG_REL_ ADV SG_ 604 SensorErrorSt_FML 1000;
BA_REL_ "GenSigTimeoutTime" BU_SG_REL_ AVP SG_ 604 SensorErrorSt_FML 1000;
BA_REL_ "GenSigTimeoutTime" BU_SG_REL_ AVM SG_ 604 SensorErrorSt_FML 1000;
BA_REL_ "GenSigTimeoutTime" BU_SG_REL_ Gateway SG_ 604 ObjectRange_FL 1000;
BA_REL_ "GenSigTimeoutTime" BU_SG_REL_ ADV SG_ 604 ObjectRange_FL 1000;
BA_REL_ "GenSigTimeoutTime" BU_SG_REL_ AVP SG_ 604 ObjectRange_FL 1000;
BA_REL_ "GenSigTimeoutTime" BU_SG_REL_ AVM SG_ 604 ObjectRange_FL 1000;
BA_REL_ "GenSigTimeoutTime" BU_SG_REL_ Gateway SG_ 604 SensorErrorSt_FL 1000;
BA_REL_ "GenSigTimeoutTime" BU_SG_REL_ ADV SG_ 604 SensorErrorSt_FL 1000;
BA_REL_ "GenSigTimeoutTime" BU_SG_REL_ AVP SG_ 604 SensorErrorSt_FL 1000;
BA_REL_ "GenSigTimeoutTime" BU_SG_REL_ AVM SG_ 604 SensorErrorSt_FL 1000;
BA_REL_ "GenSigTimeoutTime" BU_SG_REL_ Gateway SG_ 604 PDCAutoOnFunctionInd 1000;
BA_REL_ "GenSigTimeoutTime" BU_SG_REL_ Gateway SG_ 604 SwitchScreenRequest_PDC 1000;
BA_REL_ "GenSigTimeoutTime" BU_SG_REL_ Gateway SG_ 604 PDC_SpeechControlFeedback 1000;
BA_REL_ "GenSigTimeoutTime" BU_SG_REL_ ADV SG_ 604 PDC_SpeechControlFeedback 1000;
BA_REL_ "GenSigTimeoutTime" BU_SG_REL_ AVP SG_ 604 PDC_SearchingSlotPosition 1000;
BA_REL_ "GenSigTimeoutTime" BU_SG_REL_ AVM SG_ 604 PDC_SearchingSlotPosition 1000;
BA_REL_ "GenSigTimeoutTime" BU_SG_REL_ ADV SG_ 604 PDC_FunctionTip 1000;
BA_REL_ "GenSigTimeoutTime" BU_SG_REL_ AVP SG_ 604 PDC_FunctionTip 1000;
BA_REL_ "GenSigTimeoutTime" BU_SG_REL_ AVM SG_ 604 PDC_FunctionTip 1000;
BA_REL_ "GenSigTimeoutTime" BU_SG_REL_ ADV SG_ 456 Checksum_PDC_11 500;
BA_REL_ "GenSigTimeoutTime" BU_SG_REL_ AVP SG_ 456 Checksum_PDC_11 500;
BA_REL_ "GenSigTimeoutTime" BU_SG_REL_ AVM SG_ 456 Checksum_PDC_11 500;
BA_REL_ "GenSigTimeoutTime" BU_SG_REL_ ADV SG_ 456 CCoordinateY_Left 500;
BA_REL_ "GenSigTimeoutTime" BU_SG_REL_ AVP SG_ 456 CCoordinateY_Left 500;
BA_REL_ "GenSigTimeoutTime" BU_SG_REL_ AVM SG_ 456 CCoordinateY_Left 500;
BA_REL_ "GenSigTimeoutTime" BU_SG_REL_ ADV SG_ 456 CCoordinateX_Left 500;
BA_REL_ "GenSigTimeoutTime" BU_SG_REL_ AVP SG_ 456 CCoordinateX_Left 500;
BA_REL_ "GenSigTimeoutTime" BU_SG_REL_ AVM SG_ 456 CCoordinateX_Left 500;
BA_REL_ "GenSigTimeoutTime" BU_SG_REL_ ADV SG_ 456 DCoordinateY_Left 500;
BA_REL_ "GenSigTimeoutTime" BU_SG_REL_ AVP SG_ 456 DCoordinateY_Left 500;
BA_REL_ "GenSigTimeoutTime" BU_SG_REL_ AVM SG_ 456 DCoordinateY_Left 500;
BA_REL_ "GenSigTimeoutTime" BU_SG_REL_ ADV SG_ 456 DCoordinateX_Left 500;
BA_REL_ "GenSigTimeoutTime" BU_SG_REL_ AVP SG_ 456 DCoordinateX_Left 500;
BA_REL_ "GenSigTimeoutTime" BU_SG_REL_ AVM SG_ 456 DCoordinateX_Left 500;
BA_REL_ "GenSigTimeoutTime" BU_SG_REL_ ADV SG_ 456 LiveCounter_PDC_11 500;
BA_REL_ "GenSigTimeoutTime" BU_SG_REL_ AVP SG_ 456 LiveCounter_PDC_11 500;
BA_REL_ "GenSigTimeoutTime" BU_SG_REL_ AVM SG_ 456 LiveCounter_PDC_11 500;
VAL_ 282 HAD_AutoDrivingReq_L3 3 "Reserved" 2 "L3Request" 1 "L1L2Request" 0 "No Request" ;
VAL_ 282 HAD_SpeedChangeRequest_L3 2047 "SNA" ;
VAL_ 282 HAD_MaxAccGrad_L3 255 "SNA" ;
VAL_ 282 HAD_MinAccGrad_L3 255 "SNA" ;
VAL_ 282 HAD_MaxComfBand_L3 255 "SNA" ;
VAL_ 282 HAD_MinComfBand_L3 255 "SNA" ;
VAL_ 282 HAD_UseMaxComfBand_L3 1 "Active" 0 "Inactive" ;
VAL_ 282 HAD_HDMapUsingst_L3 3 "Reserved" 2 "Reserved" 1 "Active" 0 "Inactive" ;
VAL_ 283 HAD_BrakeModeReq_L3 3 "Reserved" 2 "Emergency" 1 "Comfortable" 0 "LongControlOff" ;
VAL_ 283 HAD_DrivedownReq_L3 1 "Drive down request" 0 "No request" ;
VAL_ 283 HAD_SecureRequest_L3 3 "Reserved" 2 "Release secure request" 1 "Secure request" 0 "No request" ;
VAL_ 283 HAD_ErrorSt_AutoDriving_L3 3 "Reserved" 2 "Error" 1 "Reduced" 0 "No Error" ;
VAL_ 278 HAD_TorqueRequest 1023 "SNA" ;
VAL_ 278 HAD_TorqueRequestSign 1 "Right (Negative)" 0 "Left (Positive)" ;
VAL_ 278 HAD_TorqueReqSt 1 "Torque Request" 0 "Inactive" ;
VAL_ 278 HAD_Intervention_LKA 3 "Reserved" 2 "Right Intervention" 1 "Left Intervention" 0 "Not Intervention" ;
VAL_ 278 HAD_WorkingSt_LKA 3 "Error" 2 "Active" 1 "Standby" 0 "Off" ;
VAL_ 278 HAD_ErrorSt_LKA 1 "Error" 0 "No Error" ;
VAL_ 278 HAD_TakeOverTip_LCA 1 "Active" 0 "Inactive" ;
VAL_ 278 HAD_HandsOffTip_LCA 3 "Reserved" 2 "Level2" 1 "Level1" 0 "Inactive" ;
VAL_ 278 HAD_WorkingSt_LCA 7 "Reserved" 6 "Recoverable-SteeeringOverride" 5 "Recoverable-LaneLineDisappearing" 4 "Exit" 3 "Active" 2 "Available" 1 "Standby" 0 "Off" ;
VAL_ 278 HAD_ErrorSt_LCA 1 "Error" 0 "No Error" ;
VAL_ 278 HAD_AutoDrivingModeReq 7 "Reserved" 6 "Reserved" 5 "Reserved" 4 "TJP" 3 "HWP" 2 "SACC" 1 "LKA" 0 "No request" ;
VAL_ 278 HAD_ErrorSt_SACC 3 "Reserved" 2 "Error" 1 "Derate" 0 "Normal" ;
VAL_ 278 HAD_ErrorSt_HWP 3 "Reserved" 2 "Error" 1 "Derate" 0 "Normal" ;
VAL_ 278 HAD_ErrorSt_TJP 3 "Reserved" 2 "Error" 1 "Derate" 0 "Normal" ;
VAL_ 278 HAD_LDWSteeringVibrationReq 1 "Request" 0 "No Request" ;
VAL_ 278 HAD_WorkingSt_DCLC 7 "Reserved" 6 "Reserved" 5 "Reserved" 4 "Exit" 3 "Active" 2 "Available" 1 "Standby" 0 "Off" ;
VAL_ 278 HAD_WorkingSt_HWP 7 "Reserved" 6 "Reserved" 5 "Reserved" 4 "Exit" 3 "Active" 2 "Available" 1 "Standby" 0 "Off" ;
VAL_ 278 HAD_WorkingSt_TJP 7 "Reserved" 6 "Reserved" 5 "Reserved" 4 "Exit" 3 "Active" 2 "Available" 1 "Standby" 0 "Off" ;
VAL_ 278 HAD_ErrorSt_HAD 1 "Error" 0 "No Error" ;
VAL_ 272 IFC_WorkingSt_AEB_L12 3 "Reserved" 2 "Active" 1 "Standby" 0 "Off" ;
VAL_ 272 IFC_ErrorSt_AEB_L12 1 "Error" 0 "No Error" ;
VAL_ 272 IFC_ErrorSt_ACC_L12 1 "Error" 0 "No Error" ;
VAL_ 272 IFC_WorkingSt_ACC_L12 7 "Reserved" 6 "Reserved" 5 "Reserved" 4 "Shutoff" 3 "Override" 2 "Active" 1 "Stand By" 0 "Off" ;
VAL_ 272 IFC_ABPReq_L12 1 "Request" 0 "Inactive" ;
VAL_ 272 IFC_AWBReq_L12 1 "Request" 0 "Inactive" ;
VAL_ 272 IFC_AWBlevel_L12 7 "Reserved" 6 "Reserved" 5 "Reserved" 4 "Level4" 3 "Level3" 2 "Level2" 1 "Level1" 0 "Inactive" ;
VAL_ 272 CruiseModeFunctionInd 3 "Reseved" 2 "SACC" 1 "ACC" 0 "Off" ;
VAL_ 272 IFC_BrakeModeReq_L12 3 "Reserved" 2 "Emergency" 1 "Comfortable" 0 "LongControlOff" ;
VAL_ 272 IFC_DrivedownReq_L12 1 "Request" 0 "No Request" ;
VAL_ 272 IFC_SecureRequest_L12 1 "Request" 0 "No Request" ;
VAL_ 272 IFC_AEBSensitivity_L12 3 "High" 2 "Normal" 1 "Low" 0 "Inactive" ;
VAL_ 272 IFC_AutoDrivingReq 3 "Reserved" 2 "L3" 1 "L12" 0 "Inactive" ;
VAL_ 275 IFC_AutoDrivingReq_L12 3 "Reserved" 2 "L3Request" 1 "L1L2Request" 0 "No Request" ;
VAL_ 275 IFC_SpeedChangeRequest_L12 2047 "SNA" ;
VAL_ 275 IFC_MaxAccGrad_L12 255 "SNA" ;
VAL_ 275 IFC_MinAccGrad_L12 255 "SNA" ;
VAL_ 275 IFC_MaxComfBand_L12 255 "SNA" ;
VAL_ 275 IFC_MinComfBand_L12 255 "SNA" ;
VAL_ 275 IFC_UseMaxComfBand_L12 1 "Active" 0 "Inactive" ;
VAL_ 294 FOU_AutoDrivingReq_L3 3 "Reserved" 2 "L3Request" 1 "L1L2Request" 0 "No Request" ;
VAL_ 294 FOU_SpeedChangeRequest_L3 2047 "SNA" ;
VAL_ 294 FOU_MaxAccGrad_L3 255 "SNA" ;
VAL_ 294 FOU_MinAccGrad_L3 255 "SNA" ;
VAL_ 294 FOU_MaxComfBand_L3 255 "SNA" ;
VAL_ 294 FOU_MinComfBand_L3 255 "SNA" ;
VAL_ 294 FOU_UseMaxComfBand_L3 1 "Active" 0 "Inactive" ;
VAL_ 295 FOU_BrakeModeReq_L3 3 "Reserved" 2 "Emergency" 1 "Comfortable" 0 "LongControlOff" ;
VAL_ 295 FOU_DrivedownReq_L3 1 "Drive down request" 0 "No request" ;
VAL_ 295 FOU_SecureRequest_L3 3 "Reserved" 2 "Release secure request" 1 "Secure request" 0 "No request" ;
VAL_ 295 FOU_ErrorSt_AutoDriving_L3 3 "Reserved" 2 "Error" 1 "Reduced" 0 "No Error" ;
VAL_ 295 FOU_WorkingSt_AutoDriving_L3 7 "Reserved" 6 "Exit" 5 "Locked" 4 "Hold" 3 "Fallback-Stop" 2 "TOR-Urgent" 1 "Stand By" 0 "Off" ;
VAL_ 274 IFC_TorqueRequest 1023 "SNA" ;
VAL_ 274 IFC_TorqueRequestSign 1 "Right (Negative)" 0 "Left (Positive)" ;
VAL_ 274 IFC_TorqueReqSt 1 "Torque Request" 0 "Inactive" ;
VAL_ 274 IFC_Intervention_LKA 3 "Reserved" 2 "Right Intervention" 1 "Left Intervention" 0 "Not Intervention" ;
VAL_ 274 IFC_WorkingSt_LKA 3 "Error" 2 "Active" 1 "Standby" 0 "Off" ;
VAL_ 274 IFC_ErrorSt_LKA 1 "Error" 0 "No Error" ;
VAL_ 274 IFC_TakeOverTip_LCA 1 "Active" 0 "Inactive" ;
VAL_ 274 IFC_HandsOffTip_LCA 3 "Reserved" 2 "Level2" 1 "Level1" 0 "Inactive" ;
VAL_ 274 IFC_WorkingSt_LCA 7 "Reserved" 6 "Recoverable-SteeeringOverride" 5 "Recoverable-LaneLineDisappearing" 4 "Exit" 3 "Active" 2 "Available" 1 "Standby" 0 "Off" ;
VAL_ 274 IFC_ErrorSt_LCA 1 "Error" 0 "No Error" ;
VAL_ 274 IFC_AutoDrivingModeReq 7 "Reserved" 6 "Reserved" 5 "Reserved" 4 "Reserved" 3 "Reserved" 2 "SACC" 1 "LKA" 0 "No request" ;
VAL_ 274 IFC_ErrorSt_SACC 3 "Reserved" 2 "Error" 1 "Derate" 0 "Normal" ;
VAL_ 274 FOU_ErrorSt_HWP 3 "Reserved" 2 "Error" 1 "Derate" 0 "Normal" ;
VAL_ 274 FOU_ErrorSt_TJP 3 "Reserved" 2 "Error" 1 "Derate" 0 "Normal" ;
VAL_ 274 LDWSteeringVibrationReq 1 "Request" 0 "No Request" ;
VAL_ 274 IFC_WorkingSt_SACC 7 "Reserved" 6 "Reserved" 5 "Reserved" 4 "Exit" 3 "Active" 2 "Available" 1 "Standby" 0 "Off" ;
VAL_ 274 FOU_WorkingSt_HWP 7 "Reserved" 6 "Reserved" 5 "Reserved" 4 "Exit" 3 "Active" 2 "Available" 1 "Standby" 0 "Off" ;
VAL_ 274 FOU_WorkingSt_TJP 7 "Reserved" 6 "Reserved" 5 "Reserved" 4 "Exit" 3 "Active" 2 "Available" 1 "Standby" 0 "Off" ;
VAL_ 274 IFC_ErrorSt_FOU 1 "Error" 0 "No Error" ;
VAL_ 279 IFC_SteeringWheelAngleRequest 32767 "SNA" ;
VAL_ 279 IFC_SteeringWheelAngleSignReques 3 "Reserved" 2 "Right (Negative)" 1 "Left (Positive)" 0 "No Request" ;
VAL_ 279 IFC_SteeringWheelAngleControlReq 3 "Reserved" 2 "Reserved" 1 "Steering Angle Request" 0 "No Request" ;
VAL_ 607 HAD_CruiseSpeedSetting_ACC 255 "SNA" ;
VAL_ 607 HAD_TimeGapSetting 7 "Reserved" 6 "Reserved" 5 "Reserved" 4 "Reserved" 3 "TimeGap4" 2 "TimeGap3" 1 "TimeGap2" 0 "TimeGap1" ;
VAL_ 607 HAD_ObjectDetection 1 "Target object detected" 0 "No object" ;
VAL_ 607 HAD_SysTextinfo 15 "Radar is covered" 14 "Radar not calibration" 13 "SACC cancelled autoly" 12 "LCA cancelled autoly" 11 "ACC cancelled autoly" 10 "Speed is less than 10,unable to active ACC" 9 "Camera is not calibration" 8 "Camera is polluted, please clean the camera cover." 7 "System initial" 6 "Bad weather,system can not work" 5 "Because  driver cancel operation" 4 "Because ESC interven, ACC cancelled" 3 "Stop-Go clue -step gas pedal or press resume key" 2 "Radar error" 1 "Conditions not satisfied, unable to active ACC" 0 "No display" ;
VAL_ 607 HAD_LDWModeInd 3 "Reserved" 2 "LDW+LKA" 1 "LDW+Vibration" 0 "LDW only" ;
VAL_ 607 HAD_TakeOverReq 1 "Request" 0 "No request" ;
VAL_ 607 HAD_AutoLightModeReq 1 "Request" 0 "No request" ;
VAL_ 607 HAD_HazardWarningLampRequest 1 "Request" 0 "No request" ;
VAL_ 607 HAD_WorkingSt_LDW 3 "Error" 2 "Active" 1 "Standby" 0 "Off" ;
VAL_ 607 HAD_WarningCmd_LDW 3 "Reserved" 2 "RightWarning" 1 "LeftWarning" 0 "Inactive" ;
VAL_ 607 HAD_LDWLaneDetectSt 3 "Both side lane marks detected" 2 "Right side lane mark detected" 1 "Left side lane mark detected" 0 "Neither side lane mark detected" ;
VAL_ 607 HAD_SensitivityInd_LDW 3 "Reserved" 2 "High" 1 "Normal" 0 "Low" ;
VAL_ 607 HAD_ErrorSt_LDW 1 "Error" 0 "No Error" ;
VAL_ 607 HAD_WorkingSt_FCW 3 "Reserved" 2 "Active" 1 "Standby" 0 "Off" ;
VAL_ 607 HAD_WarningCmd_FCW 3 "Reserved" 2 "Cautionary Alert" 1 "Imminent Alert" 0 "No Alert" ;
VAL_ 607 HAD_ErrorSt_FCW 1 "Error" 0 "No Error" ;
VAL_ 607 HAD_SensitivityInd_FCW 3 "Reserved" 2 "High" 1 "Normal" 0 "Low" ;
VAL_ 607 HAD_FCWModeInd 3 "Reserved" 2 "FCW+EAB" 1 "Reserved" 0 "FCW only" ;
VAL_ 607 HAD_WiperAutoLeverReq 1 "Request" 0 "No request" ;
VAL_ 607 HAD_SACCNotSatisfiedCondition 7 "Abnormal exited for driver not taking over,power on again and try then" 6 "AutoParking active" 5 "The door is open" 4 "Hands off " 3 "Turning around" 2 "Tite your seatbelt" 1 "Speed too high" 0 "Inactive" ;
VAL_ 607 HAD_LDW_SpeechControlFeedback 7 "Reserved" 6 "Reserved" 5 "Reserved" 4 "On Failure" 3 "On Success" 2 "Off Failure" 1 "Off Success" 0 "Inactive" ;
VAL_ 607 HAD_VASFunctionInd 1 "On" 0 "Off" ;
VAL_ 607 HAD_IFCSystemError 3 "Reserved" 2 "Camera is covered,please clean" 1 "System error" 0 "No error" ;
VAL_ 607 HAD_IFCCalibrationStatus 3 "Not Calibrationed" 2 "Calibration Failed" 1 "Calibrating" 0 "Calibration Success" ;
VAL_ 607 HAD_WarningCmd_VAS 1 "Active" 0 "Inactive" ;
VAL_ 607 HAD_LeftTurningLampRequest 3 "Reserved" 2 "On" 1 "Off" 0 "No request" ;
VAL_ 607 HAD_RightTurningLampRequest 3 "Reserved" 2 "On" 1 "Off" 0 "No request" ;
VAL_ 607 HAD_ValetModeStatus 1 "On" 0 "Off" ;
VAL_ 608 CruiseSpeedSetting_ACC 255 "SNA" ;
VAL_ 608 TimeGapSetting 7 "Reserved" 6 "Reserved" 5 "Reserved" 4 "Reserved" 3 "TimeGap4" 2 "TimeGap3" 1 "TimeGap2" 0 "TimeGap1" ;
VAL_ 608 ObjectDetection 1 "Target object detected" 0 "No object" ;
VAL_ 608 SysTextinfo 15 "Radar is covered" 14 "Radar not calibration" 13 "SACC cancelled autoly" 12 "LCA cancelled autoly" 11 "ACC cancelled autoly" 10 "Speed is less than 10,unable to active ACC" 9 "Camera is not calibration" 8 "Camera is polluted, please clean the camera cover." 7 "System initial" 6 "Bad weather,system can not work" 5 "Because  driver cancel operation" 4 "Because ESC interven, ACC cancelled" 3 "Stop-Go clue -step gas pedal or press resume key" 2 "Radar error" 1 "Conditions not satisfied, unable to active ACC" 0 "No display" ;
VAL_ 608 LDWModeInd 3 "Reserved" 2 "LDW+LKA" 1 "LDW+Vibration" 0 "LDW only" ;
VAL_ 608 TakeOverReq 1 "Request" 0 "No request" ;
VAL_ 608 AutoLightModeReq 1 "Request" 0 "No request" ;
VAL_ 608 HazardWarningLampRequest 1 "Request" 0 "No request" ;
VAL_ 608 WorkingSt_LDW 3 "Error" 2 "Active" 1 "Standby" 0 "Off" ;
VAL_ 608 WarningCmd_LDW 3 "Reserved" 2 "RightWarning" 1 "LeftWarning" 0 "Inactive" ;
VAL_ 608 LDWLaneDetectSt 3 "Both side lane marks detected" 2 "Right side lane mark detected" 1 "Left side lane mark detected" 0 "Neither side lane mark detected" ;
VAL_ 608 SensitivityInd_LDW 3 "Reserved" 2 "High" 1 "Normal" 0 "Low" ;
VAL_ 608 ErrorSt_LDW 1 "Error" 0 "No Error" ;
VAL_ 608 WorkingSt_FCW 3 "Reserved" 2 "Active" 1 "Standby" 0 "Off" ;
VAL_ 608 WarningCmd_FCW 3 "Reserved" 2 "Cautionary Alert" 1 "Imminent Alert" 0 "No Alert" ;
VAL_ 608 ErrorSt_FCW 1 "Error" 0 "No Error" ;
VAL_ 608 SensitivityInd_FCW 3 "Reserved" 2 "High" 1 "Normal" 0 "Low" ;
VAL_ 608 FCWModeInd 3 "Reserved" 2 "FCW+EAB" 1 "Reserved" 0 "FCW only" ;
VAL_ 608 WiperAutoLeverReq 1 "Request" 0 "No request" ;
VAL_ 608 SACCNotSatisfiedCondition 7 "Abnormal exited for driver not taking over,power on again and try then" 6 "AutoParking active" 5 "The door is open" 4 "Hands off " 3 "Turning around" 2 "Tite your seatbelt" 1 "Speed too high" 0 "Inactive" ;
VAL_ 608 LDW_SpeechControlFeedback 7 "Reserved" 6 "Reserved" 5 "Reserved" 4 "On Failure" 3 "On Success" 2 "Off Failure" 1 "Off Success" 0 "Inactive" ;
VAL_ 608 VASFunctionInd 1 "On" 0 "Off" ;
VAL_ 608 IFCSystemError 3 "Reserved" 2 "Camera is covered,please clean" 1 "System error" 0 "No error" ;
VAL_ 608 IFCCalibrationStatus 3 "Not Calibrationed" 2 "Calibration Failed" 1 "Calibrating" 0 "Calibration Success" ;
VAL_ 608 WarningCmd_VAS 1 "Active" 0 "Inactive" ;
VAL_ 608 IFC_LeftTurningLampRequest 3 "Reserved" 2 "On" 1 "Off" 0 "No request" ;
VAL_ 608 IFC_RightTurningLampRequest 3 "Reserved" 2 "On" 1 "Off" 0 "No request" ;
VAL_ 609 HAD_LimitedVehicleSpeed_TSR 255 "SNA" ;
VAL_ 609 HAD_WorkingSt_TSR 3 "Reserved" 2 "Active" 1 "Standby" 0 "Off" ;
VAL_ 609 HAD_WarningCmd_TSR 3 "Reserved" 2 "Warning2" 1 "Warning1" 0 "Inactive" ;
VAL_ 609 HAD_ErrorSt_TSR 1 "Error" 0 "No Error" ;
VAL_ 609 HAD_VAS_SpeechControlFeedback 7 "Reserved" 6 "Reserved" 5 "Reserved" 4 "On Failure" 3 "On Success" 2 "Off Failure" 1 "Off Success" 0 "Inactive" ;
VAL_ 609 HAD_TSR_SpeechControlFeedback 7 "Reserved" 6 "Reserved" 5 "Reserved" 4 "On Failure" 3 "On Success" 2 "Off Failure" 1 "Off Success" 0 "Inactive" ;
VAL_ 610 LimitedVehicleSpeed_TSR 255 "SNA" ;
VAL_ 610 WorkingSt_TSR 3 "Reserved" 2 "Active" 1 "Standby" 0 "Off" ;
VAL_ 610 WarningCmd_TSR 3 "Reserved" 2 "Warning2" 1 "Warning1" 0 "Inactive" ;
VAL_ 610 ErrorSt_TSR 1 "Error" 0 "No Error" ;
VAL_ 610 WorkingSt_DSM 3 "Reserved" 2 "Active" 1 "Standby" 0 "Off" ;
VAL_ 610 WarningCmd_DSM 3 "Reserved" 2 "Warning2" 1 "Warning1" 0 "Inactive" ;
VAL_ 610 ErrorSt_DSM 1 "Error" 0 "No Error" ;
VAL_ 610 DSMFunctionInd 3 "Reserved" 2 "4 Hours" 1 "2 Hours" 0 "Off" ;
VAL_ 610 VAS_SpeechControlFeedback 7 "Reserved" 6 "Reserved" 5 "Reserved" 4 "On Failure" 3 "On Success" 2 "Off Failure" 1 "Off Success" 0 "Inactive" ;
VAL_ 610 TSR_SpeechControlFeedback 7 "Reserved" 6 "Reserved" 5 "Reserved" 4 "On Failure" 3 "On Success" 2 "Off Failure" 1 "Off Success" 0 "Inactive" ;
VAL_ 610 DSM_SpeechControlFeedback 7 "Reserved" 6 "Reserved" 5 "Reserved" 4 "On Failure" 3 "On Success" 2 "Off Failure" 1 "Off Success" 0 "Inactive" ;
VAL_ 611 HAD_AutoDrivingSt 15 "Invalid" 14 "Reserved" 14 "Reserved" 13 "HWP" 12 "TJP" 11 "SACC" 10 "ACC" 9 "LKA" 8 "Off" ;
VAL_ 592 ADV_ParkType 7 "Reserved" 6 "Reserved" 5 "Reserved" 4 "Reserved" 3 "Auto" 2 "Backward Oblique " 1 "Backward Perpendicular" 0 "Parallel" ;
VAL_ 592 ADV_ParkInSlotSearchMode 1 "Manual" 0 "Auto" ;
VAL_ 592 ADV_ParkStatus 15 "Reserved" 14 "Reserved" 13 "Reserved" 12 "Reserved" 11 "Error" 10 "Finish" 9 "Abort" 8 "Suspended" 7 "Driver override" 6 "Parking out" 5 "Parking in" 4 "Map update" 3 "Searching for park-out" 2 "Searching for park-in" 1 "Stand by" 0 "Initial" ;
VAL_ 592 ADV_SystemError 1 "Error" 0 "No error" ;
VAL_ 592 ADV_ParkInAvaialble 1 "Available" 0 "Not Available" ;
VAL_ 592 ADV_ParkOutAvaialble 1 "Available" 0 "Not Available" ;
VAL_ 592 ADV_ParkInReady 1 "Ready" 0 "Not ready" ;
VAL_ 592 ADV_ParkOutReady 1 "Ready" 0 "Not ready" ;
VAL_ 592 ADV_ParkOutDirection 7 "Reserved" 6 "Reserved" 5 "Left Parallel" 4 "Right Parallel" 3 "Left perpendicular" 2 "Rear perpendicular" 1 "Front perpendicular" 0 "Right perpendicular" ;
VAL_ 592 ADV_VehicleModeRequest 3 "Reserved" 2 "Remote mode" 1 "Normal mode" 0 "No request" ;
VAL_ 592 ADV_BrakeLightCtrlCmd 1 "Illuminate" 0 "Not illuminate" ;
VAL_ 592 ADV_HazardWarningLampRequest 3 "Reserved" 2 "Reserved" 1 "Request" 0 "No request" ;
VAL_ 592 ADV_DoorRequest 3 "Reserved" 2 "Unlock" 1 "Lock" 0 "No request" ;
VAL_ 592 ADV_LeftTurningLampRequest 3 "Reserved" 2 "On" 1 "Off" 0 "No request" ;
VAL_ 592 ADV_RightTurningLampRequest 3 "Reserved" 2 "On" 1 "Off" 0 "No request" ;
VAL_ 592 ADV_EngineAndEVStopRequest 3 "Reserved" 2 "Reserved" 1 "Request" 0 "No request" ;
VAL_ 592 ADV_FunctionAbnormalTip 63 "Reserved" 62 "Reserved" 61 "Reserved" 60 "Reserved" 59 "Reserved" 58 "Reserved" 57 "Reserved" 56 "Reserved" 55 "Reserved" 54 "Reserved" 53 "Reserved" 52 "Air suspension is adjusting" 51 "Vehicle is in remote mode" 50 "Start park out tip" 49 "Start park in tip" 48 "Disclaimer tip" 47 "Wifi signal loss" 46 "Abnormal tire pressure" 45 "Space Unknown" 44 "Space Insufficient" 43 "Parking has been completed " 42 "Press DMH to start or exit" 41 "vehicle height not fulfilled" 40 "Vehicle direction incorrect" 39 "EPS System Can't Response Correctly" 38 "driving brake  System Can't Response Correctly" 37 "AVS System Can't Response Correctly" 36 "Start System Can't Response Correctly" 35 "Door System Can't Response Correctly" 34 "Remote control System Can't Response Correctly" 33 "Gear shift System Can't Response Correctly" 32 "Parking Brake System Can't Response Correctly" 31 "Forward-looking signal is unavailable" 30 "PDC Signal Interface Not Available " 29 "AVS Signal Interface Not Available " 28 "YAW Signal Interface Not Available " 27 "SAS Signal Interface Not Available " 26 "Onekey startup interface is unavailable" 25 "IVI Interface Not Available" 24 "Vehicle Drive Interface Not Available" 23 "Comfort System Interface unavailable" 22 "Steering interface unavailable" 21 "Parking Brake Interface unavailable" 20 "Shift gears interface unavailable" 19 "Driving Brake Interface unavailable" 18 "SACC or LKA activated" 17 "Tracking error" 16 "Unable to switch vehicle mode" 15 "Space Insufficient" 14 "Obstacle is too close" 13 "Door open" 12 "Cannot enter parking status " 11 "Speed too fast,system exit" 10 "Speed too fast,Please slow down" 9 "Parking cannot completed please take over" 8 "Road surface complexity " 7 "Gradient too high" 6 "Driver intervention EPB" 5 "Driver intervention steering wheel " 4 "Driver intervention brake pedal " 3 "Vehicle not started" 2 "Parking system exit by hard button " 1 "Parking system exit by soft button" 0 "Inactive" ;
VAL_ 592 ADV_ParkInEnabled 1 "Enabled" 0 "Not Enabled" ;
VAL_ 592 ADV_ParkOutEnabled 1 "Enabled" 0 "Not Enabled" ;
VAL_ 592 ADV_ParkingStep 3 "Reserved" 2 "Parking Out On" 1 "Parking In On" 0 "Parking Off" ;
VAL_ 592 ADV_RearViewMirrorFoldRequest 3 "Reserved" 2 "Unfold" 1 "Fold" 0 "No request" ;
VAL_ 592 ADV_ParkingAEBFunctionInd 1 "ON" 0 "OFF" ;
VAL_ 592 ADV_BacktrackFunctionInd 1 "ON" 0 "OFF" ;
VAL_ 593 ADV_BacktrackAbnormalTip 7 "Reserved" 0 "......" 4 "Reserved" 3 "Tip3" 2 "Tip2" 1 "Tip1" 0 "No tip" ;
VAL_ 593 ADV_LeftSlotSearchType 3 "All" 2 "Parallel" 1 "Perpedicular" 0 "Inactive" ;
VAL_ 593 ADV_RightSlotSearchType 3 "All" 2 "Parallel" 1 "Perpedicular" 0 "Inactive" ;
VAL_ 593 ADV_PDCSchedule 3 "Reserved" 2 "Reserved" 1 "Sensor one time" 0 "No Request" ;
VAL_ 593 ADV_APAFuncntion_SpeechControlFe 7 "Reserved" 6 "Reserved" 5 "Reserved" 4 "On failure" 3 "On success" 2 "Off failure" 1 "Off success" 0 "Inactive" ;
VAL_ 593 ADV_ParkInMode_SpeechControlFeed 7 "Reserved" 6 "Reserved" 5 "Reserved" 4 "Manual failure" 3 "Manual success" 2 "Auto failure" 1 "Auto success" 0 "Inactive" ;
VAL_ 593 ADV_ParkInType_SpeechControlFeed 7 "Reserved" 0 "......" 9 "Reserved" 8 "Auto failure" 7 "Auto success" 6 "Oblique failure" 5 "Oblique success" 4 "Perpendicular failure" 3 "Perpendicular success" 2 "Parallel failure" 1 "Parallel success" 0 "Inactive" ;
VAL_ 593 ADV_ParkOutFunc_SpeechControlFee 7 "Reserved" 6 "Reserved" 5 "Reserved" 4 "On failure" 3 "On success" 2 "Off failure" 1 "Off success" 0 "Inactive" ;
VAL_ 593 ADV_ParkOutType_SpeechControlFee 15 "Reserved" 14 "Reserved" 13 "Reserved" 12 "Reserved" 11 "Reserved" 10 "Reserved" 9 "Reserved" 8 "Right parallel failure" 7 "Right parallel success" 6 "Left parallel failure" 5 "Left parallel success" 4 "Rear perpendicular failure" 3 "Rear perpendicular success" 2 "Front perpendicular failure" 1 "Front perpendicular success" 0 "Inactive" ;
VAL_ 593 ADV_PauseButtonDisplay 3 "Start with Gray" 2 "Pause" 1 "Start" 0 "Inactive" ;
VAL_ 613 HAD_SystemError_AVP 1 "Error" 0 "No error" ;
VAL_ 613 HAD_ParkingLotAvalableTip_AVP 7 "Reserved" 6 "Reserved" 5 "Reserved" 4 "Tip:This parking lot supports both valet parking and memory parking" 3 "Tip3:Aready in memoried AVP area" 2 "Tip2:Aready in AVP supported parking lot" 1 "Tip1:The AVP supported parking lot is at distance xx m" 0 "No tip" ;
VAL_ 613 HAD_AIUnavailableTip 1 "Tip£∫It is not in the AI supported place,AI will not be entered" 0 "No tip" ;
VAL_ 613 HAD_ValetModeTip_AVP 1 "AVP not available during Valet Mode" 0 "No tip" ;
VAL_ 613 HAD_ChangeLaneManualsuccess_Tip 1 "Active" 0 "Inactive" ;
VAL_ 613 HAD_SetdestinationFuncSt 1 "ON" 0 "Off" ;
VAL_ 613 HAD_SetdestinationTip 3 "Tip3:Destination is unkown,please notice the toll gate." 2 "Tip2:Destination is unkown,please notice the ramp" 1 "Tip1:Please set your destination" 0 "Inactive" ;
VAL_ 613 HAD_WorkingSt_HWP_Display 15 "Reserved" 14 "Reserved" 13 "Transit" 12 "Exit" 11 "Locked" 10 "Hold" 9 "Fallback_Stop" 8 "TOR-Urgent" 7 "TOR-Normal" 6 "TOR-Mild" 5 "Override_Longitudinal" 4 "Override_Lateral" 3 "Active" 2 "Available" 1 "Standby_Inhibit" 0 "Off" ;
VAL_ 613 HAD_TakeoverReq_L3 1 "Request" 0 "No request" ;
VAL_ 613 HAD_ChangeLaneManualFuncSt 1 "ON" 0 "Off" ;
VAL_ 613 HAD_WorkingSt_TJP_Display 15 "Reserved" 14 "Reserved" 13 "Transit" 12 "Exit" 11 "Locked" 10 "Hold" 9 "Fallback_Stop" 8 "TOR-Urgent" 7 "TOR-Normal" 6 "TOR-Mild" 5 "Override_Longitudinal" 4 "Override_Lateral" 3 "Active" 2 "Available" 1 "Standby_Inhibit" 0 "Off" ;
VAL_ 613 HAD_LateralTakeOverReq_L3 1 "Request" 0 "No request" ;
VAL_ 613 HAD_AutoDrivingStyle 3 "Sport" 2 "Aggressive" 1 "Conservative" 0 "Normal" ;
VAL_ 613 HAD_ChangeLaneAutoFuncSt 1 "ON" 0 "Off" ;
VAL_ 613 HAD_TOR_Tips 15 "Reserved" 14 "Reserved" 13 "Reserved" 12 "Reserved" 11 "Reserved" 10 "Please take off your sunglasses" 9 "Please take off your mask" 8 "Autopilot stopped already,please take over the car now" 7 "Autopilot is stopping,please take over the car quikly" 6 "Keep your seatbelt buckled" 5 "Keep the door/engine hook/lugguage door  close" 4 "Please take over the car " 3 "ADAS System fault,please take over the car" 2 "Unexpected object ahead,please take over the car" 1 "No autopilot supported road ahead,please take over the car" 0 "Inactive" ;
VAL_ 613 HAD_AutoDrivingNotSatisfiedCondi 15 "Reserved" 14 "The autopilot is not available" 13 "The autopilot is temporarily unavailable please try again later" 12 "Unable to activate autopilot in valet mode" 11 "Step on the pedal gently and resume autopilot" 10 "The current ignition cycle is not active" 9 "Please take off your sunglasses" 8 "Please take off your mask" 7 "Turn drive mode to normal mode" 6 "Keep engine hook/lugguage door closed" 5 "Keep your seatbelt buckled" 4 "Turn off the hazard light" 3 "Keep the door close" 2 "ADAS System fault" 1 "No autopilot supported road ahead" 0 "Inactive" ;
VAL_ 613 HAD_DistractionWarning 1 "Warning" 0 "No warning" ;
VAL_ 613 HAD_AttentionSt 1 "Not on road" 0 "On road" ;
VAL_ 613 HAD_TakeOverWarning_L3 7 "Reserved" 6 "Reserved" 5 "Reserved" 4 "Tip:Already stopped the car" 3 "Emergency warning" 2 "Medium warning" 1 "Slight warning" 0 "Inactive" ;
VAL_ 613 HAD_TakeOverSuccessTip_L3 7 "Reserved" 6 "Reserved" 5 "Reserved" 4 "Already take over the car by control the steering wheel" 3 "Already take over the car by pressing the acceleration padle" 2 "Already take over the car by pressing the brake padle" 1 "Already take over the car by AI switch" 0 "Inactive" ;
VAL_ 613 HAD_ChangeLaneManual_Feedback 7 "Change lane function backoff " 6 "The car is changing to rightt lane" 5 "Change to right lane request and the condition is satisfied" 4 "Change to right lane request but the condition is not satisfied" 3 "The car is changing to left lane" 2 "Change to left lane request and the condition is satisfied" 1 "Change to left lane request but the condition is not satisfied" 0 "Inactive" ;
VAL_ 613 HAD_ErrorSt_HWPTJP 1 "Error" 0 "No error" ;
VAL_ 613 HAD_Countdown_Takeover 7 "Reserved" 6 "Reserved" 5 "1s" 4 "2s" 3 "3s" 2 "4s" 1 "5s" 0 "Inactive" ;
VAL_ 613 HAD_Destinationtip_St 1 "On" 0 "Off" ;
VAL_ 613 HAD_Countdown_SafeStop 7 "Reserved" 6 "Reserved" 5 "Reserved" 4 "Safe stop" 3 "1s" 2 "2s" 1 "3s" 0 "Inactive" ;
VAL_ 613 HAD_SACCActiveForbidden 1 "Active" 0 "Inactive" ;
VAL_ 595 ADV_CIDLocationReq 1 "Request" 0 "No request" ;
VAL_ 595 ADV_PositionLightReq 3 "Reserved" 2 "On" 1 "Off" 0 "No Request" ;
VAL_ 595 ADV_FogLightReq_Front 3 "Reserved" 2 "On" 1 "Off" 0 "No Request" ;
VAL_ 595 ADV_FogLightReq_Rear 3 "Reserved" 2 "On" 1 "Off" 0 "No Request" ;
VAL_ 595 ADV_AVPHazardWarningFunctionInd 1 "On" 0 "Off" ;
VAL_ 595 ADV_HPAHazardWarningFunctionInd 1 "On" 0 "Off" ;
VAL_ 595 ADV_AVPTypeIndication 3 "Reserved" 2 "Navigation" 1 "Park Out" 0 "Park In" ;
VAL_ 595 ADV_AVPSearchingTypeInd 1 "Auto" 0 "Manual" ;
VAL_ 595 ADV_HPATypeIndication 3 "Reserved" 2 "Navigation" 1 "Park Out" 0 "Park In" ;
VAL_ 595 ADV_HPASearchingTypeInd 1 "Auto" 0 "Manual" ;
VAL_ 595 ADV_AVPParkingLotPushFunctionInd 1 "On" 0 "Off" ;
VAL_ 595 ADV_HPAParkingLotPushFunctionInd 1 "On" 0 "Off" ;
VAL_ 595 ADV_AVPNaviAvaialble 1 "Available" 0 "Not Available" ;
VAL_ 595 ADV_AVPParkInAvaialble 1 "Available" 0 "Not Available" ;
VAL_ 595 ADV_AVPParkOutAvaialble 1 "Available" 0 "Not Available" ;
VAL_ 595 ADV_AVPParkInReady 1 "Ready" 0 "Not ready" ;
VAL_ 595 ADV_AVPParkOutReady 1 "Ready" 0 "Not ready" ;
VAL_ 595 ADV_HPANaviAvaialble 1 "Available" 0 "Not Available" ;
VAL_ 595 ADV_HPAParkInAvaialble 1 "Available" 0 "Not Available" ;
VAL_ 595 ADV_HPAParkOutAvaialble 1 "Available" 0 "Not Available" ;
VAL_ 595 ADV_HPAParkInReady 1 "Ready" 0 "Not ready" ;
VAL_ 595 ADV_HPAParkOutReady 1 "Ready" 0 "Not ready" ;
VAL_ 595 ADV_AVPSuspendStatus 1 "Active" 0 "Inactive" ;
VAL_ 595 ADV_HPAFucntion_SpeechControlFee 7 "Reserved" 6 "Reserved" 5 "Reserved" 4 "On failure" 3 "On success" 2 "Off failure" 1 "Off success" 0 "Inactive" ;
VAL_ 595 ADV_SunRoofRequest 3 "Reserved" 2 "Close" 1 "Open" 0 "No Request" ;
VAL_ 595 ADV_AllWindowsCloseReq 3 "Reserved" 2 "Close" 1 "Reserved" 0 "No Request" ;
VAL_ 595 ADV_OvertakingLightReq 3 "Reserved" 2 "On" 1 "Off" 0 "No Request" ;
VAL_ 595 ADV_LowBeamReq 3 "Reserved" 2 "On" 1 "Off" 0 "No Request" ;
VAL_ 595 ADV_HighBeamReq 3 "Reserved" 2 "On" 1 "Off" 0 "No Request" ;
VAL_ 595 ADV_AntitheftAlarmReq 3 "Reserved" 2 "On" 1 "Off" 0 "No Request" ;
VAL_ 595 ADV_CeremonyModeReq 7 "Waiting for taking over" 5 "Vehicle Control-Abnormal or stop" 4 "Vehicle Control-Suspend" 3 "Vehicle Control-Moving" 2 "Vehicle Control-Starting" 1 "Starting vehicle" 0 "Inactive" ;
VAL_ 595 ADV_HornReq 1 "Active" 0 "Inactive" ;
VAL_ 595 ADV_AVPFucntion_SpeechControlFee 7 "Reserved" 6 "Reserved" 5 "Reserved" 4 "On failure" 3 "On success" 2 "Off failure" 1 "Off success" 0 "Inactive" ;
VAL_ 595 ADV_HPASuspendStatus 1 "Active" 0 "Inactive" ;
VAL_ 967 ADV_AVPFunctionTip 255 "Reserved" 254 "Reserved" 253 "Reserved" 252 "Reserved" 251 "Reserved" 250 "Reserved" 249 "Reserved" 248 "Reserved" 247 "Reserved" 246 "Reserved" 245 "Reserved" 244 "Reserved" 243 "Reserved" 242 "Reserved" 241 "Reserved" 240 "Reserved" 239 "Reserved" 238 "Reserved" 237 "Reserved" 236 "Reserved" 235 "Reserved" 234 "Reserved" 233 "Reserved" 232 "Reserved" 231 "Reserved" 230 "Reserved" 229 "Reserved" 228 "Reserved" 227 "Reserved" 226 "Reserved" 225 "Reserved" 224 "Reserved" 223 "Reserved" 222 "Reserved" 221 "Reserved" 220 "Reserved" 219 "Reserved" 218 "Reserved" 217 "Reserved" 216 "Reserved" 215 "Reserved" 214 "Reserved" 213 "Reserved" 212 "Reserved" 211 "Reserved" 210 "Reserved" 209 "Reserved" 208 "Reserved" 207 "Reserved" 206 "Reserved" 205 "Reserved" 204 "Reserved" 203 "Reserved" 202 "Reserved" 201 "Reserved" 200 "Reserved" 199 "Reserved" 198 "Reserved" 197 "Reserved" 196 "Reserved" 195 "Reserved" 194 "Reserved" 193 "Reserved" 192 "Reserved" 191 "Reserved" 190 "Reserved" 189 "Reserved" 188 "Reserved" 187 "Reserved" 186 "Reserved" 185 "Reserved" 184 "Reserved" 183 "Reserved" 182 "Reserved" 181 "Reserved" 180 "Reserved" 179 "Reserved" 178 "Reserved" 177 "Reserved" 176 "Reserved" 175 "Reserved" 174 "Reserved" 173 "Reserved" 172 "Reserved" 171 "Reserved" 170 "Reserved" 169 "Reserved" 168 "Reserved" 167 "Reserved" 166 "Reserved" 165 "Reserved" 164 "Reserved" 163 "Reserved" 162 "Reserved" 161 "Reserved" 160 "Reserved" 159 "Reserved" 158 "Reserved" 157 "Reserved" 156 "Reserved" 155 "Reserved" 154 "Reserved" 153 "Reserved" 152 "Reserved" 151 "Reserved" 150 "Reserved" 149 "Reserved" 148 "Reserved" 147 "Reserved" 146 "Reserved" 145 "Reserved" 144 "Reserved" 143 "Reserved" 142 "Reserved" 141 "Reserved" 140 "Reserved" 139 "Reserved" 138 "Reserved" 137 "Reserved" 136 "Reserved" 135 "Reserved" 134 "Reserved" 133 "Reserved" 132 "Reserved" 131 "Reserved" 130 "Reserved" 129 "Reserved" 128 "Reserved" 127 "Reserved" 126 "Reserved" 125 "Reserved" 124 "Reserved" 123 "Reserved" 122 "Reserved" 121 "Reserved" 120 "Reserved" 119 "Reserved" 118 "Reserved" 117 "Reserved" 116 "Reserved" 115 "Reserved" 114 "Reserved" 113 "Reserved" 112 "Reserved" 111 "Reserved" 110 "Reserved" 109 "Reserved" 108 "Reserved" 107 "Reserved" 106 "Reserved" 105 "Reserved" 104 "Reserved" 103 "Reserved" 102 "Reserved" 101 "Reserved" 100 "Reserved" 99 "Reserved" 98 "Reserved" 97 "Reserved" 96 "Reserved" 95 "Reserved" 94 "Reserved" 93 "Reserved" 92 "Reserved" 91 "Reserved" 90 "Reserved" 89 "Reserved" 88 "Reserved" 87 "Reserved" 86 "The car is about to come" 85 "Start park in tip" 84 "Disclaimer tip" 83 "Waiting for taking over time out,parking system exit and ig off" 82 "Press brake pedal and click ok to start parking" 81 "Charge port open" 80 "P lever,release EPB and active auto parking by press button or lock the car" 79 "Press brake pedal,release EPB,put into D/R lever and click ok to start parking" 78 "Waiting for taking over time out,please choose parking back or continue waiting" 77 "The car is unlocked by driver,parking suspend,please lock the car then press continue" 76 "Wirless charging,if stop charging" 75 "Wirless charge station founded" 74 "Wireless charge enquiry" 73 "The car has been dragged" 72 "Turn on AVP inside car" 71 "Confirm the surrounding environment" 70 "Crash,please check your car" 69 "Auto parking active,ECAS adjust cant response correctly" 68 "Auto parking active,rear mirror fold cant response correctly" 67 "Light system fault" 66 "Car inside monitor abnormal condition3" 65 "Car inside monitor abnormal condition2" 64 "Car inside monitor abnormal condition1" 63 "HPA Parking out finish,parking system exit in 1 minute" 62 "HPA Parking in finish,parking system exit in 5 seconds" 61 "AVP Parking out finish,parking system exit in 1 minute" 60 "AVP Parking in finish,parking system exit in 5 seconds" 59 "Arrive at the destinaton,end of navigation" 58 "AutoPilot record abnormal" 57 "HPA warning:create HPA map in suitable place" 56 "Located success,if active HPA" 55 "Located success,if active AVP" 54 "Parking spot is unavailable" 53 "No free parking spot founded" 52 "HPA surpported lot nearby" 51 "AVP supported parking lot nearby" 50 "Path planning failed" 49 "Locate failed" 48 "Power battery SOC low,parking system exit" 47 "Power battery SOC low,please deal with it quikly" 46 "4G signal lost" 45 "bluetooth signal missing,please be closer to vehicle or check your phone connecting" 44 "Abnormal tire pressure" 43 "Space Unknown" 42 "Vehicle In remote mode" 41 "Parking lot Space Insufficient" 40 "ECAS adjusting" 39 "Vehicle direction incorrect" 38 "EPS System Can't Response Correctly" 37 "driving brake  System Can't Response Correctly" 36 "AVS System Can't Response Correctly" 35 "ECAS system unavailable" 34 "Door System Can't Response Correctly" 33 "Remote control System Can't Response Correctly" 32 "Gear shift System Can't Response Correctly" 31 "Parking Brake System Can't Response Correctly" 30 "Forward-looking signal is unavailable" 29 "PDC Signal Interface Not Available " 28 "AVS Signal Interface Not Available " 27 "YAW Signal Interface Not Available " 26 "SAS Signal Interface Not Available " 25 "Comfort System Interface unavailable" 24 "IVI Interface Not Available" 23 "Vehicle Drive Interface Not Available" 22 "BLE system interface unavailable" 21 "Steering interface unavailable" 20 "Parking Brake Interface unavailable" 19 "Shift gears interface unavailable" 18 "Driving Brake Interface unavailable" 17 "SACC or LKA activated" 16 "Tracking error" 15 "Unable to switch vehicle mode" 14 "Parking surround space Insufficient" 13 "Obstacle is too close" 12 "Vehicle condition is not satisfied for auto parking,parking system exit" 11 "Door open" 10 "Cannot enter parking status " 9 "Speed too fast,system exit" 8 "Speed too fast,Please slow down" 7 "Parking cannot completed please take over" 6 "Road surface complexity " 5 "Gradient too high" 4 "Driver intervention EPB" 3 "Driver intervention steering wheel " 2 "Driver intervention brake pedal " 1 "Vehicle not started" 0 "Inactive" ;
VAL_ 967 ADV_HPAFunctionTip 255 "Reserved" 254 "Reserved" 253 "Reserved" 252 "Reserved" 251 "Reserved" 250 "Reserved" 249 "Reserved" 248 "Reserved" 247 "Reserved" 246 "Reserved" 245 "Reserved" 244 "Reserved" 243 "Reserved" 242 "Reserved" 241 "Reserved" 240 "Reserved" 239 "Reserved" 238 "Reserved" 237 "Reserved" 236 "Reserved" 235 "Reserved" 234 "Reserved" 233 "Reserved" 232 "Reserved" 231 "Reserved" 230 "Reserved" 229 "Reserved" 228 "Reserved" 227 "Reserved" 226 "Reserved" 225 "Reserved" 224 "Reserved" 223 "Reserved" 222 "Reserved" 221 "Reserved" 220 "Reserved" 219 "Reserved" 218 "Reserved" 217 "Reserved" 216 "Reserved" 215 "Reserved" 214 "Reserved" 213 "Reserved" 212 "Reserved" 211 "Reserved" 210 "Reserved" 209 "Reserved" 208 "Reserved" 207 "Reserved" 206 "Reserved" 205 "Reserved" 204 "Reserved" 203 "Reserved" 202 "Reserved" 201 "Reserved" 200 "Reserved" 199 "Reserved" 198 "Reserved" 197 "Reserved" 196 "Reserved" 195 "Reserved" 194 "Reserved" 193 "Reserved" 192 "Reserved" 191 "Reserved" 190 "Reserved" 189 "Reserved" 188 "Reserved" 187 "Reserved" 186 "Reserved" 185 "Reserved" 184 "Reserved" 183 "Reserved" 182 "Reserved" 181 "Reserved" 180 "Reserved" 179 "Reserved" 178 "Reserved" 177 "Reserved" 176 "Reserved" 175 "Reserved" 174 "Reserved" 173 "Reserved" 172 "Reserved" 171 "Reserved" 170 "Reserved" 169 "Reserved" 168 "Reserved" 167 "Reserved" 166 "Reserved" 165 "Reserved" 164 "Reserved" 163 "Reserved" 162 "Reserved" 161 "Reserved" 160 "Reserved" 159 "Reserved" 158 "Reserved" 157 "Reserved" 156 "Reserved" 155 "Reserved" 154 "Reserved" 153 "Reserved" 152 "Reserved" 151 "Reserved" 150 "Reserved" 149 "Reserved" 148 "Reserved" 147 "Reserved" 146 "Reserved" 145 "Reserved" 144 "Reserved" 143 "Reserved" 142 "Reserved" 141 "Reserved" 140 "Reserved" 139 "Reserved" 138 "Reserved" 137 "Reserved" 136 "Reserved" 135 "Reserved" 134 "Reserved" 133 "Reserved" 132 "Reserved" 131 "Reserved" 130 "Reserved" 129 "Reserved" 128 "Reserved" 127 "Reserved" 126 "Reserved" 125 "Reserved" 124 "Reserved" 123 "Reserved" 122 "Reserved" 121 "Reserved" 120 "Reserved" 119 "Reserved" 118 "Reserved" 117 "Reserved" 116 "Reserved" 115 "Reserved" 114 "Reserved" 113 "Reserved" 112 "Reserved" 111 "Reserved" 110 "Reserved" 109 "Reserved" 108 "Reserved" 107 "Reserved" 106 "Reserved" 105 "Reserved" 104 "Reserved" 103 "Reserved" 102 "Reserved" 101 "Reserved" 100 "Reserved" 99 "Reserved" 98 "Reserved" 97 "Reserved" 96 "Reserved" 95 "Reserved" 94 "Reserved" 93 "Reserved" 92 "Reserved" 91 "Reserved" 90 "Reserved" 89 "Reserved" 88 "Reserved" 87 "Reserved" 86 "The car is about to come" 85 "Start park in tip" 84 "Disclaimer tip" 83 "Waiting for taking over time out,parking system exit and ig off" 82 "Press brake pedal and click ok to start parking" 81 "Charge port open" 80 "P lever,release EPB and active auto parking by press button or lock the car" 79 "Press brake pedal,release EPB,put into D/R lever and click ok to start parking" 78 "Waiting for taking over time out,please choose parking back or continue waiting" 77 "The car is unlocked by driver,parking suspend,please lock the car then press continue" 76 "Wirless charging,if stop charging" 75 "Wirless charge station founded" 74 "Wireless charge enquiry" 73 "The car has been dragged" 72 "Turn on AVP inside car" 71 "Confirm the surrounding environment" 70 "Crash,please check your car" 69 "Auto parking active,ECAS adjust cant response correctly" 68 "Auto parking active,rear mirror fold cant response correctly" 67 "Light system fault" 66 "Car inside monitor abnormal condition3" 65 "Car inside monitor abnormal condition2" 64 "Car inside monitor abnormal condition1" 63 "HPA Parking out finish,parking system exit in 1 minute" 62 "HPA Parking in finish,parking system exit in 5 seconds" 61 "AVP Parking out finish,parking system exit in 1 minute" 60 "AVP Parking in finish,parking system exit in 5 seconds" 59 "Arrive at the destinaton,end of navigation" 58 "AutoPilot record abnormal" 57 "HPA warning:create HPA map in suitable place" 56 "Located success,if active HPA" 55 "Located success,if active AVP" 54 "Parking spot is unavailable" 53 "No free parking spot founded" 52 "HPA surpported lot nearby" 51 "AVP supported parking lot nearby" 50 "Path planning failed" 49 "Locate failed" 48 "Power battery SOC low,parking system exit" 47 "Power battery SOC low,please deal with it quikly" 46 "4G signal lost" 45 "bluetooth signal missing,please be closer to vehicle or check your phone connecting" 44 "Abnormal tire pressure" 43 "Space Unknown" 42 "Vehicle In remote mode" 41 "Parking lot Space Insufficient" 40 "ECAS adjusting" 39 "Vehicle direction incorrect" 38 "EPS System Can't Response Correctly" 37 "driving brake  System Can't Response Correctly" 36 "AVS System Can't Response Correctly" 35 "ECAS system unavailable" 34 "Door System Can't Response Correctly" 33 "Remote control System Can't Response Correctly" 32 "Gear shift System Can't Response Correctly" 31 "Parking Brake System Can't Response Correctly" 30 "Forward-looking signal is unavailable" 29 "PDC Signal Interface Not Available " 28 "AVS Signal Interface Not Available " 27 "YAW Signal Interface Not Available " 26 "SAS Signal Interface Not Available " 25 "Comfort System Interface unavailable" 24 "IVI Interface Not Available" 23 "Vehicle Drive Interface Not Available" 22 "BLE system interface unavailable" 21 "Steering interface unavailable" 20 "Parking Brake Interface unavailable" 19 "Shift gears interface unavailable" 18 "Driving Brake Interface unavailable" 17 "SACC or LKA activated" 16 "Tracking error" 15 "Unable to switch vehicle mode" 14 "Parking surround space Insufficient" 13 "Obstacle is too close" 12 "Vehicle condition is not satisfied for auto parking,parking system exit" 11 "Door open" 10 "Cannot enter parking status " 9 "Speed too fast,system exit" 8 "Speed too fast,Please slow down" 7 "Parking cannot completed please take over" 6 "Road surface complexity " 5 "Gradient too high" 4 "Driver intervention EPB" 3 "Driver intervention steering wheel " 2 "Driver intervention brake pedal " 1 "Vehicle not started" 0 "Inactive" ;
VAL_ 967 ADV_AVPStatus 31 "Reserved" 30 "Reserved" 29 "Reserved" 28 "Reserved" 27 "Reserved" 26 "Reserved" 25 "Reserved" 24 "Reserved" 23 "Reserved" 22 "Reserved" 21 "Reserved" 20 "Reserved" 19 "Reserved" 18 "AVP Park out destination" 17 "AVP out Finish" 16 "AVP in Finish" 15 "Navi Finish" 14 "Abort" 13 "Suspend" 12 "AVP parking out" 11 "AVP driving out " 10 "AVP parking in" 9 "AVP driving in" 8 "AVP auto searching" 7 "Navigating" 6 "Navi destination selecting" 5 "AVP auto park in destination selecting" 4 "AVP manual park in destination selecting" 3 "AVP localizationing" 2 "AVP map selecting" 1 "Standby" 0 "Off" ;
VAL_ 967 ADV_HPAStatus 31 "Reserved" 30 "Reserved" 29 "Reserved" 28 "Reserved" 27 "Reserved" 26 "Reserved" 25 "Reserved" 24 "Reserved" 23 "Reserved" 22 "Reserved" 21 "Reserved" 20 "Reserved" 19 "Reserved" 18 "Reserved" 17 "Reserved" 16 "HPA out Finish" 15 "HPA in Finish" 14 "Abort" 13 "Suspend" 12 "HPA parking out" 11 "HPA driving out " 10 "HPA parking in" 9 "HPA driving in" 8 "HPA park out destination confirming" 7 "HPA park in destination confirming" 6 "HPA localizationing" 5 "HPA map selecting" 4 "HPA slot configuring" 3 "HPA map Uploading" 2 "HPA map recording" 1 "Standby" 0 "OFF" ;
VAL_ 967 ADV_CeromonyModeReq_AtmosphereLi 3 "Reserved" 2 "Flowing mode" 1 "Reserved" 0 "No request" ;
VAL_ 967 ADV_CeromonyModeReq_CPillerLight 3 "Reserved" 2 "Flowing mode" 1 "Breathe mode" 0 "No request" ;
VAL_ 967 ADV_BreatheFreqReq_CPillerLight 7 "Reserved" 6 "Reserved" 5 "Reserved" 4 "Reserved" 3 "2Hz" 2 "1Hz" 1 "0.5Hz" 0 "No request" ;
VAL_ 967 ADV_ColorReq_CPillerLight 7 "Reserved" 6 "Purple" 5 "Green" 4 "Red" 3 "Blue" 2 "Yellow" 1 "Reserved" 0 "Off" ;
VAL_ 967 ADV_CeromonyModeReq_FrontGrilleL 3 "Reserved" 2 "Flowing mode" 1 "Breathe mode" 0 "No request" ;
VAL_ 967 ADV_BreatheFreqReq_FrontGrilleLi 7 "Reserved" 6 "Reserved" 5 "Reserved" 4 "Reserved" 3 "2Hz" 2 "1Hz" 1 "0.5Hz" 0 "No request" ;
VAL_ 967 ADV_ColorReq_FrontGrilleLight 7 "Reserved" 6 "Purple" 5 "Green" 4 "Red" 3 "Blue" 2 "Yellow" 1 "Reserved" 0 "Off" ;
VAL_ 967 ADV_WOBCStopChargeReq 1 "Active" 0 "Inactive" ;
VAL_ 967 ADV_WOBCEnquiryConfirm 3 "Reserved" 2 "Refused" 1 "Agreed" 0 "Inactive" ;
VAL_ 600 AVSSt 1 "On" 0 "Off" ;
VAL_ 600 AVSErrorSt 1 "Error" 0 "No error" ;
VAL_ 600 AVSViewMode 15 "Invalid value" 14 "Calibration Mode" 13 "Factory Mode" 12 "Reserved" 11 "Screen Dragged 3D View" 10 "Rear Rim view" 9 "Front Rim view" 8 "Reserved" 7 "Rear Wide View" 6 "Front Wide View" 5 "Top View and Right View" 4 "Top View and Left View" 3 "Top View and Rear View" 2 "Top View and Front View" 1 "All Top View" 0 "Inactive" ;
VAL_ 600 AVSViewtype 3 "Reserved" 2 "Reserved" 1 "3D" 0 "2D" ;
VAL_ 600 AVSCameraErrorSt_Front 1 "Error" 0 "No error" ;
VAL_ 600 AVSCameraErrorSt_Rear 1 "Error" 0 "No error" ;
VAL_ 600 AVSCameraErrorSt_Left 1 "Error" 0 "No error" ;
VAL_ 600 AVSCameraErrorSt_Right 1 "Error" 0 "No error" ;
VAL_ 600 LanguageTypeSt_AVS 15 "Reserved" 14 "Reserved" 13 "Reserved" 12 "Reserved" 11 "Reserved" 10 "Reserved" 9 "Reserved" 8 "Reserved" 7 "Reserved" 6 "Reserved" 5 "Russian" 4 "Arabic" 3 "French" 2 "English" 1 "Traditional Chinese" 0 "Simple Chinese" ;
VAL_ 600 DynamicPGSSt_AVS 1 "On" 0 "Off" ;
VAL_ 600 MODSt_AVS 1 "On" 0 "Off" ;
VAL_ 600 MODWarning_Front 1 "Warning" 0 "No warning" ;
VAL_ 600 MODWarning_Rear 1 "Warning" 0 "No warning" ;
VAL_ 600 SwitchScreenRequest_AVS 3 "Reserved" 2 "AVS Exit Request" 1 "AVS Enter Request" 0 "Inactive" ;
VAL_ 600 BlindSpotFilledFunctionInd 1 "ON" 0 "OFF" ;
VAL_ 600 FoundSlotBuzzerTip 1 "Active" 0 "Inactive" ;
VAL_ 600 AVS_SpeechControlFeedback 31 "Reserved" 30 "Reserved" 29 "Reserved" 28 "Reserved" 27 "Reserved" 26 "Reserved" 25 "Reserved" 24 "Rear Rim view Failure" 23 "Rear Rim view Success" 22 "Front Rim view Failure" 21 "Front Rim view Success" 20 "Reserved" 19 "Reserved" 18 "Rear Wide View  Failure" 17 "Rear Wide View Success" 16 "Front Wide View  Failure" 15 "Front Wide View Success" 14 "Top View and Right View Failure" 13 "Top View and Right View Success" 12 "Top View and Left View Failure" 11 "Top View and Left View Success" 10 "Top View and Rear View Failure" 9 "Top View and Rear View Success" 8 "Top View and Front View Failure" 7 "Top View and Front View Success" 6 "All Top View Failure" 5 "All Top View Success" 4 "On Failure" 3 "On Success" 2 "Off Failure" 1 "Off Success" 0 "Inactive" ;
VAL_ 600 AVSCameraBlockageSt_Front 1 "Blockage" 0 "No Blockage" ;
VAL_ 600 AVSCameraBlockageSt_Rear 1 "Blockage" 0 "No Blockage" ;
VAL_ 600 AVSCameraBlockageSt_Left 1 "Blockage" 0 "No Blockage" ;
VAL_ 600 AVSCameraBlockageSt_Right 1 "Blockage" 0 "No Blockage" ;
VAL_ 600 AVS_AbnormalTip 7 "Reserved" 6 "Reserved" 5 "Reserved" 4 "Reserved" 3 "Reserved" 2 "Reserved" 1 "Speed too high" 0 "Inactive" ;
VAL_ 600 AVS_CalibrationSt 3 "Reserved" 2 "Calibrated" 1 "Calibrating" 0 "Not calibrated" ;
VAL_ 600 AVS_PDWarning_Front 1 "Warning" 0 "No warning" ;
VAL_ 600 AVS_PDWarning_Rear 1 "Warning" 0 "No warning" ;
VAL_ 600 AVS_RemoteMonitorigFeedback 7 "Reserved" 6 "Reserved" 5 "Reserved" 4 "Reserved" 3 "Reserved" 2 "Reserved" 1 "Reserved" 4 "On Failure" 3 "On Success" 2 "Off Failure" 1 "Off Success" 0 "Inactive" ;
VAL_ 600 AVS_RemoteSharpnessFeedback 7 "Reserved" 6 "Reserved" 5 "Reserved" 4 "Reserved" 3 "Reserved" 2 "Reserved" 1 "Reserved" 4 "HD Failure" 3 "HD Success" 2 "SD Failure" 1 "SD Success" 0 "Inactive" ;
VAL_ 600 RemoteMonitoringSharpnessSt_AVS 1 "HD" 0 "SD" ;
VAL_ 600 RemoteMonitoringSt_AVS 1 "On" 0 "Off" ;
VAL_ 600 RemoteMonitoringModeSt_AVS 1 "Vedio Mode" 0 "Picture Mode" ;
VAL_ 600 AVS_RemoteViewModeFeedback 31 "Reserved" 30 "Reserved" 29 "Reserved" 28 "Reserved" 27 "Reserved" 26 "Reserved" 25 "Reserved" 24 "Rear Rim view Failure" 23 "Rear Rim view Success" 22 "Front Rim view Failure" 21 "Front Rim view Success" 20 "Reserved" 19 "Reserved" 18 "Rear Wide View  Failure" 17 "Rear Wide View Success" 16 "Front Wide View  Failure" 15 "Front Wide View Success" 14 "Top View and Right View Failure" 13 "Top View and Right View Success" 12 "Top View and Left View Failure" 11 "Top View and Left View Success" 10 "Top View and Rear View Failure" 9 "Top View and Rear View Success" 8 "Top View and Front View Failure" 7 "Top View and Front View Success" 6 "All Top View Failure" 5 "All Top View Success" 4 "On Failure" 3 "On Success" 2 "Off Failure" 1 "Off Success" 0 "Inactive" ;
VAL_ 599 AVP_AutoDriveDataRecordAvailable 1 "Available" 0 "Not available" ;
VAL_ 599 AVP_AutoDriveDataRecordStatus 3 "Error" 2 "Active" 1 "Standby" 0 "Off" ;
VAL_ 604 SysSt_PDC 1 "On" 0 "Off" ;
VAL_ 604 ErrorSt_PDC 1 "Error" 0 "No error" ;
VAL_ 604 RadarSysSt_Front 1 "On" 0 "Off" ;
VAL_ 604 RadarSysSt_Rear 1 "On" 0 "Off" ;
VAL_ 604 BuzeerCmd_PDC 7 "Level 5(Low Frequency Tone)" 6 "Level 4" 5 "Self check ok tone" 4 "Self check error tone" 3 "Level 3" 2 "Level 2" 1 "Level 1(Continuous tone)" 0 "Inactive" ;
VAL_ 604 BuzzerAlarmPosition 7 "Reserved" 6 "Reserved" 5 "Reserved" 4 "Front + Rear" 3 "SelfCheck" 2 "Rear" 1 "Front" 0 "Off" ;
VAL_ 604 RadarSysSt_FrontSide 1 "On" 0 "Off" ;
VAL_ 604 RadarSysSt_RearSide 1 "On" 0 "Off" ;
VAL_ 604 BuzzerSwitchSt 1 "On" 0 "Off" ;
VAL_ 604 ObjectRange_RR 7 "Invalid Value" 6 "Range 6" 5 "Range 5" 4 "Range 4" 3 "Range 3" 2 "Range 2" 1 "Range 1" 0 "No Object" ;
VAL_ 604 SensorErrorSt_RR 1 "Error" 0 "No error" ;
VAL_ 604 ObjectRange_RMR 7 "Invalid Value" 6 "Range 6" 5 "Range 5" 4 "Range 4" 3 "Range 3" 2 "Range 2" 1 "Range 1" 0 "No Object" ;
VAL_ 604 SensorErrorSt_RMR 1 "Error" 0 "No error" ;
VAL_ 604 ObjectRange_RML 7 "Invalid Value" 6 "Range 6" 5 "Range 5" 4 "Range 4" 3 "Range 3" 2 "Range 2" 1 "Range 1" 0 "No Object" ;
VAL_ 604 SensorErrorSt_RML 1 "Error" 0 "No error" ;
VAL_ 604 ObjectRange_RL 7 "Invalid Value" 6 "Range 6" 5 "Range 5" 4 "Range 4" 3 "Range 3" 2 "Range 2" 1 "Range 1" 0 "No Object" ;
VAL_ 604 SensorErrorSt_RL 1 "Error" 0 "No error" ;
VAL_ 604 ObjectRange_FR 7 "Invalid Value" 6 "Range 6" 5 "Range 5" 4 "Range 4" 3 "Range 3" 2 "Range 2" 1 "Range 1" 0 "No Object" ;
VAL_ 604 SensorErrorSt_FR 1 "Error" 0 "No error" ;
VAL_ 604 ObjectRange_FMR 7 "Invalid Value" 6 "Range 6" 5 "Range 5" 4 "Range 4" 3 "Range 3" 2 "Range 2" 1 "Range 1" 0 "No Object" ;
VAL_ 604 SensorErrorSt_FMR 1 "Error" 0 "No error" ;
VAL_ 604 ObjectRange_FML 7 "Invalid Value" 6 "Range 6" 5 "Range 5" 4 "Range 4" 3 "Range 3" 2 "Range 2" 1 "Range 1" 0 "No Object" ;
VAL_ 604 SensorErrorSt_FML 1 "Error" 0 "No error" ;
VAL_ 604 ObjectRange_FL 7 "Invalid Value" 6 "Range 6" 5 "Range 5" 4 "Range 4" 3 "Range 3" 2 "Range 2" 1 "Range 1" 0 "No Object" ;
VAL_ 604 SensorErrorSt_FL 1 "Error" 0 "No error" ;
VAL_ 604 PDCAutoOnFunctionInd 1 "On" 0 "Off" ;
VAL_ 604 SwitchScreenRequest_PDC 3 "Reserved" 2 "PDC Display Exit Request" 1 "PDC Display Enter Request" 0 "Inactive" ;
VAL_ 604 PDC_SpeechControlFeedback 7 "Reserved" 6 "Reserved" 5 "Reserved" 4 "On Failure" 3 "On Success" 2 "Off Failure" 1 "Off Success" 0 "Inactive" ;
VAL_ 604 PDC_SearchingSlotPosition 3 "Right & Left" 2 "Left" 1 "Right" 0 "Inactive" ;
VAL_ 604 PDC_FunctionTip 7 "Reserved" 6 "Searching both slot failure" 5 "Searching both slot success" 4 "Searching left slot success" 3 "Searching left slot failure" 2 "Searching right slot success" 1 "Searching right slot failure" 0 "Inactive" ;
VAL_ 456 CCoordinateY_Left 1023 "SNA" ;
VAL_ 456 CCoordinateX_Left 4095 "SNA" ;
VAL_ 456 DCoordinateY_Left 1023 "SNA" ;
VAL_ 456 DCoordinateX_Left 4095 "SNA" ;
